VERSION ""

NS_ :

BS_:

BU_: AHL_ELCB LDM_L_ELCB LDM_R_ELCB

BO_ 3221225472 VECTOR__INDEPENDENT_SIG_MSG: 0 Vector__XXX
 SG_ FuncDiagReq : 0|64@0+ (1,0) [0|1.84467440737096E+019] "" Vector__XXX
 SG_ LftPhyDiagReq : 0|64@0+ (1,0) [0|1.84467440737096E+019] "" Vector__XXX
 SG_ RghtPhyDiagReq : 0|64@0+ (1,0) [0|1.84467440737096E+019] "" Vector__XXX
 SG_ LftPhyDiagResp : 0|64@0+ (1,0) [0|1.84467440737096E+019] "" Vector__XXX
 SG_ RghtPhyDiagResp : 0|64@0+ (1,0) [0|1.84467440737096E+019] "" Vector__XXX
 SG_ HdlmpLvlgMtrRtdCurr : 0|11@1+ (1,0) [0|2047] "" Vector__XXX

BO_ 516 StaticBendingCmd: 6 AHL_ELCB
 SG_ RtBndDim : 15|8@0+ (0.5,0) [0|0] "" Vector__XXX
 SG_ LftBndDim : 7|8@0+ (0.5,0) [0|0] "" Vector__XXX

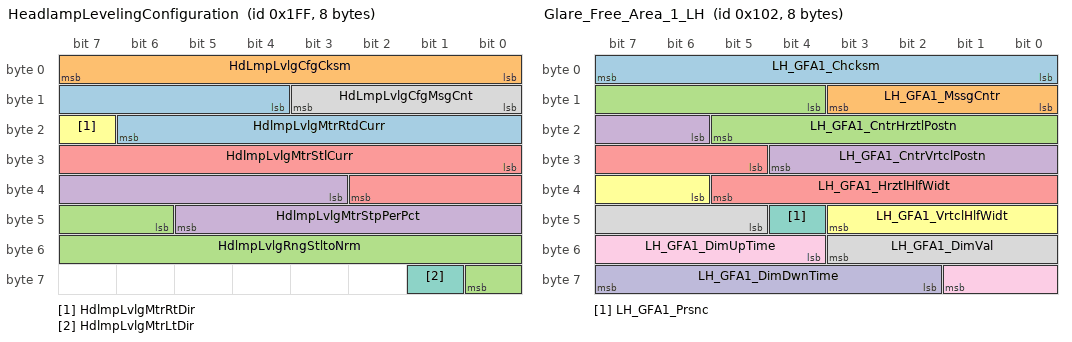
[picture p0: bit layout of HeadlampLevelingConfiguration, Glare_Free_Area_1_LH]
BO_ 511 HeadlampLevelingConfiguration: 8 AHL_ELCB
 SG_ HdlmpLvlgMtrRtdCurr : 12|11@1+ (1,0) [0|0] "" Vector__XXX
 SG_ HdLmpLvlgCfgCksm : 0|8@1+ (1,0) [0|0] "" Vector__XXX
 SG_ HdlmpLvlgRngStltoNrm : 46|11@1+ (0.01,0) [0|0] "" Vector__XXX
 SG_ HdlmpLvlgMtrStpPerPct : 35|11@1+ (1,0) [0|0] "" Vector__XXX
 SG_ HdlmpLvlgMtrStlCurr : 24|11@1- (1,0) [-1024|1023] "" Vector__XXX
 SG_ HdlmpLvlgMtrRtDir : 23|1@1+ (1,0) [0|0] "" Vector__XXX
 SG_ HdlmpLvlgMtrLtDir : 57|1@1+ (1,0) [0|0] "" Vector__XXX
 SG_ HdLmpLvlgCfgMsgCnt : 8|4@1+ (1,0) [0|0] "" Vector__XXX

BO_ 258 Glare_Free_Area_1_LH: 8 AHL_ELCB
 SG_ LH_GFA1_Chcksm : 0|8@1+ (1,0) [0|255] ""  LDM_L_ELCB,LDM_R_ELCB
 SG_ LH_GFA1_MssgCntr : 8|4@1+ (1,0) [0|15] ""  LDM_L_ELCB,LDM_R_ELCB
 SG_ LH_GFA1_CntrHrztlPostn : 12|10@1- (0.1,0) [-51.2|51.1] "deg"  LDM_L_ELCB,LDM_R_ELCB
 SG_ LH_GFA1_CntrVrtclPostn : 22|7@1- (0.1,0) [-6.4|6.3] "deg"  LDM_L_ELCB,LDM_R_ELCB
 SG_ LH_GFA1_HrztlHlfWidt : 29|9@1+ (0.1,0) [0|51.1] "deg"  LDM_L_ELCB,LDM_R_ELCB
 SG_ LH_GFA1_VrtclHlfWidt : 38|6@1+ (0.1,0) [0|6.3] "deg"  LDM_L_ELCB,LDM_R_ELCB
 SG_ LH_GFA1_Prsnc : 44|1@1+ (1,0) [0|1] ""  LDM_L_ELCB,LDM_R_ELCB
 SG_ LH_GFA1_DimVal : 45|7@1+ (1,0) [0|100] "%"  LDM_L_ELCB,LDM_R_ELCB
 SG_ LH_GFA1_DimUpTime : 52|6@1+ (0.05,0) [0|3.15] "s"  LDM_L_ELCB,LDM_R_ELCB
 SG_ LH_GFA1_DimDwnTime : 58|6@1+ (0.05,0) [0|3.15] "s"  LDM_L_ELCB,LDM_R_ELCB

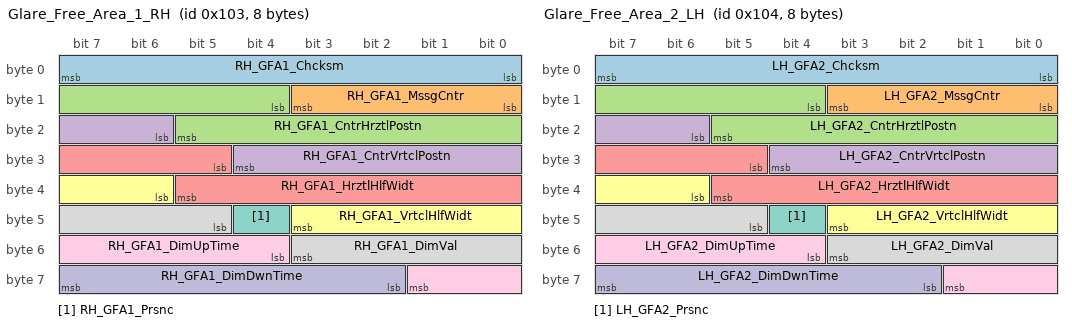
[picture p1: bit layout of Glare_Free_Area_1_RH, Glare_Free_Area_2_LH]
BO_ 259 Glare_Free_Area_1_RH: 8 AHL_ELCB
 SG_ RH_GFA1_Chcksm : 0|8@1+ (1,0) [0|255] ""  LDM_L_ELCB,LDM_R_ELCB
 SG_ RH_GFA1_MssgCntr : 8|4@1+ (1,0) [0|15] ""  LDM_L_ELCB,LDM_R_ELCB
 SG_ RH_GFA1_CntrHrztlPostn : 12|10@1- (0.1,0) [-51.2|51.1] "deg"  LDM_L_ELCB,LDM_R_ELCB
 SG_ RH_GFA1_CntrVrtclPostn : 22|7@1- (0.1,0) [-6.4|6.3] "deg"  LDM_L_ELCB,LDM_R_ELCB
 SG_ RH_GFA1_HrztlHlfWidt : 29|9@1+ (0.1,0) [0|51.1] "deg"  LDM_L_ELCB,LDM_R_ELCB
 SG_ RH_GFA1_VrtclHlfWidt : 38|6@1+ (0.1,0) [0|6.3] "deg"  LDM_L_ELCB,LDM_R_ELCB
 SG_ RH_GFA1_Prsnc : 44|1@1+ (1,0) [0|1] ""  LDM_L_ELCB,LDM_R_ELCB
 SG_ RH_GFA1_DimVal : 45|7@1+ (1,0) [0|100] "%"  LDM_L_ELCB,LDM_R_ELCB
 SG_ RH_GFA1_DimUpTime : 52|6@1+ (0.05,0) [0|3.15] "s"  LDM_L_ELCB,LDM_R_ELCB
 SG_ RH_GFA1_DimDwnTime : 58|6@1+ (0.05,0) [0|3.15] "s"  LDM_L_ELCB,LDM_R_ELCB

BO_ 260 Glare_Free_Area_2_LH: 8 AHL_ELCB
 SG_ LH_GFA2_Chcksm : 0|8@1+ (1,0) [0|255] ""  LDM_L_ELCB,LDM_R_ELCB
 SG_ LH_GFA2_MssgCntr : 8|4@1+ (1,0) [0|15] ""  LDM_L_ELCB,LDM_R_ELCB
 SG_ LH_GFA2_CntrHrztlPostn : 12|10@1- (0.1,0) [-51.2|51.1] "deg"  LDM_L_ELCB,LDM_R_ELCB
 SG_ LH_GFA2_CntrVrtclPostn : 22|7@1- (0.1,0) [-6.4|6.3] "deg"  LDM_L_ELCB,LDM_R_ELCB
 SG_ LH_GFA2_HrztlHlfWidt : 29|9@1+ (0.1,0) [0|51.1] "deg"  LDM_L_ELCB,LDM_R_ELCB
 SG_ LH_GFA2_VrtclHlfWidt : 38|6@1+ (0.1,0) [0|6.3] "deg"  LDM_L_ELCB,LDM_R_ELCB
 SG_ LH_GFA2_Prsnc : 44|1@1+ (1,0) [0|1] ""  LDM_L_ELCB,LDM_R_ELCB
 SG_ LH_GFA2_DimVal : 45|7@1+ (1,0) [0|100] "%"  LDM_L_ELCB,LDM_R_ELCB
 SG_ LH_GFA2_DimUpTime : 52|6@1+ (0.05,0) [0|3.15] "s"  LDM_L_ELCB,LDM_R_ELCB
 SG_ LH_GFA2_DimDwnTime : 58|6@1+ (0.05,0) [0|3.15] "s"  LDM_L_ELCB,LDM_R_ELCB

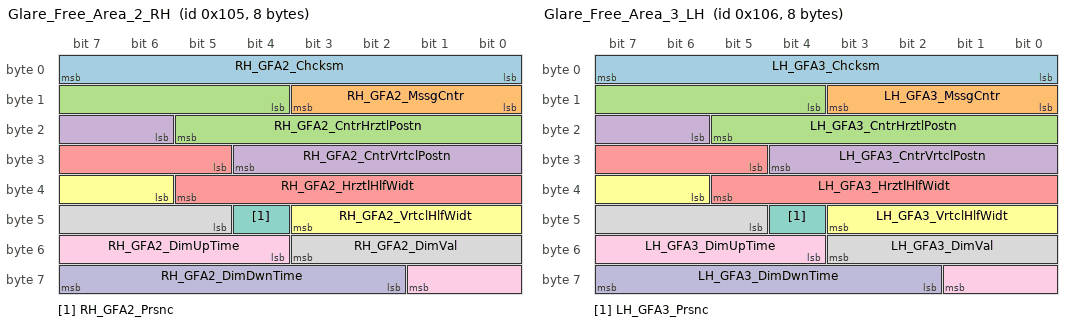
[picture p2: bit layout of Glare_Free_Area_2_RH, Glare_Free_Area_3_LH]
BO_ 261 Glare_Free_Area_2_RH: 8 AHL_ELCB
 SG_ RH_GFA2_Chcksm : 0|8@1+ (1,0) [0|255] ""  LDM_L_ELCB,LDM_R_ELCB
 SG_ RH_GFA2_MssgCntr : 8|4@1+ (1,0) [0|15] ""  LDM_L_ELCB,LDM_R_ELCB
 SG_ RH_GFA2_CntrHrztlPostn : 12|10@1- (0.1,0) [-51.2|51.1] "deg"  LDM_L_ELCB,LDM_R_ELCB
 SG_ RH_GFA2_CntrVrtclPostn : 22|7@1- (0.1,0) [-6.4|6.3] "deg"  LDM_L_ELCB,LDM_R_ELCB
 SG_ RH_GFA2_HrztlHlfWidt : 29|9@1+ (0.1,0) [0|51.1] "deg"  LDM_L_ELCB,LDM_R_ELCB
 SG_ RH_GFA2_VrtclHlfWidt : 38|6@1+ (0.1,0) [0|6.3] "deg"  LDM_L_ELCB,LDM_R_ELCB
 SG_ RH_GFA2_Prsnc : 44|1@1+ (1,0) [0|1] ""  LDM_L_ELCB,LDM_R_ELCB
 SG_ RH_GFA2_DimVal : 45|7@1+ (1,0) [0|100] "%"  LDM_L_ELCB,LDM_R_ELCB
 SG_ RH_GFA2_DimUpTime : 52|6@1+ (0.05,0) [0|3.15] "s"  LDM_L_ELCB,LDM_R_ELCB
 SG_ RH_GFA2_DimDwnTime : 58|6@1+ (0.05,0) [0|3.15] "s"  LDM_L_ELCB,LDM_R_ELCB

BO_ 262 Glare_Free_Area_3_LH: 8 AHL_ELCB
 SG_ LH_GFA3_Chcksm : 0|8@1+ (1,0) [0|255] ""  LDM_L_ELCB,LDM_R_ELCB
 SG_ LH_GFA3_MssgCntr : 8|4@1+ (1,0) [0|15] ""  LDM_L_ELCB,LDM_R_ELCB
 SG_ LH_GFA3_CntrHrztlPostn : 12|10@1- (0.1,0) [-51.2|51.1] "deg"  LDM_L_ELCB,LDM_R_ELCB
 SG_ LH_GFA3_CntrVrtclPostn : 22|7@1- (0.1,0) [-6.4|6.3] "deg"  LDM_L_ELCB,LDM_R_ELCB
 SG_ LH_GFA3_HrztlHlfWidt : 29|9@1+ (0.1,0) [0|51.1] "deg"  LDM_L_ELCB,LDM_R_ELCB
 SG_ LH_GFA3_VrtclHlfWidt : 38|6@1+ (0.1,0) [0|6.3] "deg"  LDM_L_ELCB,LDM_R_ELCB
 SG_ LH_GFA3_Prsnc : 44|1@1+ (1,0) [0|1] ""  LDM_L_ELCB,LDM_R_ELCB
 SG_ LH_GFA3_DimVal : 45|7@1+ (1,0) [0|100] "%"  LDM_L_ELCB,LDM_R_ELCB
 SG_ LH_GFA3_DimUpTime : 52|6@1+ (0.05,0) [0|3.15] "s"  LDM_L_ELCB,LDM_R_ELCB
 SG_ LH_GFA3_DimDwnTime : 58|6@1+ (0.05,0) [0|3.15] "s"  LDM_L_ELCB,LDM_R_ELCB

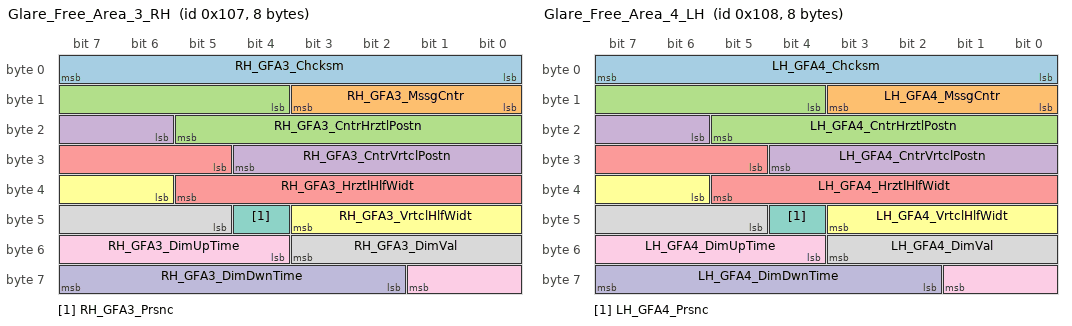
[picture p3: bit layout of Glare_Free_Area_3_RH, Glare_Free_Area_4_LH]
BO_ 263 Glare_Free_Area_3_RH: 8 AHL_ELCB
 SG_ RH_GFA3_Chcksm : 0|8@1+ (1,0) [0|255] ""  LDM_L_ELCB,LDM_R_ELCB
 SG_ RH_GFA3_MssgCntr : 8|4@1+ (1,0) [0|15] ""  LDM_L_ELCB,LDM_R_ELCB
 SG_ RH_GFA3_CntrHrztlPostn : 12|10@1- (0.1,0) [-51.2|51.1] "deg"  LDM_L_ELCB,LDM_R_ELCB
 SG_ RH_GFA3_CntrVrtclPostn : 22|7@1- (0.1,0) [-6.4|6.3] "deg"  LDM_L_ELCB,LDM_R_ELCB
 SG_ RH_GFA3_HrztlHlfWidt : 29|9@1+ (0.1,0) [0|51.1] "deg"  LDM_L_ELCB,LDM_R_ELCB
 SG_ RH_GFA3_VrtclHlfWidt : 38|6@1+ (0.1,0) [0|6.3] "deg"  LDM_L_ELCB,LDM_R_ELCB
 SG_ RH_GFA3_Prsnc : 44|1@1+ (1,0) [0|1] ""  LDM_L_ELCB,LDM_R_ELCB
 SG_ RH_GFA3_DimVal : 45|7@1+ (1,0) [0|100] "%"  LDM_L_ELCB,LDM_R_ELCB
 SG_ RH_GFA3_DimUpTime : 52|6@1+ (0.05,0) [0|3.15] "s"  LDM_L_ELCB,LDM_R_ELCB
 SG_ RH_GFA3_DimDwnTime : 58|6@1+ (0.05,0) [0|3.15] "s"  LDM_L_ELCB,LDM_R_ELCB

BO_ 264 Glare_Free_Area_4_LH: 8 AHL_ELCB
 SG_ LH_GFA4_Chcksm : 0|8@1+ (1,0) [0|255] ""  LDM_L_ELCB,LDM_R_ELCB
 SG_ LH_GFA4_MssgCntr : 8|4@1+ (1,0) [0|15] ""  LDM_L_ELCB,LDM_R_ELCB
 SG_ LH_GFA4_CntrHrztlPostn : 12|10@1- (0.1,0) [-51.2|51.1] "deg"  LDM_L_ELCB,LDM_R_ELCB
 SG_ LH_GFA4_CntrVrtclPostn : 22|7@1- (0.1,0) [-6.4|6.3] "deg"  LDM_L_ELCB,LDM_R_ELCB
 SG_ LH_GFA4_HrztlHlfWidt : 29|9@1+ (0.1,0) [0|51.1] "deg"  LDM_L_ELCB,LDM_R_ELCB
 SG_ LH_GFA4_VrtclHlfWidt : 38|6@1+ (0.1,0) [0|6.3] "deg"  LDM_L_ELCB,LDM_R_ELCB
 SG_ LH_GFA4_Prsnc : 44|1@1+ (1,0) [0|1] ""  LDM_L_ELCB,LDM_R_ELCB
 SG_ LH_GFA4_DimVal : 45|7@1+ (1,0) [0|100] "%"  LDM_L_ELCB,LDM_R_ELCB
 SG_ LH_GFA4_DimUpTime : 52|6@1+ (0.05,0) [0|3.15] "s"  LDM_L_ELCB,LDM_R_ELCB
 SG_ LH_GFA4_DimDwnTime : 58|6@1+ (0.05,0) [0|3.15] "s"  LDM_L_ELCB,LDM_R_ELCB

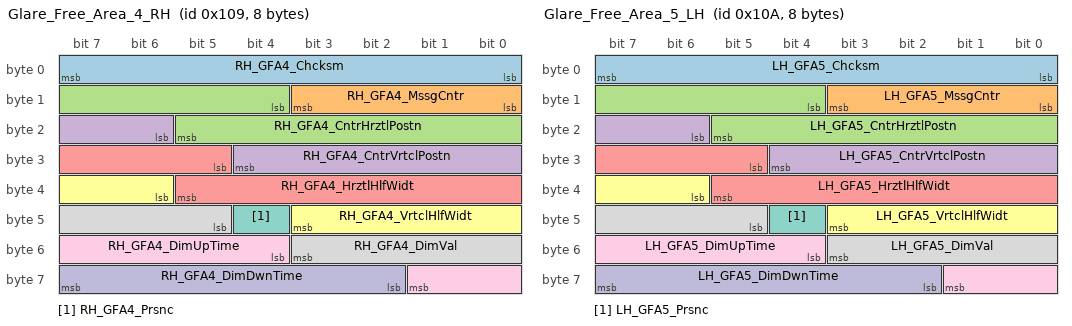
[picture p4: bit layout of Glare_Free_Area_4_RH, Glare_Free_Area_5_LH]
BO_ 265 Glare_Free_Area_4_RH: 8 AHL_ELCB
 SG_ RH_GFA4_Chcksm : 0|8@1+ (1,0) [0|255] ""  LDM_L_ELCB,LDM_R_ELCB
 SG_ RH_GFA4_MssgCntr : 8|4@1+ (1,0) [0|15] ""  LDM_L_ELCB,LDM_R_ELCB
 SG_ RH_GFA4_CntrHrztlPostn : 12|10@1- (0.1,0) [-51.2|51.1] "deg"  LDM_L_ELCB,LDM_R_ELCB
 SG_ RH_GFA4_CntrVrtclPostn : 22|7@1- (0.1,0) [-6.4|6.3] "deg"  LDM_L_ELCB,LDM_R_ELCB
 SG_ RH_GFA4_HrztlHlfWidt : 29|9@1+ (0.1,0) [0|51.1] "deg"  LDM_L_ELCB,LDM_R_ELCB
 SG_ RH_GFA4_VrtclHlfWidt : 38|6@1+ (0.1,0) [0|6.3] "deg"  LDM_L_ELCB,LDM_R_ELCB
 SG_ RH_GFA4_Prsnc : 44|1@1+ (1,0) [0|1] ""  LDM_L_ELCB,LDM_R_ELCB
 SG_ RH_GFA4_DimVal : 45|7@1+ (1,0) [0|100] "%"  LDM_L_ELCB,LDM_R_ELCB
 SG_ RH_GFA4_DimUpTime : 52|6@1+ (0.05,0) [0|3.15] "s"  LDM_L_ELCB,LDM_R_ELCB
 SG_ RH_GFA4_DimDwnTime : 58|6@1+ (0.05,0) [0|3.15] "s"  LDM_L_ELCB,LDM_R_ELCB

BO_ 266 Glare_Free_Area_5_LH: 8 AHL_ELCB
 SG_ LH_GFA5_Chcksm : 0|8@1+ (1,0) [0|255] ""  LDM_L_ELCB,LDM_R_ELCB
 SG_ LH_GFA5_MssgCntr : 8|4@1+ (1,0) [0|15] ""  LDM_L_ELCB,LDM_R_ELCB
 SG_ LH_GFA5_CntrHrztlPostn : 12|10@1- (0.1,0) [-51.2|51.1] "deg"  LDM_L_ELCB,LDM_R_ELCB
 SG_ LH_GFA5_CntrVrtclPostn : 22|7@1- (0.1,0) [-6.4|6.3] "deg"  LDM_L_ELCB,LDM_R_ELCB
 SG_ LH_GFA5_HrztlHlfWidt : 29|9@1+ (0.1,0) [0|51.1] "deg"  LDM_L_ELCB,LDM_R_ELCB
 SG_ LH_GFA5_VrtclHlfWidt : 38|6@1+ (0.1,0) [0|6.3] "deg"  LDM_L_ELCB,LDM_R_ELCB
 SG_ LH_GFA5_Prsnc : 44|1@1+ (1,0) [0|1] ""  LDM_L_ELCB,LDM_R_ELCB
 SG_ LH_GFA5_DimVal : 45|7@1+ (1,0) [0|100] "%"  LDM_L_ELCB,LDM_R_ELCB
 SG_ LH_GFA5_DimUpTime : 52|6@1+ (0.05,0) [0|3.15] "s"  LDM_L_ELCB,LDM_R_ELCB
 SG_ LH_GFA5_DimDwnTime : 58|6@1+ (0.05,0) [0|3.15] "s"  LDM_L_ELCB,LDM_R_ELCB

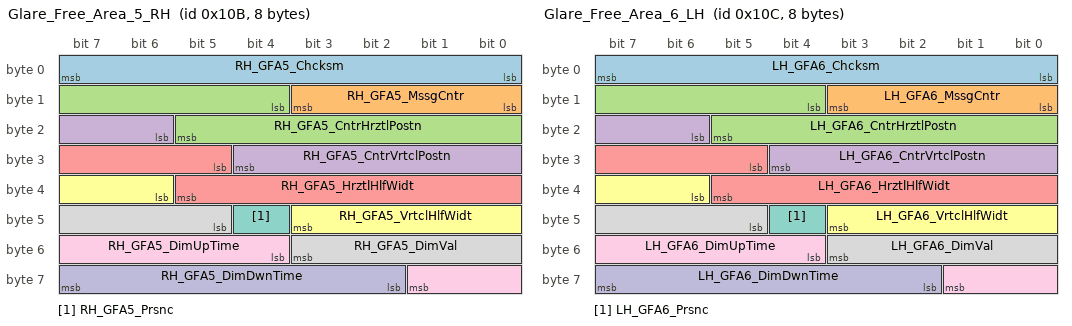
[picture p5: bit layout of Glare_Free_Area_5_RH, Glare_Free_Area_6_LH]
BO_ 267 Glare_Free_Area_5_RH: 8 AHL_ELCB
 SG_ RH_GFA5_Chcksm : 0|8@1+ (1,0) [0|255] ""  LDM_L_ELCB,LDM_R_ELCB
 SG_ RH_GFA5_MssgCntr : 8|4@1+ (1,0) [0|15] ""  LDM_L_ELCB,LDM_R_ELCB
 SG_ RH_GFA5_CntrHrztlPostn : 12|10@1- (0.1,0) [-51.2|51.1] "deg"  LDM_L_ELCB,LDM_R_ELCB
 SG_ RH_GFA5_CntrVrtclPostn : 22|7@1- (0.1,0) [-6.4|6.3] "deg"  LDM_L_ELCB,LDM_R_ELCB
 SG_ RH_GFA5_HrztlHlfWidt : 29|9@1+ (0.1,0) [0|51.1] "deg"  LDM_L_ELCB,LDM_R_ELCB
 SG_ RH_GFA5_VrtclHlfWidt : 38|6@1+ (0.1,0) [0|6.3] "deg"  LDM_L_ELCB,LDM_R_ELCB
 SG_ RH_GFA5_Prsnc : 44|1@1+ (1,0) [0|1] ""  LDM_L_ELCB,LDM_R_ELCB
 SG_ RH_GFA5_DimVal : 45|7@1+ (1,0) [0|100] "%"  LDM_L_ELCB,LDM_R_ELCB
 SG_ RH_GFA5_DimUpTime : 52|6@1+ (0.05,0) [0|3.15] "s"  LDM_L_ELCB,LDM_R_ELCB
 SG_ RH_GFA5_DimDwnTime : 58|6@1+ (0.05,0) [0|3.15] "s"  LDM_L_ELCB,LDM_R_ELCB

BO_ 268 Glare_Free_Area_6_LH: 8 AHL_ELCB
 SG_ LH_GFA6_Chcksm : 0|8@1+ (1,0) [0|255] ""  LDM_L_ELCB,LDM_R_ELCB
 SG_ LH_GFA6_MssgCntr : 8|4@1+ (1,0) [0|15] ""  LDM_L_ELCB,LDM_R_ELCB
 SG_ LH_GFA6_CntrHrztlPostn : 12|10@1- (0.1,0) [-51.2|51.1] "deg"  LDM_L_ELCB,LDM_R_ELCB
 SG_ LH_GFA6_CntrVrtclPostn : 22|7@1- (0.1,0) [-6.4|6.3] "deg"  LDM_L_ELCB,LDM_R_ELCB
 SG_ LH_GFA6_HrztlHlfWidt : 29|9@1+ (0.1,0) [0|51.1] "deg"  LDM_L_ELCB,LDM_R_ELCB
 SG_ LH_GFA6_VrtclHlfWidt : 38|6@1+ (0.1,0) [0|6.3] "deg"  LDM_L_ELCB,LDM_R_ELCB
 SG_ LH_GFA6_Prsnc : 44|1@1+ (1,0) [0|1] ""  LDM_L_ELCB,LDM_R_ELCB
 SG_ LH_GFA6_DimVal : 45|7@1+ (1,0) [0|100] "%"  LDM_L_ELCB,LDM_R_ELCB
 SG_ LH_GFA6_DimUpTime : 52|6@1+ (0.05,0) [0|3.15] "s"  LDM_L_ELCB,LDM_R_ELCB
 SG_ LH_GFA6_DimDwnTime : 58|6@1+ (0.05,0) [0|3.15] "s"  LDM_L_ELCB,LDM_R_ELCB

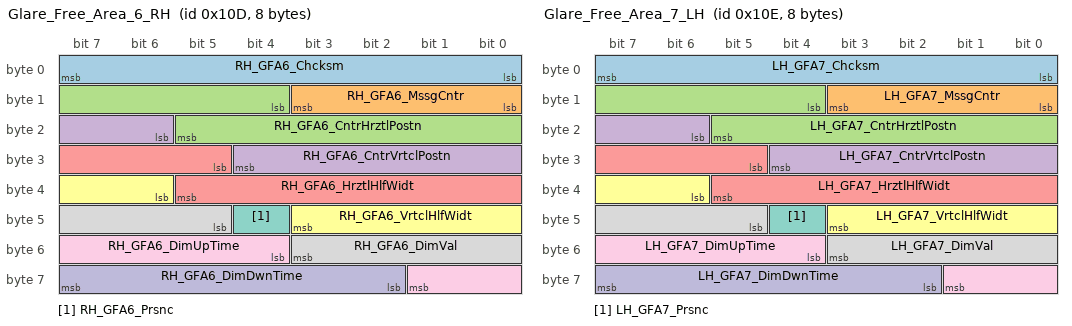
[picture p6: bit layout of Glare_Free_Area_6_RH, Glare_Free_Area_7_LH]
BO_ 269 Glare_Free_Area_6_RH: 8 AHL_ELCB
 SG_ RH_GFA6_Chcksm : 0|8@1+ (1,0) [0|255] ""  LDM_L_ELCB,LDM_R_ELCB
 SG_ RH_GFA6_MssgCntr : 8|4@1+ (1,0) [0|15] ""  LDM_L_ELCB,LDM_R_ELCB
 SG_ RH_GFA6_CntrHrztlPostn : 12|10@1- (0.1,0) [-51.2|51.1] "deg"  LDM_L_ELCB,LDM_R_ELCB
 SG_ RH_GFA6_CntrVrtclPostn : 22|7@1- (0.1,0) [-6.4|6.3] "deg"  LDM_L_ELCB,LDM_R_ELCB
 SG_ RH_GFA6_HrztlHlfWidt : 29|9@1+ (0.1,0) [0|51.1] "deg"  LDM_L_ELCB,LDM_R_ELCB
 SG_ RH_GFA6_VrtclHlfWidt : 38|6@1+ (0.1,0) [0|6.3] "deg"  LDM_L_ELCB,LDM_R_ELCB
 SG_ RH_GFA6_Prsnc : 44|1@1+ (1,0) [0|1] ""  LDM_L_ELCB,LDM_R_ELCB
 SG_ RH_GFA6_DimVal : 45|7@1+ (1,0) [0|100] "%"  LDM_L_ELCB,LDM_R_ELCB
 SG_ RH_GFA6_DimUpTime : 52|6@1+ (0.05,0) [0|3.15] "s"  LDM_L_ELCB,LDM_R_ELCB
 SG_ RH_GFA6_DimDwnTime : 58|6@1+ (0.05,0) [0|3.15] "s"  LDM_L_ELCB,LDM_R_ELCB

BO_ 270 Glare_Free_Area_7_LH: 8 AHL_ELCB
 SG_ LH_GFA7_Chcksm : 0|8@1+ (1,0) [0|255] ""  LDM_L_ELCB,LDM_R_ELCB
 SG_ LH_GFA7_MssgCntr : 8|4@1+ (1,0) [0|15] ""  LDM_L_ELCB,LDM_R_ELCB
 SG_ LH_GFA7_CntrHrztlPostn : 12|10@1- (0.1,0) [-51.2|51.1] "deg"  LDM_L_ELCB,LDM_R_ELCB
 SG_ LH_GFA7_CntrVrtclPostn : 22|7@1- (0.1,0) [-6.4|6.3] "deg"  LDM_L_ELCB,LDM_R_ELCB
 SG_ LH_GFA7_HrztlHlfWidt : 29|9@1+ (0.1,0) [0|51.1] "deg"  LDM_L_ELCB,LDM_R_ELCB
 SG_ LH_GFA7_VrtclHlfWidt : 38|6@1+ (0.1,0) [0|6.3] "deg"  LDM_L_ELCB,LDM_R_ELCB
 SG_ LH_GFA7_Prsnc : 44|1@1+ (1,0) [0|1] ""  LDM_L_ELCB,LDM_R_ELCB
 SG_ LH_GFA7_DimVal : 45|7@1+ (1,0) [0|100] "%"  LDM_L_ELCB,LDM_R_ELCB
 SG_ LH_GFA7_DimUpTime : 52|6@1+ (0.05,0) [0|3.15] "s"  LDM_L_ELCB,LDM_R_ELCB
 SG_ LH_GFA7_DimDwnTime : 58|6@1+ (0.05,0) [0|3.15] "s"  LDM_L_ELCB,LDM_R_ELCB

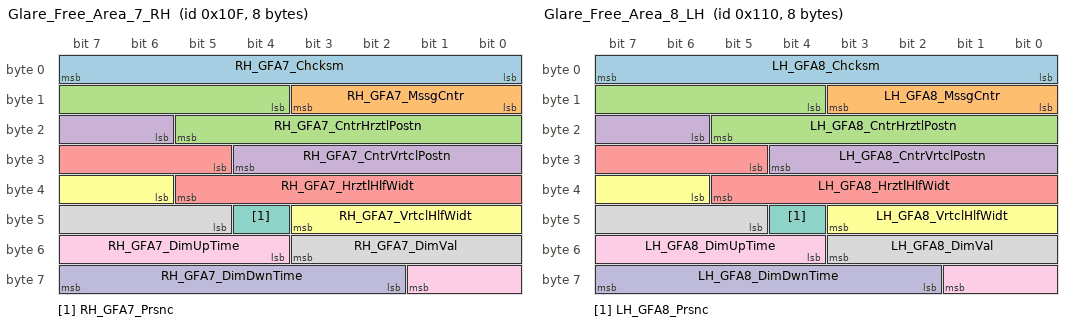
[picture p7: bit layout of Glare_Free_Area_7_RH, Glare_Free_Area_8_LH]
BO_ 271 Glare_Free_Area_7_RH: 8 AHL_ELCB
 SG_ RH_GFA7_Chcksm : 0|8@1+ (1,0) [0|255] ""  LDM_L_ELCB,LDM_R_ELCB
 SG_ RH_GFA7_MssgCntr : 8|4@1+ (1,0) [0|15] ""  LDM_L_ELCB,LDM_R_ELCB
 SG_ RH_GFA7_CntrHrztlPostn : 12|10@1- (0.1,0) [-51.2|51.1] "deg"  LDM_L_ELCB,LDM_R_ELCB
 SG_ RH_GFA7_CntrVrtclPostn : 22|7@1- (0.1,0) [-6.4|6.3] "deg"  LDM_L_ELCB,LDM_R_ELCB
 SG_ RH_GFA7_HrztlHlfWidt : 29|9@1+ (0.1,0) [0|51.1] "deg"  LDM_L_ELCB,LDM_R_ELCB
 SG_ RH_GFA7_VrtclHlfWidt : 38|6@1+ (0.1,0) [0|6.3] "deg"  LDM_L_ELCB,LDM_R_ELCB
 SG_ RH_GFA7_Prsnc : 44|1@1+ (1,0) [0|1] ""  LDM_L_ELCB,LDM_R_ELCB
 SG_ RH_GFA7_DimVal : 45|7@1+ (1,0) [0|100] "%"  LDM_L_ELCB,LDM_R_ELCB
 SG_ RH_GFA7_DimUpTime : 52|6@1+ (0.05,0) [0|3.15] "s"  LDM_L_ELCB,LDM_R_ELCB
 SG_ RH_GFA7_DimDwnTime : 58|6@1+ (0.05,0) [0|3.15] "s"  LDM_L_ELCB,LDM_R_ELCB

BO_ 272 Glare_Free_Area_8_LH: 8 AHL_ELCB
 SG_ LH_GFA8_Chcksm : 0|8@1+ (1,0) [0|255] ""  LDM_L_ELCB,LDM_R_ELCB
 SG_ LH_GFA8_MssgCntr : 8|4@1+ (1,0) [0|15] ""  LDM_L_ELCB,LDM_R_ELCB
 SG_ LH_GFA8_CntrHrztlPostn : 12|10@1- (0.1,0) [-51.2|51.1] "deg"  LDM_L_ELCB,LDM_R_ELCB
 SG_ LH_GFA8_CntrVrtclPostn : 22|7@1- (0.1,0) [-6.4|6.3] "deg"  LDM_L_ELCB,LDM_R_ELCB
 SG_ LH_GFA8_HrztlHlfWidt : 29|9@1+ (0.1,0) [0|51.1] "deg"  LDM_L_ELCB,LDM_R_ELCB
 SG_ LH_GFA8_VrtclHlfWidt : 38|6@1+ (0.1,0) [0|6.3] "deg"  LDM_L_ELCB,LDM_R_ELCB
 SG_ LH_GFA8_Prsnc : 44|1@1+ (1,0) [0|1] ""  LDM_L_ELCB,LDM_R_ELCB
 SG_ LH_GFA8_DimVal : 45|7@1+ (1,0) [0|100] "%"  LDM_L_ELCB,LDM_R_ELCB
 SG_ LH_GFA8_DimUpTime : 52|6@1+ (0.05,0) [0|3.15] "s"  LDM_L_ELCB,LDM_R_ELCB
 SG_ LH_GFA8_DimDwnTime : 58|6@1+ (0.05,0) [0|3.15] "s"  LDM_L_ELCB,LDM_R_ELCB

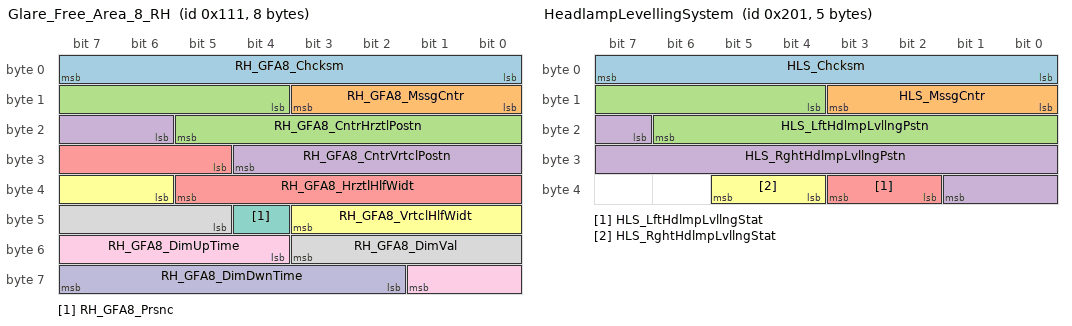
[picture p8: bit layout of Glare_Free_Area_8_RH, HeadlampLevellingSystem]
BO_ 273 Glare_Free_Area_8_RH: 8 AHL_ELCB
 SG_ RH_GFA8_Chcksm : 0|8@1+ (1,0) [0|255] ""  LDM_L_ELCB,LDM_R_ELCB
 SG_ RH_GFA8_MssgCntr : 8|4@1+ (1,0) [0|15] ""  LDM_L_ELCB,LDM_R_ELCB
 SG_ RH_GFA8_CntrHrztlPostn : 12|10@1- (0.1,0) [-51.2|51.1] "deg"  LDM_L_ELCB,LDM_R_ELCB
 SG_ RH_GFA8_CntrVrtclPostn : 22|7@1- (0.1,0) [-6.4|6.3] "deg"  LDM_L_ELCB,LDM_R_ELCB
 SG_ RH_GFA8_HrztlHlfWidt : 29|9@1+ (0.1,0) [0|51.1] "deg"  LDM_L_ELCB,LDM_R_ELCB
 SG_ RH_GFA8_VrtclHlfWidt : 38|6@1+ (0.1,0) [0|6.3] "deg"  LDM_L_ELCB,LDM_R_ELCB
 SG_ RH_GFA8_Prsnc : 44|1@1+ (1,0) [0|1] ""  LDM_L_ELCB,LDM_R_ELCB
 SG_ RH_GFA8_DimVal : 45|7@1+ (1,0) [0|100] "%"  LDM_L_ELCB,LDM_R_ELCB
 SG_ RH_GFA8_DimUpTime : 52|6@1+ (0.05,0) [0|3.15] "s"  LDM_L_ELCB,LDM_R_ELCB
 SG_ RH_GFA8_DimDwnTime : 58|6@1+ (0.05,0) [0|3.15] "s"  LDM_L_ELCB,LDM_R_ELCB

BO_ 513 HeadlampLevellingSystem: 5 AHL_ELCB
 SG_ HLS_Chcksm : 0|8@1+ (1,0) [0|255] ""  LDM_L_ELCB,LDM_R_ELCB
 SG_ HLS_MssgCntr : 8|4@1+ (1,0) [0|15] ""  LDM_L_ELCB,LDM_R_ELCB
 SG_ HLS_LftHdlmpLvllngPstn : 12|11@1- (0.01,0) [-10.24|10.23] "%"  LDM_L_ELCB,LDM_R_ELCB
 SG_ HLS_RghtHdlmpLvllngPstn : 23|11@1- (0.01,0) [-10.24|10.23] "%"  LDM_L_ELCB,LDM_R_ELCB
 SG_ HLS_LftHdlmpLvllngStat : 34|2@1+ (1,0) [0|3] ""  LDM_L_ELCB,LDM_R_ELCB
 SG_ HLS_RghtHdlmpLvllngStat : 36|2@1+ (1,0) [0|3] ""  LDM_L_ELCB,LDM_R_ELCB

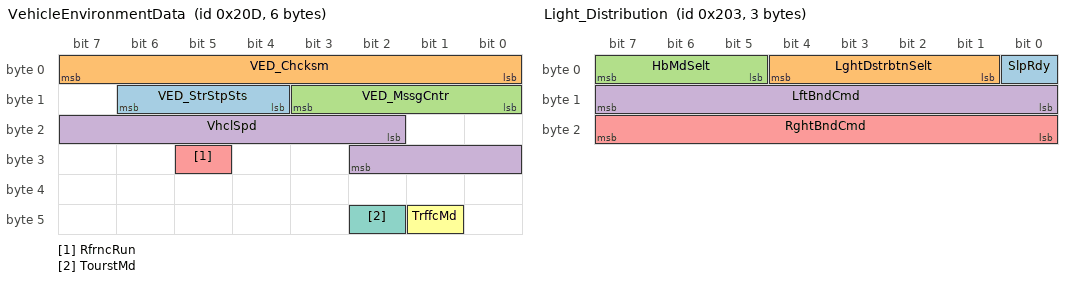
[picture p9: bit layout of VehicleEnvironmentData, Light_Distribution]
BO_ 525 VehicleEnvironmentData: 6 AHL_ELCB
 SG_ VED_StrStpSts : 12|3@1+ (1,0) [0|0] "" Vector__XXX
 SG_ VED_Chcksm : 0|8@1+ (1,0) [0|255] ""  LDM_L_ELCB,LDM_R_ELCB
 SG_ VED_MssgCntr : 8|4@1+ (1,0) [0|15] ""  LDM_L_ELCB,LDM_R_ELCB
 SG_ VhclSpd : 18|9@1+ (1,0) [0|511] "km/h"  LDM_L_ELCB,LDM_R_ELCB
 SG_ RfrncRun : 29|1@1+ (1,0) [0|1] ""  LDM_L_ELCB,LDM_R_ELCB
 SG_ TrffcMd : 41|1@1+ (1,0) [0|1] ""  LDM_L_ELCB,LDM_R_ELCB
 SG_ TourstMd : 42|1@1+ (1,0) [0|1] ""  LDM_L_ELCB,LDM_R_ELCB

BO_ 515 Light_Distribution: 3 AHL_ELCB
 SG_ SlpRdy : 0|1@1+ (1,0) [0|1] ""  LDM_L_ELCB,LDM_R_ELCB
 SG_ LghtDstrbtnSelt : 1|4@1+ (1,0) [0|15] ""  LDM_L_ELCB,LDM_R_ELCB
 SG_ HbMdSelt : 5|3@1+ (1,0) [0|7] ""  LDM_L_ELCB,LDM_R_ELCB
 SG_ LftBndCmd : 8|8@1+ (1,0) [0|100] ""  LDM_L_ELCB,LDM_R_ELCB
 SG_ RghtBndCmd : 16|8@1+ (1,0) [0|100] ""  LDM_L_ELCB,LDM_R_ELCB

BO_ 1026 SysSt_LevellingSystem_LH: 8 LDM_L_ELCB
 SG_ SystmStat_Chcksm_HLS_LH : 0|8@1+ (1,0) [0|255] ""  AHL_ELCB
 SG_ SystmStat_MssgCntr_HLS_LH : 8|4@1+ (1,0) [0|15] ""  AHL_ELCB
 SG_ SystmStat_ShrtCirctFail_HLS_LH : 12|1@1+ (1,0) [0|1] ""  AHL_ELCB
 SG_ SystmStat_OpnLoadFail_HLS_LH : 13|1@1+ (1,0) [0|1] ""  AHL_ELCB
 SG_ SystmStat_IntrnlSysFail_HLS_LH : 14|1@1+ (1,0) [0|1] ""  AHL_ELCB
 SG_ SystmStat_OvrVltgFail_HLS_LH : 15|1@1+ (1,0) [0|1] ""  AHL_ELCB
 SG_ SystmStat_UndVltgFail_HLS_LH : 16|1@1+ (1,0) [0|1] ""  AHL_ELCB
 SG_ SystmStat_ActutorFail_HLS_LH : 17|1@1+ (1,0) [0|1] ""  AHL_ELCB
 SG_ SystmStat_IntnlTempFail_HLS_LH : 18|1@1+ (1,0) [0|1] ""  AHL_ELCB
 SG_ SystmStat_ExtTempFail_HLS_LH : 19|1@1+ (1,0) [0|1] ""  AHL_ELCB
 SG_ SystmStat_CurntCdngFail_HLS_LH : 20|1@1+ (1,0) [0|1] ""  AHL_ELCB
 SG_ SystmStat_FanFail_HLS_LH : 21|1@1+ (1,0) [0|1] ""  AHL_ELCB
 SG_ SystmStat_MstrMsgFail_HLS_LH : 22|1@1+ (1,0) [0|1] ""  AHL_ELCB
 SG_ SystmStat_OverTempFail_HLS_LH : 23|1@1+ (1,0) [0|1] ""  AHL_ELCB
 SG_ SystmStat_IncCompFail_HLS_LH : 24|1@1+ (1,0) [0|1] ""  AHL_ELCB
 SG_ SystmStat_CSorMCFail_HLS_LH : 25|1@1+ (1,0) [0|1] ""  AHL_ELCB
 SG_ SystmStat_R_L_DtctnFail_HLS_LH : 26|1@1+ (1,0) [0|1] ""  AHL_ELCB
 SG_ SystmStat_FnctnStat_HLS_LH : 31|1@1+ (1,0) [0|1] ""  AHL_ELCB
 SG_ SystmStat_SpplyVltgVal_HLS_LH : 32|8@1+ (0.1,0) [0|25.5] "V"  AHL_ELCB
 SG_ SystmStat_ExtTempVal_HLS_LH : 40|8@1+ (1,-50) [-50|205] "degC"  AHL_ELCB
 SG_ SystmStat_IntTempVal_HLS_LH : 48|8@1+ (1,-50) [-50|205] "degC"  AHL_ELCB
 SG_ SystmStat_RefrncRunStat_HLS_LH : 56|2@1+ (1,0) [0|3] ""  AHL_ELCB
 SG_ SystmStat_DertngStat_HLS_LH : 58|2@1+ (1,0) [0|3] ""  AHL_ELCB
 SG_ SystmStat_SysCalibStat_HLS_LH : 60|2@1+ (1,0) [0|3] ""  AHL_ELCB
 SG_ SystmStat_VINStat_HLS_LH : 62|1@1+ (1,0) [0|1] ""  AHL_ELCB

BO_ 1027 SysSt_LevellingSystem_RH: 8 LDM_R_ELCB
 SG_ SystmStat_Chcksm_HLS_RH : 0|8@1+ (1,0) [0|255] ""  AHL_ELCB
 SG_ SystmStat_MssgCntr_HLS_RH : 8|4@1+ (1,0) [0|15] ""  AHL_ELCB
 SG_ SystmStat_ShrtCirctFail_HLS_RH : 12|1@1+ (1,0) [0|1] ""  AHL_ELCB
 SG_ SystmStat_OpnLoadFail_HLS_RH : 13|1@1+ (1,0) [0|1] ""  AHL_ELCB
 SG_ SystmStat_IntrnlSysFail_HLS_RH : 14|1@1+ (1,0) [0|1] ""  AHL_ELCB
 SG_ SystmStat_OvrVltgFail_HLS_RH : 15|1@1+ (1,0) [0|1] ""  AHL_ELCB
 SG_ SystmStat_UndVltgFail_HLS_RH : 16|1@1+ (1,0) [0|1] ""  AHL_ELCB
 SG_ SystmStat_ActutorFail_HLS_RH : 17|1@1+ (1,0) [0|1] ""  AHL_ELCB
 SG_ SystmStat_IntnlTempFail_HLS_RH : 18|1@1+ (1,0) [0|1] ""  AHL_ELCB
 SG_ SystmStat_ExtTempFail_HLS_RH : 19|1@1+ (1,0) [0|1] ""  AHL_ELCB
 SG_ SystmStat_CurntCdngFail_HLS_RH : 20|1@1+ (1,0) [0|1] ""  AHL_ELCB
 SG_ SystmStat_FanFail_HLS_RH : 21|1@1+ (1,0) [0|1] ""  AHL_ELCB
 SG_ SystmStat_MstrMsgFail_HLS_RH : 22|1@1+ (1,0) [0|1] ""  AHL_ELCB
 SG_ SystmStat_OverTempFail_HLS_RH : 23|1@1+ (1,0) [0|1] ""  AHL_ELCB
 SG_ SystmStat_IncCompFail_HLS_RH : 24|1@1+ (1,0) [0|1] ""  AHL_ELCB
 SG_ SystmStat_CSorMCFail_HLS_RH : 25|1@1+ (1,0) [0|1] ""  AHL_ELCB
 SG_ SystmStat_R_L_DtctnFail_HLS_RH : 26|1@1+ (1,0) [0|1] ""  AHL_ELCB
 SG_ SystmStat_FnctnStat_HLS_RH : 31|1@1+ (1,0) [0|1] ""  AHL_ELCB
 SG_ SystmStat_SpplyVltgVal_HLS_RH : 32|8@1+ (0.1,0) [0|25.5] "V"  AHL_ELCB
 SG_ SystmStat_ExtTempVal_HLS_RH : 40|8@1+ (1,-50) [-50|205] "degC"  AHL_ELCB
 SG_ SystmStat_IntTempVal_HLS_RH : 48|8@1+ (1,-50) [-50|205] "degC"  AHL_ELCB
 SG_ SystmStat_RefrncRunStat_HLS_RH : 56|2@1+ (1,0) [0|3] ""  AHL_ELCB
 SG_ SystmStat_DertngStat_HLS_RH : 58|2@1+ (1,0) [0|3] ""  AHL_ELCB
 SG_ SystmStat_SysCalibStat_HLS_RH : 60|2@1+ (1,0) [0|3] ""  AHL_ELCB
 SG_ SystmStat_VINStat_HLS_RH : 62|1@1+ (1,0) [0|1] ""  AHL_ELCB

BO_ 1554 HeadlampLevelSystem_LH_ActualPos: 2 LDM_L_ELCB
 SG_ LftHdlmpLvllngActPstn : 7|11@0- (0.01,0) [-10.24|10.23] "%"  AHL_ELCB

BO_ 1555 HeadlampLevelSystem_RH_ActualPos: 2 LDM_R_ELCB
 SG_ RtHdlmpLvllngActPstn : 7|11@0- (0.01,0) [-10.24|10.23] "%"  AHL_ELCB

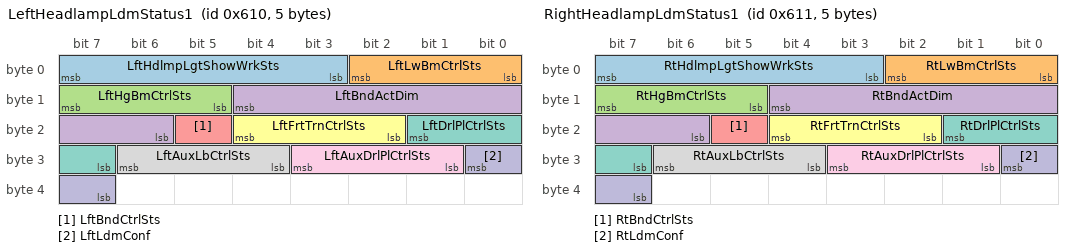
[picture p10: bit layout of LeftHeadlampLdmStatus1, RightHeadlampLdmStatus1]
BO_ 1552 LeftHeadlampLdmStatus1: 5 LDM_L_ELCB
 SG_ LftHdlmpLgtShowWrkSts : 7|5@0+ (1,0) [0|31] ""  AHL_ELCB
 SG_ LftLwBmCtrlSts : 2|3@0+ (1,0) [0|7] ""  AHL_ELCB
 SG_ LftHgBmCtrlSts : 15|3@0+ (1,0) [0|7] ""  AHL_ELCB
 SG_ LftBndActDim : 12|7@0+ (1,0) [0|127] ""  AHL_ELCB
 SG_ LftBndCtrlSts : 21|1@0+ (1,0) [0|1] ""  AHL_ELCB
 SG_ LftFrtTrnCtrlSts : 20|3@0+ (1,0) [0|7] ""  AHL_ELCB
 SG_ LftDrlPlCtrlSts : 17|3@0+ (1,0) [0|7] ""  AHL_ELCB
 SG_ LftAuxLbCtrlSts : 30|3@0+ (1,0) [0|7] ""  AHL_ELCB
 SG_ LftAuxDrlPlCtrlSts : 27|3@0+ (1,0) [0|7] ""  AHL_ELCB
 SG_ LftLdmConf : 24|2@0+ (1,0) [0|3] ""  AHL_ELCB

BO_ 1553 RightHeadlampLdmStatus1: 5 LDM_R_ELCB
 SG_ RtHdlmpLgtShowWrkSts : 7|5@0+ (1,0) [0|31] ""  AHL_ELCB
 SG_ RtLwBmCtrlSts : 2|3@0+ (1,0) [0|7] ""  AHL_ELCB
 SG_ RtHgBmCtrlSts : 15|3@0+ (1,0) [0|7] ""  AHL_ELCB
 SG_ RtBndActDim : 12|7@0+ (1,0) [0|127] ""  AHL_ELCB
 SG_ RtBndCtrlSts : 21|1@0+ (1,0) [0|1] ""  AHL_ELCB
 SG_ RtFrtTrnCtrlSts : 20|3@0+ (1,0) [0|7] ""  AHL_ELCB
 SG_ RtDrlPlCtrlSts : 17|3@0+ (1,0) [0|7] ""  AHL_ELCB
 SG_ RtAuxLbCtrlSts : 30|3@0+ (1,0) [0|7] ""  AHL_ELCB
 SG_ RtAuxDrlPlCtrlSts : 27|3@0+ (1,0) [0|7] ""  AHL_ELCB
 SG_ RtLdmConf : 24|2@0+ (1,0) [0|3] ""  AHL_ELCB

BO_ 1556 LeftHeadlampLdmStatus2: 7 LDM_L_ELCB
 SG_ SysOvErrLH : 7|1@0+ (1,0) [0|1] ""  AHL_ELCB
 SG_ SysUvErrLH : 6|1@0+ (1,0) [0|1] ""  AHL_ELCB
 SG_ BstErrLH : 5|1@0+ (1,0) [0|1] ""  AHL_ELCB
 SG_ UartCan2ErrLH : 4|2@0+ (1,0) [0|3] ""  AHL_ELCB
 SG_ UartCan1ErrLH : 2|2@0+ (1,0) [0|3] ""  AHL_ELCB
 SG_ PwrCh9ErrLH : 0|1@0+ (1,0) [0|1] ""  AHL_ELCB
 SG_ Bin8ErrLH : 15|1@0+ (1,0) [0|1] ""  AHL_ELCB
 SG_ Bin7ErrLH : 14|1@0+ (1,0) [0|1] ""  AHL_ELCB
 SG_ Bin6ErrLH : 13|1@0+ (1,0) [0|1] ""  AHL_ELCB
 SG_ Bin5ErrLH : 12|1@0+ (1,0) [0|1] ""  AHL_ELCB
 SG_ Bin4ErrLH : 11|1@0+ (1,0) [0|1] ""  AHL_ELCB
 SG_ Bin3ErrLH : 10|1@0+ (1,0) [0|1] ""  AHL_ELCB
 SG_ Bin2ErrLH : 9|1@0+ (1,0) [0|1] ""  AHL_ELCB
 SG_ Bin1ErrLH : 8|1@0+ (1,0) [0|1] ""  AHL_ELCB
 SG_ Ntc8ErrLH : 23|1@0+ (1,0) [0|1] ""  AHL_ELCB
 SG_ Ntc7ErrLH : 22|1@0+ (1,0) [0|1] ""  AHL_ELCB
 SG_ Ntc6ErrLH : 21|1@0+ (1,0) [0|1] ""  AHL_ELCB
 SG_ Ntc5ErrLH : 20|1@0+ (1,0) [0|1] ""  AHL_ELCB
 SG_ Ntc4ErrLH : 19|1@0+ (1,0) [0|1] ""  AHL_ELCB
 SG_ Ntc3ErrLH : 18|1@0+ (1,0) [0|1] ""  AHL_ELCB
 SG_ Ntc2ErrLH : 17|1@0+ (1,0) [0|1] ""  AHL_ELCB
 SG_ Ntc1ErrLH : 16|1@0+ (1,0) [0|1] ""  AHL_ELCB
 SG_ PwrCh1ErrLH : 31|1@0+ (1,0) [0|1] ""  AHL_ELCB
 SG_ PwrCh2ErrLH : 30|1@0+ (1,0) [0|1] ""  AHL_ELCB
 SG_ PwrCh3ErrLH : 29|1@0+ (1,0) [0|1] ""  AHL_ELCB
 SG_ PwrCh4ErrLH : 28|1@0+ (1,0) [0|1] ""  AHL_ELCB
 SG_ PwrCh5ErrLH : 27|1@0+ (1,0) [0|1] ""  AHL_ELCB
 SG_ PwrCh6ErrLH : 26|1@0+ (1,0) [0|1] ""  AHL_ELCB
 SG_ PwrCh7ErrLH : 25|1@0+ (1,0) [0|1] ""  AHL_ELCB
 SG_ PwrCh8ErrLH : 24|1@0+ (1,0) [0|1] ""  AHL_ELCB
 SG_ Can1BusOffLH : 39|1@0+ (1,0) [0|1] ""  AHL_ELCB
 SG_ Can1N1LstLH : 38|1@0+ (1,0) [0|1] ""  AHL_ELCB
 SG_ Can1N2LstLH : 37|1@0+ (1,0) [0|1] ""  AHL_ELCB
 SG_ Can1N3LstLH : 36|1@0+ (1,0) [0|1] ""  AHL_ELCB
 SG_ Can1N1SigErrLH : 35|1@0+ (1,0) [0|1] ""  AHL_ELCB
 SG_ Can1N2SigErrLH : 34|1@0+ (1,0) [0|1] ""  AHL_ELCB
 SG_ Can1N3SigErrLH : 33|1@0+ (1,0) [0|1] ""  AHL_ELCB
 SG_ Can2N7LstErrLH : 47|1@0+ (1,0) [0|1] ""  AHL_ELCB
 SG_ Can2N6LstErrLH : 46|1@0+ (1,0) [0|1] ""  AHL_ELCB
 SG_ Can2N5LstErrLH : 45|1@0+ (1,0) [0|1] ""  AHL_ELCB
 SG_ Can2N4LstErrLH : 44|1@0+ (1,0) [0|1] ""  AHL_ELCB
 SG_ Can2N3LstErrLH : 43|1@0+ (1,0) [0|1] ""  AHL_ELCB
 SG_ Can2N2LstErrLH : 42|1@0+ (1,0) [0|1] ""  AHL_ELCB
 SG_ Can2N1LstErrLH : 41|1@0+ (1,0) [0|1] ""  AHL_ELCB
 SG_ Can2N0LstErrLH : 40|1@0+ (1,0) [0|1] ""  AHL_ELCB
 SG_ Can2N7LedErrLH : 55|1@0+ (1,0) [0|1] ""  AHL_ELCB
 SG_ Can2N6LedErrLH : 54|1@0+ (1,0) [0|1] ""  AHL_ELCB
 SG_ Can2N5LedErrLH : 53|1@0+ (1,0) [0|1] ""  AHL_ELCB
 SG_ Can2N4LedErrLH : 52|1@0+ (1,0) [0|1] ""  AHL_ELCB
 SG_ Can2N3LedErrLH : 51|1@0+ (1,0) [0|1] ""  AHL_ELCB
 SG_ Can2N2LedErrLH : 50|1@0+ (1,0) [0|1] ""  AHL_ELCB
 SG_ Can2N1LedErrLH : 49|1@0+ (1,0) [0|1] ""  AHL_ELCB
 SG_ Can2N0LedErrLH : 48|1@0+ (1,0) [0|1] ""  AHL_ELCB

BO_ 1557 RightHeadlampLdmStatus2: 7 LDM_R_ELCB
 SG_ SysOvErrRH : 7|1@0+ (1,0) [0|1] ""  AHL_ELCB
 SG_ SysUvErrRH : 6|1@0+ (1,0) [0|1] ""  AHL_ELCB
 SG_ BstErrRH : 5|1@0+ (1,0) [0|1] ""  AHL_ELCB
 SG_ UartCan2ErrRH : 4|2@0+ (1,0) [0|3] ""  AHL_ELCB
 SG_ UartCan1ErrRH : 2|2@0+ (1,0) [0|3] ""  AHL_ELCB
 SG_ PwrCh9ErrRH : 0|1@0+ (1,0) [0|1] ""  AHL_ELCB
 SG_ Bin8ErrRH : 15|1@0+ (1,0) [0|1] ""  AHL_ELCB
 SG_ Bin7ErrRH : 14|1@0+ (1,0) [0|1] ""  AHL_ELCB
 SG_ Bin6ErrRH : 13|1@0+ (1,0) [0|1] ""  AHL_ELCB
 SG_ Bin5ErrRH : 12|1@0+ (1,0) [0|1] ""  AHL_ELCB
 SG_ Bin4ErrRH : 11|1@0+ (1,0) [0|1] ""  AHL_ELCB
 SG_ Bin3ErrRH : 10|1@0+ (1,0) [0|1] ""  AHL_ELCB
 SG_ Bin2ErrRH : 9|1@0+ (1,0) [0|1] ""  AHL_ELCB
 SG_ Bin1ErrRH : 8|1@0+ (1,0) [0|1] ""  AHL_ELCB
 SG_ Ntc8ErrRH : 23|1@0+ (1,0) [0|1] ""  AHL_ELCB
 SG_ Ntc7ErrRH : 22|1@0+ (1,0) [0|1] ""  AHL_ELCB
 SG_ Ntc6ErrRH : 21|1@0+ (1,0) [0|1] ""  AHL_ELCB
 SG_ Ntc5ErrRH : 20|1@0+ (1,0) [0|1] ""  AHL_ELCB
 SG_ Ntc4ErrRH : 19|1@0+ (1,0) [0|1] ""  AHL_ELCB
 SG_ Ntc3ErrRH : 18|1@0+ (1,0) [0|1] ""  AHL_ELCB
 SG_ Ntc2ErrRH : 17|1@0+ (1,0) [0|1] ""  AHL_ELCB
 SG_ Ntc1ErrRH : 16|1@0+ (1,0) [0|1] ""  AHL_ELCB
 SG_ PwrCh1ErrRH : 31|1@0+ (1,0) [0|1] ""  AHL_ELCB
 SG_ PwrCh2ErrRH : 30|1@0+ (1,0) [0|1] ""  AHL_ELCB
 SG_ PwrCh3ErrRH : 29|1@0+ (1,0) [0|1] ""  AHL_ELCB
 SG_ PwrCh4ErrRH : 28|1@0+ (1,0) [0|1] ""  AHL_ELCB
 SG_ PwrCh5ErrRH : 27|1@0+ (1,0) [0|1] ""  AHL_ELCB
 SG_ PwrCh6ErrRH : 26|1@0+ (1,0) [0|1] ""  AHL_ELCB
 SG_ PwrCh7ErrRH : 25|1@0+ (1,0) [0|1] ""  AHL_ELCB
 SG_ PwrCh8ErrRH : 24|1@0+ (1,0) [0|1] ""  AHL_ELCB
 SG_ Can1BusOffRH : 39|1@0+ (1,0) [0|1] ""  AHL_ELCB
 SG_ Can1N1LstRH : 38|1@0+ (1,0) [0|1] ""  AHL_ELCB
 SG_ Can1N2LstRH : 37|1@0+ (1,0) [0|1] ""  AHL_ELCB
 SG_ Can1N3LstRH : 36|1@0+ (1,0) [0|1] ""  AHL_ELCB
 SG_ Can1N1SigErrRH : 35|1@0+ (1,0) [0|1] ""  AHL_ELCB
 SG_ Can1N2SigErrRH : 34|1@0+ (1,0) [0|1] ""  AHL_ELCB
 SG_ Can1N3SigErrRH : 33|1@0+ (1,0) [0|1] ""  AHL_ELCB
 SG_ Can2N7LstErrRH : 47|1@0+ (1,0) [0|1] ""  AHL_ELCB
 SG_ Can2N6LstErrRH : 46|1@0+ (1,0) [0|1] ""  AHL_ELCB
 SG_ Can2N5LstErrRH : 45|1@0+ (1,0) [0|1] ""  AHL_ELCB
 SG_ Can2N4LstErrRH : 44|1@0+ (1,0) [0|1] ""  AHL_ELCB
 SG_ Can2N3LstErrRH : 43|1@0+ (1,0) [0|1] ""  AHL_ELCB
 SG_ Can2N2LstErrRH : 42|1@0+ (1,0) [0|1] ""  AHL_ELCB
 SG_ Can2N1LstErrRH : 41|1@0+ (1,0) [0|1] ""  AHL_ELCB
 SG_ Can2N0LstErrRH : 40|1@0+ (1,0) [0|1] ""  AHL_ELCB
 SG_ Can2N7LedErrRH : 55|1@0+ (1,0) [0|1] ""  AHL_ELCB
 SG_ Can2N6LedErrRH : 54|1@0+ (1,0) [0|1] ""  AHL_ELCB
 SG_ Can2N5LedErrRH : 53|1@0+ (1,0) [0|1] ""  AHL_ELCB
 SG_ Can2N4LedErrRH : 52|1@0+ (1,0) [0|1] ""  AHL_ELCB
 SG_ Can2N3LedErrRH : 51|1@0+ (1,0) [0|1] ""  AHL_ELCB
 SG_ Can2N2LedErrRH : 50|1@0+ (1,0) [0|1] ""  AHL_ELCB
 SG_ Can2N1LedErrRH : 49|1@0+ (1,0) [0|1] ""  AHL_ELCB
 SG_ Can2N0LedErrRH : 48|1@0+ (1,0) [0|1] ""  AHL_ELCB

BO_ 393 Exterior_FrontLightingShow: 6 AHL_ELCB
 SG_ FrtLtShwMode : 7|5@0+ (1,0) [0|31] ""  LDM_L_ELCB,LDM_R_ELCB
 SG_ FrtLtShwType : 2|3@0+ (1,0) [0|7] ""  LDM_L_ELCB,LDM_R_ELCB

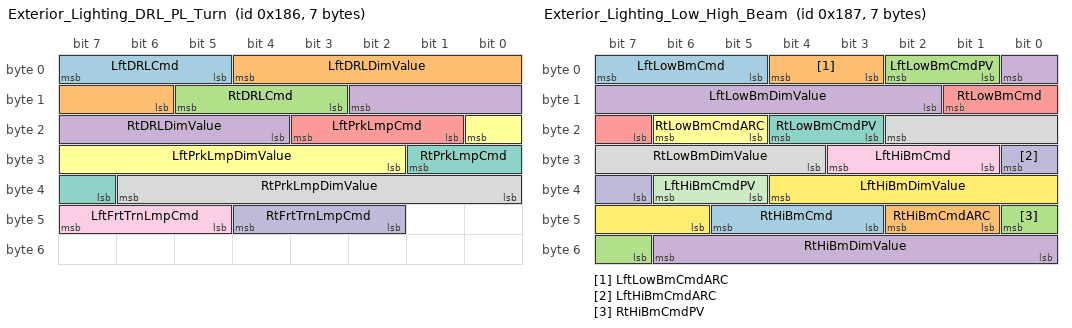
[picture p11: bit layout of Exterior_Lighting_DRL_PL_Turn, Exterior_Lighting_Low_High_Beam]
BO_ 390 Exterior_Lighting_DRL_PL_Turn: 7 AHL_ELCB
 SG_ LftDRLCmd : 7|3@0+ (1,0) [0|7] ""  LDM_L_ELCB,LDM_R_ELCB
 SG_ LftDRLDimValue : 4|7@0+ (1,0) [0|100] ""  LDM_L_ELCB,LDM_R_ELCB
 SG_ RtDRLCmd : 13|3@0+ (1,0) [0|7] ""  LDM_L_ELCB,LDM_R_ELCB
 SG_ RtDRLDimValue : 10|7@0+ (1,0) [0|100] ""  LDM_L_ELCB,LDM_R_ELCB
 SG_ LftPrkLmpCmd : 19|3@0+ (1,0) [0|7] ""  LDM_L_ELCB,LDM_R_ELCB
 SG_ LftPrkLmpDimValue : 16|7@0+ (1,0) [0|100] ""  LDM_L_ELCB,LDM_R_ELCB
 SG_ RtPrkLmpCmd : 25|3@0+ (1,0) [0|7] ""  LDM_L_ELCB,LDM_R_ELCB
 SG_ RtPrkLmpDimValue : 38|7@0+ (1,0) [0|100] ""  LDM_L_ELCB,LDM_R_ELCB
 SG_ LftFrtTrnLmpCmd : 47|3@0+ (1,0) [0|7] ""  LDM_L_ELCB,LDM_R_ELCB
 SG_ RtFrtTrnLmpCmd : 44|3@0+ (1,0) [0|7] ""  LDM_L_ELCB,LDM_R_ELCB

BO_ 391 Exterior_Lighting_Low_High_Beam: 7 AHL_ELCB
 SG_ LftLowBmCmd : 7|3@0+ (1,0) [0|7] ""  LDM_L_ELCB,LDM_R_ELCB
 SG_ LftLowBmCmdARC : 4|2@0+ (1,0) [0|3] ""  LDM_L_ELCB,LDM_R_ELCB
 SG_ LftLowBmCmdPV : 2|2@0+ (1,0) [0|3] ""  LDM_L_ELCB,LDM_R_ELCB
 SG_ LftLowBmDimValue : 0|7@0+ (1,0) [0|100] ""  LDM_L_ELCB,LDM_R_ELCB
 SG_ RtLowBmCmd : 9|3@0+ (1,0) [0|7] ""  LDM_L_ELCB,LDM_R_ELCB
 SG_ RtLowBmCmdARC : 22|2@0+ (1,0) [0|3] ""  LDM_L_ELCB,LDM_R_ELCB
 SG_ RtLowBmCmdPV : 20|2@0+ (1,0) [0|3] ""  LDM_L_ELCB,LDM_R_ELCB
 SG_ RtLowBmDimValue : 18|7@0+ (1,0) [0|100] ""  LDM_L_ELCB,LDM_R_ELCB
 SG_ LftHiBmCmd : 27|3@0+ (1,0) [0|7] ""  LDM_L_ELCB,LDM_R_ELCB
 SG_ LftHiBmCmdARC : 24|2@0+ (1,0) [0|3] ""  LDM_L_ELCB,LDM_R_ELCB
 SG_ LftHiBmCmdPV : 38|2@0+ (1,0) [0|3] ""  LDM_L_ELCB,LDM_R_ELCB
 SG_ LftHiBmDimValue : 36|7@0+ (1,0) [0|100] ""  LDM_L_ELCB,LDM_R_ELCB
 SG_ RtHiBmCmd : 45|3@0+ (1,0) [0|7] ""  LDM_L_ELCB,LDM_R_ELCB
 SG_ RtHiBmCmdARC : 42|2@0+ (1,0) [0|3] ""  LDM_L_ELCB,LDM_R_ELCB
 SG_ RtHiBmCmdPV : 40|2@0+ (1,0) [0|3] ""  LDM_L_ELCB,LDM_R_ELCB
 SG_ RtHiBmDimValue : 54|7@0+ (1,0) [0|100] ""  LDM_L_ELCB,LDM_R_ELCB

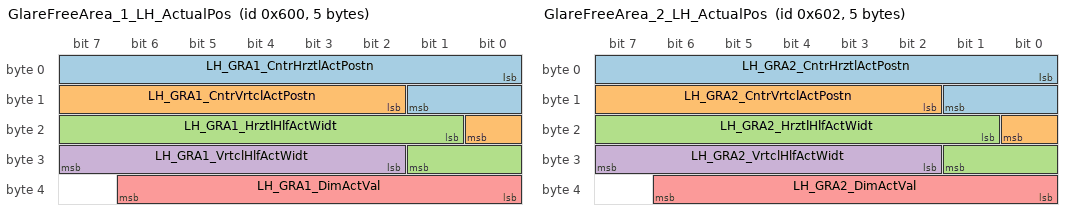
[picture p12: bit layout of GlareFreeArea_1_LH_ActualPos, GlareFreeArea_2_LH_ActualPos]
BO_ 1536 GlareFreeArea_1_LH_ActualPos: 5 LDM_L_ELCB
 SG_ LH_GRA1_CntrHrztlActPostn : 0|10@1- (0.1,0) [-51.2|51.1] "deg"  AHL_ELCB
 SG_ LH_GRA1_CntrVrtclActPostn : 10|7@1- (0.1,0) [-6.4|6.3] "deg"  AHL_ELCB
 SG_ LH_GRA1_HrztlHlfActWidt : 17|9@1+ (0.1,0) [0|51.1] "deg"  AHL_ELCB
 SG_ LH_GRA1_VrtclHlfActWidt : 26|6@1+ (0.1,0) [0|6.3] "deg"  AHL_ELCB
 SG_ LH_GRA1_DimActVal : 32|7@1+ (1,0) [0|100] "%"  AHL_ELCB

BO_ 1538 GlareFreeArea_2_LH_ActualPos: 5 LDM_L_ELCB
 SG_ LH_GRA2_CntrHrztlActPostn : 0|10@1- (0.1,0) [-51.2|51.1] "deg"  AHL_ELCB
 SG_ LH_GRA2_CntrVrtclActPostn : 10|7@1- (0.1,0) [-6.4|6.3] "deg"  AHL_ELCB
 SG_ LH_GRA2_HrztlHlfActWidt : 17|9@1+ (0.1,0) [0|51.1] "deg"  AHL_ELCB
 SG_ LH_GRA2_VrtclHlfActWidt : 26|6@1+ (0.1,0) [0|6.3] "deg"  AHL_ELCB
 SG_ LH_GRA2_DimActVal : 32|7@1+ (1,0) [0|100] "%"  AHL_ELCB

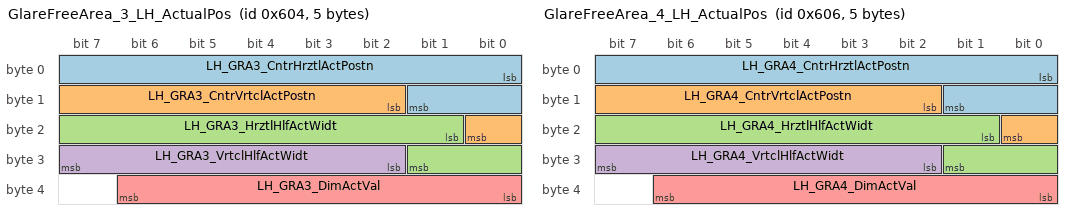
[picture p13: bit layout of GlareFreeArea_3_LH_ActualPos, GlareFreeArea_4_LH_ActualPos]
BO_ 1540 GlareFreeArea_3_LH_ActualPos: 5 LDM_L_ELCB
 SG_ LH_GRA3_CntrHrztlActPostn : 0|10@1- (0.1,0) [-51.2|51.1] "deg"  AHL_ELCB
 SG_ LH_GRA3_CntrVrtclActPostn : 10|7@1- (0.1,0) [-6.4|6.3] "deg"  AHL_ELCB
 SG_ LH_GRA3_HrztlHlfActWidt : 17|9@1+ (0.1,0) [0|51.1] "deg"  AHL_ELCB
 SG_ LH_GRA3_VrtclHlfActWidt : 26|6@1+ (0.1,0) [0|6.3] "deg"  AHL_ELCB
 SG_ LH_GRA3_DimActVal : 32|7@1+ (1,0) [0|100] "%"  AHL_ELCB

BO_ 1542 GlareFreeArea_4_LH_ActualPos: 5 LDM_L_ELCB
 SG_ LH_GRA4_CntrHrztlActPostn : 0|10@1- (0.1,0) [-51.2|51.1] "deg"  AHL_ELCB
 SG_ LH_GRA4_CntrVrtclActPostn : 10|7@1- (0.1,0) [-6.4|6.3] "deg"  AHL_ELCB
 SG_ LH_GRA4_HrztlHlfActWidt : 17|9@1+ (0.1,0) [0|51.1] "deg"  AHL_ELCB
 SG_ LH_GRA4_VrtclHlfActWidt : 26|6@1+ (0.1,0) [0|6.3] "deg"  AHL_ELCB
 SG_ LH_GRA4_DimActVal : 32|7@1+ (1,0) [0|100] "%"  AHL_ELCB

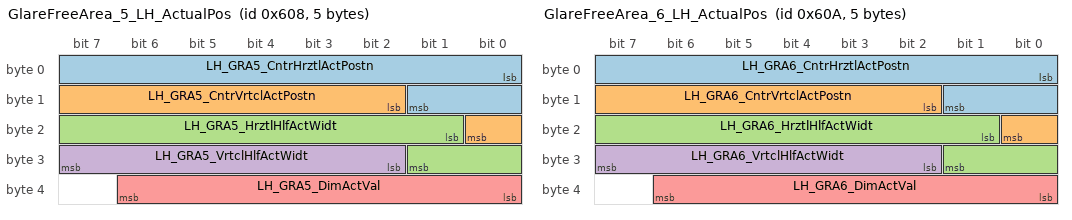
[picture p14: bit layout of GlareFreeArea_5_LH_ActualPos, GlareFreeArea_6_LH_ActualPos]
BO_ 1544 GlareFreeArea_5_LH_ActualPos: 5 LDM_L_ELCB
 SG_ LH_GRA5_CntrHrztlActPostn : 0|10@1- (0.1,0) [-51.2|51.1] "deg"  AHL_ELCB
 SG_ LH_GRA5_CntrVrtclActPostn : 10|7@1- (0.1,0) [-6.4|6.3] "deg"  AHL_ELCB
 SG_ LH_GRA5_HrztlHlfActWidt : 17|9@1+ (0.1,0) [0|51.1] "deg"  AHL_ELCB
 SG_ LH_GRA5_VrtclHlfActWidt : 26|6@1+ (0.1,0) [0|6.3] "deg"  AHL_ELCB
 SG_ LH_GRA5_DimActVal : 32|7@1+ (1,0) [0|100] "%"  AHL_ELCB

BO_ 1546 GlareFreeArea_6_LH_ActualPos: 5 LDM_L_ELCB
 SG_ LH_GRA6_CntrHrztlActPostn : 0|10@1- (0.1,0) [-51.2|51.1] "deg"  AHL_ELCB
 SG_ LH_GRA6_CntrVrtclActPostn : 10|7@1- (0.1,0) [-6.4|6.3] "deg"  AHL_ELCB
 SG_ LH_GRA6_HrztlHlfActWidt : 17|9@1+ (0.1,0) [0|51.1] "deg"  AHL_ELCB
 SG_ LH_GRA6_VrtclHlfActWidt : 26|6@1+ (0.1,0) [0|6.3] "deg"  AHL_ELCB
 SG_ LH_GRA6_DimActVal : 32|7@1+ (1,0) [0|100] "%"  AHL_ELCB

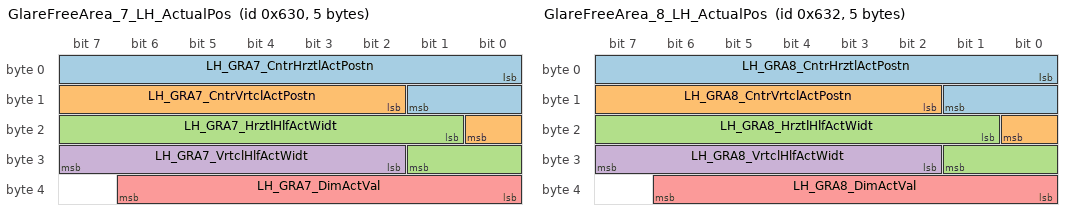
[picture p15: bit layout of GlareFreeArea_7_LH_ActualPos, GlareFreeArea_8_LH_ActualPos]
BO_ 1584 GlareFreeArea_7_LH_ActualPos: 5 LDM_L_ELCB
 SG_ LH_GRA7_CntrHrztlActPostn : 0|10@1- (0.1,0) [-51.2|51.1] "deg"  AHL_ELCB
 SG_ LH_GRA7_CntrVrtclActPostn : 10|7@1- (0.1,0) [-6.4|6.3] "deg"  AHL_ELCB
 SG_ LH_GRA7_HrztlHlfActWidt : 17|9@1+ (0.1,0) [0|51.1] "deg"  AHL_ELCB
 SG_ LH_GRA7_VrtclHlfActWidt : 26|6@1+ (0.1,0) [0|6.3] "deg"  AHL_ELCB
 SG_ LH_GRA7_DimActVal : 32|7@1+ (1,0) [0|100] "%"  AHL_ELCB

BO_ 1586 GlareFreeArea_8_LH_ActualPos: 5 LDM_L_ELCB
 SG_ LH_GRA8_CntrHrztlActPostn : 0|10@1- (0.1,0) [-51.2|51.1] "deg"  AHL_ELCB
 SG_ LH_GRA8_CntrVrtclActPostn : 10|7@1- (0.1,0) [-6.4|6.3] "deg"  AHL_ELCB
 SG_ LH_GRA8_HrztlHlfActWidt : 17|9@1+ (0.1,0) [0|51.1] "deg"  AHL_ELCB
 SG_ LH_GRA8_VrtclHlfActWidt : 26|6@1+ (0.1,0) [0|6.3] "deg"  AHL_ELCB
 SG_ LH_GRA8_DimActVal : 32|7@1+ (1,0) [0|100] "%"  AHL_ELCB

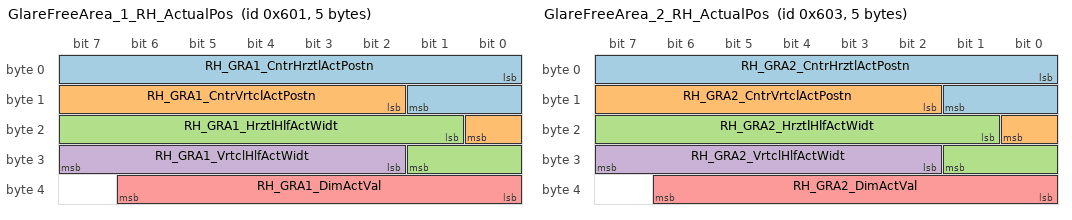
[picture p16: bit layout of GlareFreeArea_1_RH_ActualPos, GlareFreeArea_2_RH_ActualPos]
BO_ 1537 GlareFreeArea_1_RH_ActualPos: 5 LDM_R_ELCB
 SG_ RH_GRA1_CntrHrztlActPostn : 0|10@1- (0.1,0) [-51.2|51.1] "deg"  AHL_ELCB
 SG_ RH_GRA1_CntrVrtclActPostn : 10|7@1- (0.1,0) [-6.4|6.3] "deg"  AHL_ELCB
 SG_ RH_GRA1_HrztlHlfActWidt : 17|9@1+ (0.1,0) [0|51.1] "deg"  AHL_ELCB
 SG_ RH_GRA1_VrtclHlfActWidt : 26|6@1+ (0.1,0) [0|6.3] "deg"  AHL_ELCB
 SG_ RH_GRA1_DimActVal : 32|7@1+ (1,0) [0|100] "%"  AHL_ELCB

BO_ 1539 GlareFreeArea_2_RH_ActualPos: 5 LDM_R_ELCB
 SG_ RH_GRA2_CntrHrztlActPostn : 0|10@1- (0.1,0) [-51.2|51.1] "deg"  AHL_ELCB
 SG_ RH_GRA2_CntrVrtclActPostn : 10|7@1- (0.1,0) [-6.4|6.3] "deg"  AHL_ELCB
 SG_ RH_GRA2_HrztlHlfActWidt : 17|9@1+ (0.1,0) [0|51.1] "deg"  AHL_ELCB
 SG_ RH_GRA2_VrtclHlfActWidt : 26|6@1+ (0.1,0) [0|6.3] "deg"  AHL_ELCB
 SG_ RH_GRA2_DimActVal : 32|7@1+ (1,0) [0|100] "%"  AHL_ELCB

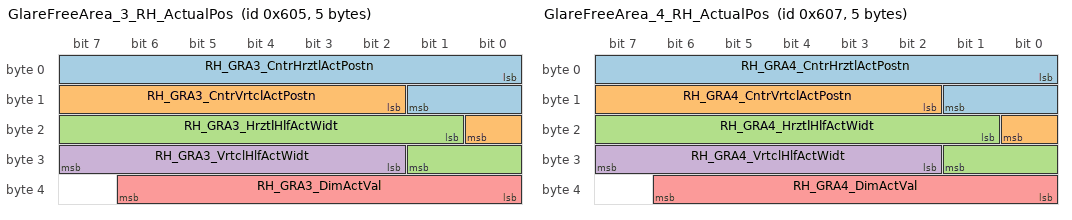
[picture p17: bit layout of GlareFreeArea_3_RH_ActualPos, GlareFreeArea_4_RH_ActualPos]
BO_ 1541 GlareFreeArea_3_RH_ActualPos: 5 LDM_R_ELCB
 SG_ RH_GRA3_CntrHrztlActPostn : 0|10@1- (0.1,0) [-51.2|51.1] "deg"  AHL_ELCB
 SG_ RH_GRA3_CntrVrtclActPostn : 10|7@1- (0.1,0) [-6.4|6.3] "deg"  AHL_ELCB
 SG_ RH_GRA3_HrztlHlfActWidt : 17|9@1+ (0.1,0) [0|51.1] "deg"  AHL_ELCB
 SG_ RH_GRA3_VrtclHlfActWidt : 26|6@1+ (0.1,0) [0|6.3] "deg"  AHL_ELCB
 SG_ RH_GRA3_DimActVal : 32|7@1+ (1,0) [0|100] "%"  AHL_ELCB

BO_ 1543 GlareFreeArea_4_RH_ActualPos: 5 LDM_R_ELCB
 SG_ RH_GRA4_CntrHrztlActPostn : 0|10@1- (0.1,0) [-51.2|51.1] "deg"  AHL_ELCB
 SG_ RH_GRA4_CntrVrtclActPostn : 10|7@1- (0.1,0) [-6.4|6.3] "deg"  AHL_ELCB
 SG_ RH_GRA4_HrztlHlfActWidt : 17|9@1+ (0.1,0) [0|51.1] "deg"  AHL_ELCB
 SG_ RH_GRA4_VrtclHlfActWidt : 26|6@1+ (0.1,0) [0|6.3] "deg"  AHL_ELCB
 SG_ RH_GRA4_DimActVal : 32|7@1+ (1,0) [0|100] "%"  AHL_ELCB

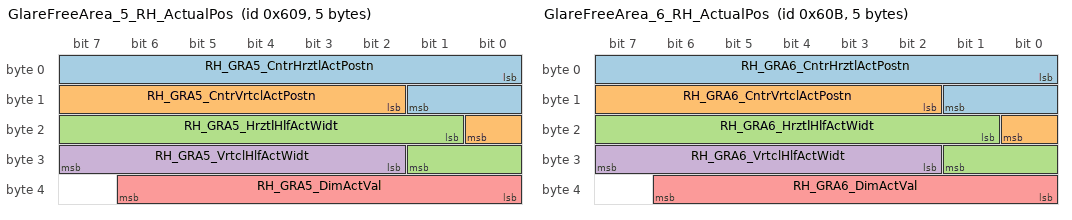
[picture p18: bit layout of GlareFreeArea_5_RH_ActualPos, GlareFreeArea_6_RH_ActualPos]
BO_ 1545 GlareFreeArea_5_RH_ActualPos: 5 LDM_R_ELCB
 SG_ RH_GRA5_CntrHrztlActPostn : 0|10@1- (0.1,0) [-51.2|51.1] "deg"  AHL_ELCB
 SG_ RH_GRA5_CntrVrtclActPostn : 10|7@1- (0.1,0) [-6.4|6.3] "deg"  AHL_ELCB
 SG_ RH_GRA5_HrztlHlfActWidt : 17|9@1+ (0.1,0) [0|51.1] "deg"  AHL_ELCB
 SG_ RH_GRA5_VrtclHlfActWidt : 26|6@1+ (0.1,0) [0|6.3] "deg"  AHL_ELCB
 SG_ RH_GRA5_DimActVal : 32|7@1+ (1,0) [0|100] "%"  AHL_ELCB

BO_ 1547 GlareFreeArea_6_RH_ActualPos: 5 LDM_R_ELCB
 SG_ RH_GRA6_CntrHrztlActPostn : 0|10@1- (0.1,0) [-51.2|51.1] "deg"  AHL_ELCB
 SG_ RH_GRA6_CntrVrtclActPostn : 10|7@1- (0.1,0) [-6.4|6.3] "deg"  AHL_ELCB
 SG_ RH_GRA6_HrztlHlfActWidt : 17|9@1+ (0.1,0) [0|51.1] "deg"  AHL_ELCB
 SG_ RH_GRA6_VrtclHlfActWidt : 26|6@1+ (0.1,0) [0|6.3] "deg"  AHL_ELCB
 SG_ RH_GRA6_DimActVal : 32|7@1+ (1,0) [0|100] "%"  AHL_ELCB

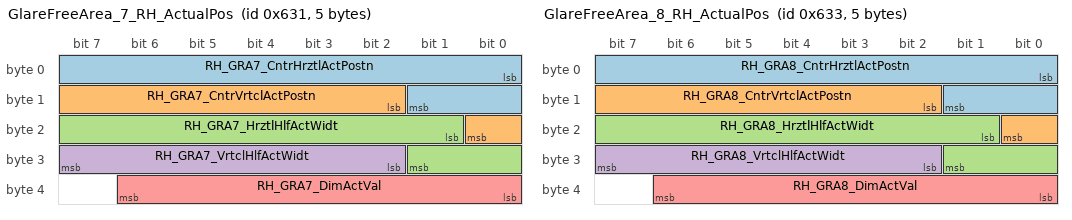
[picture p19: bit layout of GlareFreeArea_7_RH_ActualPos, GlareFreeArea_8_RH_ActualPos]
BO_ 1585 GlareFreeArea_7_RH_ActualPos: 5 LDM_R_ELCB
 SG_ RH_GRA7_CntrHrztlActPostn : 0|10@1- (0.1,0) [-51.2|51.1] "deg"  AHL_ELCB
 SG_ RH_GRA7_CntrVrtclActPostn : 10|7@1- (0.1,0) [-6.4|6.3] "deg"  AHL_ELCB
 SG_ RH_GRA7_HrztlHlfActWidt : 17|9@1+ (0.1,0) [0|51.1] "deg"  AHL_ELCB
 SG_ RH_GRA7_VrtclHlfActWidt : 26|6@1+ (0.1,0) [0|6.3] "deg"  AHL_ELCB
 SG_ RH_GRA7_DimActVal : 32|7@1+ (1,0) [0|100] "%"  AHL_ELCB

BO_ 1587 GlareFreeArea_8_RH_ActualPos: 5 LDM_R_ELCB
 SG_ RH_GRA8_CntrHrztlActPostn : 0|10@1- (0.1,0) [-51.2|51.1] "deg"  AHL_ELCB
 SG_ RH_GRA8_CntrVrtclActPostn : 10|7@1- (0.1,0) [-6.4|6.3] "deg"  AHL_ELCB
 SG_ RH_GRA8_HrztlHlfActWidt : 17|9@1+ (0.1,0) [0|51.1] "deg"  AHL_ELCB
 SG_ RH_GRA8_VrtclHlfActWidt : 26|6@1+ (0.1,0) [0|6.3] "deg"  AHL_ELCB
 SG_ RH_GRA8_DimActVal : 32|7@1+ (1,0) [0|100] "%"  AHL_ELCB

CM_ BO_ 3221225472 "This is a message for not used signals, created by Vector CANdb++ DBC OLE DB Provider.";
CM_ SG_ 525 VED_StrStpSts "0: Inactive
1: Start Stop Active
";
BA_DEF_ BU_  "ECU_Id" HEX 0 255;
BA_DEF_ BU_  "ILUsed" ENUM  "No","Yes";
BA_DEF_ BU_  "SourceId" HEX 0 255;
BA_DEF_  "NmType" STRING ;
BA_DEF_  "DBName" STRING ;
BA_DEF_  "Baudrate" INT 0 1000000;
BA_DEF_  "BusOffRecoveryTime" INT 0 65535;
BA_DEF_  "Manufacturer" STRING ;
BA_DEF_  "VersionNumber" INT 0 65535;
BA_DEF_  "SamplePointMin" FLOAT 0 100;
BA_DEF_  "SamplePointMax" FLOAT 0 100;
BA_DEF_  "SyncJumpWidthMin" INT 0 255;
BA_DEF_  "SyncJumpWidthMax" INT 0 255;
BA_DEF_  "BusType" STRING ;
BA_DEF_ BO_  "GenMsgILSupport" ENUM  "No","Yes";
BA_DEF_ BO_  "GenMsgCycleTime" INT 0 100000;
BA_DEF_ BO_  "GenMsgDelayTime" INT 0 300000;
BA_DEF_ BO_  "DiagRequest" ENUM  "No","Yes";
BA_DEF_ BO_  "DiagResponse" ENUM  "No","Yes";
BA_DEF_ BO_  "DiagState" ENUM  "No","Yes";
BA_DEF_ BO_  "MessageSubnet" ENUM  "BCB","PB","DB","CB","Body","HS","ELCB","Powertrain","Chassis","Spare","PE","CC";
BA_DEF_ BO_  "TpTxIndex" INT 0 99;
BA_DEF_ BO_  "VFrameFormat" ENUM  "StandardCAN","ExtendedCAN","reserved","reserved","reserved","reserved","reserved","reserved","reserved","reserved","reserved","reserved","reserved","reserved","StandardCAN_FD","ExtendedCAN_FD";
BA_DEF_ BO_  "DiagConnection" INT 0 100;
BA_DEF_ BO_  "GenMsgStartDelayTime" INT 0 100000;
BA_DEF_ SG_  "GenSigStartValue" INT 0 65535;
BA_DEF_ SG_  "SignalLongName" STRING ;
BA_DEF_ SG_  "SignalType" STRING ;
BA_DEF_ SG_  "GenSigSendOnInit" ENUM  "Not Initialized","Application","Handler";
BA_DEF_ BU_  "NmAsrNode" ENUM  "No","Yes";
BA_DEF_ BU_  "NmAsrNodeIdentifier" HEX 0 255;
BA_DEF_ BU_  "NmAsrCanMsgCycleOffset" INT 0 65535;
BA_DEF_ BU_  "NmAsrCanMsgReducedTime" INT 0 65535;
BA_DEF_  "NmAsrMessageCount" INT 0 256;
BA_DEF_  "NmAsrBaseAddress" HEX 0 2032;
BA_DEF_  "NmAsrTimeoutTime" INT 0 65535;
BA_DEF_  "NmAsrWaitBusSleepTime" INT 0 65535;
BA_DEF_  "NmAsrRepeatMessageTime" INT 0 65525;
BA_DEF_  "NmAsrCanMsgCycleTime" INT 0 65535;
BA_DEF_ BO_  "GenMsgSendType" ENUM  "Cyclic","NotUsed","NotUsed","NotUsed","NotUsed","NotUsed","NotUsed","NotUsed","NoMsgSendType";
BA_DEF_ BO_  "NmAsrMessage" ENUM  "No","Yes";
BA_DEF_ BO_  "DiagUUDTResponse" ENUM  "No","Yes";
BA_DEF_ SG_  "GenSigSendType" ENUM  "NotUsed","OnWrite","OnWriteWithRepetition","OnChange","OnChangeWithRepetition","IfActive","IfActiveWithRepeition","NoSigSendType";
BA_DEF_REL_ BU_SG_REL_  "GenSigTimeoutMsg" HEX 0 2032;
BA_DEF_REL_ BU_SG_REL_  "GenSigTimeoutTime" INT 0 15000;
BA_DEF_REL_ BU_SG_REL_  "GenSigSuprvResp" ENUM  "None","Notify App","Substitute Default";
BA_DEF_REL_ BU_SG_REL_  "GenSigSuprvRespSubValue" INT 0 65535;
BA_DEF_REL_ BU_SG_REL_  "GenSigVBitResp" ENUM  "No","Yes";
BA_DEF_REL_ BU_SG_REL_  "GenSigVBitRespComment" STRING ;
BA_DEF_REL_ BU_SG_REL_  "GenSigVDAFailResp" ENUM  "No","Yes";
BA_DEF_REL_ BU_SG_REL_  "GenSigRxStartValue" STRING ;
BA_DEF_REL_ BU_SG_REL_  "GenSigVDAFailComment" STRING ;
BA_DEF_DEF_  "ECU_Id" 0;
BA_DEF_DEF_  "ILUsed" "Yes";
BA_DEF_DEF_  "SourceId" 0;
BA_DEF_DEF_  "NmType" "HSCAN";
BA_DEF_DEF_  "DBName" "";
BA_DEF_DEF_  "Baudrate" 500000;
BA_DEF_DEF_  "BusOffRecoveryTime" 160;
BA_DEF_DEF_  "Manufacturer" "GM";
BA_DEF_DEF_  "VersionNumber" 0;
BA_DEF_DEF_  "SamplePointMin" 81.25;
BA_DEF_DEF_  "SamplePointMax" 80;
BA_DEF_DEF_  "SyncJumpWidthMin" 4;
BA_DEF_DEF_  "SyncJumpWidthMax" 3;
BA_DEF_DEF_  "BusType" "CAN";
BA_DEF_DEF_  "GenMsgILSupport" "Yes";
BA_DEF_DEF_  "GenMsgCycleTime" 0;
BA_DEF_DEF_  "GenMsgDelayTime" 0;
BA_DEF_DEF_  "DiagRequest" "No";
BA_DEF_DEF_  "DiagResponse" "No";
BA_DEF_DEF_  "DiagState" "No";
BA_DEF_DEF_  "MessageSubnet" "Body";
BA_DEF_DEF_  "TpTxIndex" 0;
BA_DEF_DEF_  "VFrameFormat" "StandardCAN";
BA_DEF_DEF_  "DiagConnection" 0;
BA_DEF_DEF_  "GenMsgStartDelayTime" 0;
BA_DEF_DEF_  "GenSigStartValue" 0;
BA_DEF_DEF_  "SignalLongName" "";
BA_DEF_DEF_  "SignalType" "";
BA_DEF_DEF_  "GenSigSendOnInit" "Not Initialized";
BA_DEF_DEF_  "NmAsrNode" "Yes";
BA_DEF_DEF_  "NmAsrNodeIdentifier" 0;
BA_DEF_DEF_  "NmAsrCanMsgCycleOffset" 0;
BA_DEF_DEF_  "NmAsrCanMsgReducedTime" 0;
BA_DEF_DEF_  "NmAsrMessageCount" 22;
BA_DEF_DEF_  "NmAsrBaseAddress" 0;
BA_DEF_DEF_  "NmAsrTimeoutTime" 0;
BA_DEF_DEF_  "NmAsrWaitBusSleepTime" 0;
BA_DEF_DEF_  "NmAsrRepeatMessageTime" 0;
BA_DEF_DEF_  "NmAsrCanMsgCycleTime" 0;
BA_DEF_DEF_  "GenMsgSendType" "NoMsgSendType";
BA_DEF_DEF_  "NmAsrMessage" "No";
BA_DEF_DEF_  "DiagUUDTResponse" "No";
BA_DEF_DEF_  "GenSigSendType" "NoSigSendType";
BA_DEF_DEF_REL_ "GenSigTimeoutMsg" 0;
BA_DEF_DEF_REL_ "GenSigTimeoutTime" 0;
BA_DEF_DEF_REL_ "GenSigSuprvResp" "None";
BA_DEF_DEF_REL_ "GenSigSuprvRespSubValue" 0;
BA_DEF_DEF_REL_ "GenSigVBitResp" "No";
BA_DEF_DEF_REL_ "GenSigVBitRespComment" "";
BA_DEF_DEF_REL_ "GenSigVDAFailResp" "No";
BA_DEF_DEF_REL_ "GenSigRxStartValue" "";
BA_DEF_DEF_REL_ "GenSigVDAFailComment" "";
BA_ "NmType" "NmAsr";
BA_ "NmAsrMessageCount" 128;
BA_ "NmAsrBaseAddress" 1536;
BA_ "NmAsrTimeoutTime" 4000;
BA_ "NmAsrWaitBusSleepTime" 4000;
BA_ "NmAsrRepeatMessageTime" 1500;
BA_ "NmAsrCanMsgCycleTime" 640;
BA_ "Manufacturer" "Vector";
BA_ "VersionNumber" 1;
BA_ "SamplePointMin" 78.5;
BA_ "SamplePointMax" 83.4;
BA_ "SyncJumpWidthMin" 3;
BA_ "SyncJumpWidthMax" 4;
BA_ "DBName" "ELCB";
BA_ "ECU_Id" BU_ AHL_ELCB 114;
BA_ "NmAsrNodeIdentifier" BU_ AHL_ELCB 114;
BA_ "NmAsrCanMsgReducedTime" BU_ AHL_ELCB 320;
BA_ "SourceId" BU_ AHL_ELCB 114;
BA_ "ECU_Id" BU_ LDM_L_ELCB 65;
BA_ "NmAsrNodeIdentifier" BU_ LDM_L_ELCB 65;
BA_ "NmAsrCanMsgCycleOffset" BU_ LDM_L_ELCB 10;
BA_ "NmAsrCanMsgReducedTime" BU_ LDM_L_ELCB 330;
BA_ "SourceId" BU_ LDM_L_ELCB 65;
BA_ "ECU_Id" BU_ LDM_R_ELCB 66;
BA_ "NmAsrNodeIdentifier" BU_ LDM_R_ELCB 66;
BA_ "NmAsrCanMsgCycleOffset" BU_ LDM_R_ELCB 20;
BA_ "NmAsrCanMsgReducedTime" BU_ LDM_R_ELCB 340;
BA_ "SourceId" BU_ LDM_R_ELCB 66;
BA_ "GenMsgSendType" BO_ 516 0;
BA_ "GenMsgCycleTime" BO_ 516 20;
BA_ "GenMsgCycleTime" BO_ 511 40;
BA_ "GenMsgSendType" BO_ 511 0;
BA_ "MessageSubnet" BO_ 258 6;
BA_ "GenMsgCycleTime" BO_ 258 40;
BA_ "GenMsgSendType" BO_ 258 0;
BA_ "MessageSubnet" BO_ 259 6;
BA_ "GenMsgCycleTime" BO_ 259 40;
BA_ "GenMsgSendType" BO_ 259 0;
BA_ "MessageSubnet" BO_ 260 6;
BA_ "GenMsgCycleTime" BO_ 260 40;
BA_ "GenMsgSendType" BO_ 260 0;
BA_ "MessageSubnet" BO_ 261 6;
BA_ "GenMsgCycleTime" BO_ 261 40;
BA_ "GenMsgSendType" BO_ 261 0;
BA_ "MessageSubnet" BO_ 262 6;
BA_ "GenMsgCycleTime" BO_ 262 40;
BA_ "GenMsgSendType" BO_ 262 0;
BA_ "MessageSubnet" BO_ 263 6;
BA_ "GenMsgCycleTime" BO_ 263 40;
BA_ "GenMsgSendType" BO_ 263 0;
BA_ "MessageSubnet" BO_ 264 6;
BA_ "GenMsgCycleTime" BO_ 264 40;
BA_ "GenMsgSendType" BO_ 264 0;
BA_ "MessageSubnet" BO_ 265 6;
BA_ "GenMsgCycleTime" BO_ 265 40;
BA_ "GenMsgSendType" BO_ 265 0;
BA_ "MessageSubnet" BO_ 266 6;
BA_ "GenMsgCycleTime" BO_ 266 40;
BA_ "GenMsgSendType" BO_ 266 0;
BA_ "MessageSubnet" BO_ 267 6;
BA_ "GenMsgCycleTime" BO_ 267 40;
BA_ "GenMsgSendType" BO_ 267 0;
BA_ "MessageSubnet" BO_ 268 6;
BA_ "GenMsgCycleTime" BO_ 268 40;
BA_ "GenMsgSendType" BO_ 268 0;
BA_ "MessageSubnet" BO_ 269 6;
BA_ "GenMsgCycleTime" BO_ 269 40;
BA_ "GenMsgSendType" BO_ 269 0;
BA_ "MessageSubnet" BO_ 270 6;
BA_ "GenMsgCycleTime" BO_ 270 40;
BA_ "GenMsgSendType" BO_ 270 0;
BA_ "MessageSubnet" BO_ 271 6;
BA_ "GenMsgCycleTime" BO_ 271 40;
BA_ "GenMsgSendType" BO_ 271 0;
BA_ "MessageSubnet" BO_ 272 6;
BA_ "GenMsgCycleTime" BO_ 272 40;
BA_ "GenMsgSendType" BO_ 272 0;
BA_ "MessageSubnet" BO_ 273 6;
BA_ "GenMsgCycleTime" BO_ 273 40;
BA_ "GenMsgSendType" BO_ 273 0;
BA_ "MessageSubnet" BO_ 513 6;
BA_ "GenMsgCycleTime" BO_ 513 20;
BA_ "GenMsgSendType" BO_ 513 0;
BA_ "MessageSubnet" BO_ 525 6;
BA_ "GenMsgCycleTime" BO_ 525 100;
BA_ "GenMsgSendType" BO_ 525 0;
BA_ "MessageSubnet" BO_ 515 6;
BA_ "GenMsgCycleTime" BO_ 515 20;
BA_ "GenMsgSendType" BO_ 515 0;
BA_ "MessageSubnet" BO_ 1026 6;
BA_ "GenMsgCycleTime" BO_ 1026 100;
BA_ "GenMsgSendType" BO_ 1026 0;
BA_ "MessageSubnet" BO_ 1027 6;
BA_ "GenMsgCycleTime" BO_ 1027 100;
BA_ "GenMsgSendType" BO_ 1027 0;
BA_ "MessageSubnet" BO_ 1554 6;
BA_ "GenMsgCycleTime" BO_ 1554 100;
BA_ "GenMsgSendType" BO_ 1554 0;
BA_ "MessageSubnet" BO_ 1555 6;
BA_ "GenMsgCycleTime" BO_ 1555 100;
BA_ "GenMsgSendType" BO_ 1555 0;
BA_ "MessageSubnet" BO_ 1552 6;
BA_ "GenMsgCycleTime" BO_ 1552 100;
BA_ "GenMsgSendType" BO_ 1552 0;
BA_ "MessageSubnet" BO_ 1553 6;
BA_ "GenMsgCycleTime" BO_ 1553 100;
BA_ "GenMsgSendType" BO_ 1553 0;
BA_ "MessageSubnet" BO_ 1556 6;
BA_ "GenMsgCycleTime" BO_ 1556 100;
BA_ "GenMsgSendType" BO_ 1556 0;
BA_ "MessageSubnet" BO_ 1557 6;
BA_ "GenMsgCycleTime" BO_ 1557 100;
BA_ "GenMsgSendType" BO_ 1557 0;
BA_ "MessageSubnet" BO_ 393 6;
BA_ "GenMsgDelayTime" BO_ 393 10;
BA_ "GenMsgCycleTime" BO_ 393 100;
BA_ "GenMsgSendType" BO_ 393 0;
BA_ "MessageSubnet" BO_ 390 6;
BA_ "GenMsgDelayTime" BO_ 390 10;
BA_ "GenMsgCycleTime" BO_ 390 100;
BA_ "GenMsgSendType" BO_ 390 0;
BA_ "MessageSubnet" BO_ 391 6;
BA_ "GenMsgDelayTime" BO_ 391 10;
BA_ "GenMsgCycleTime" BO_ 391 100;
BA_ "GenMsgSendType" BO_ 391 0;
BA_ "MessageSubnet" BO_ 1536 6;
BA_ "GenMsgCycleTime" BO_ 1536 100;
BA_ "GenMsgSendType" BO_ 1536 0;
BA_ "MessageSubnet" BO_ 1538 6;
BA_ "GenMsgCycleTime" BO_ 1538 100;
BA_ "GenMsgSendType" BO_ 1538 0;
BA_ "MessageSubnet" BO_ 1540 6;
BA_ "GenMsgCycleTime" BO_ 1540 100;
BA_ "GenMsgSendType" BO_ 1540 0;
BA_ "MessageSubnet" BO_ 1542 6;
BA_ "GenMsgCycleTime" BO_ 1542 100;
BA_ "GenMsgSendType" BO_ 1542 0;
BA_ "MessageSubnet" BO_ 1544 6;
BA_ "GenMsgCycleTime" BO_ 1544 100;
BA_ "GenMsgSendType" BO_ 1544 0;
BA_ "MessageSubnet" BO_ 1546 6;
BA_ "GenMsgCycleTime" BO_ 1546 100;
BA_ "GenMsgSendType" BO_ 1546 0;
BA_ "MessageSubnet" BO_ 1584 6;
BA_ "GenMsgCycleTime" BO_ 1584 100;
BA_ "GenMsgSendType" BO_ 1584 0;
BA_ "MessageSubnet" BO_ 1586 6;
BA_ "GenMsgCycleTime" BO_ 1586 100;
BA_ "GenMsgSendType" BO_ 1586 0;
BA_ "MessageSubnet" BO_ 1537 6;
BA_ "GenMsgCycleTime" BO_ 1537 100;
BA_ "GenMsgSendType" BO_ 1537 0;
BA_ "MessageSubnet" BO_ 1539 6;
BA_ "GenMsgCycleTime" BO_ 1539 100;
BA_ "GenMsgSendType" BO_ 1539 0;
BA_ "MessageSubnet" BO_ 1541 6;
BA_ "GenMsgCycleTime" BO_ 1541 100;
BA_ "GenMsgSendType" BO_ 1541 0;
BA_ "MessageSubnet" BO_ 1543 6;
BA_ "GenMsgCycleTime" BO_ 1543 100;
BA_ "GenMsgSendType" BO_ 1543 0;
BA_ "MessageSubnet" BO_ 1545 6;
BA_ "GenMsgCycleTime" BO_ 1545 100;
BA_ "GenMsgSendType" BO_ 1545 0;
BA_ "MessageSubnet" BO_ 1547 6;
BA_ "GenMsgCycleTime" BO_ 1547 100;
BA_ "GenMsgSendType" BO_ 1547 0;
BA_ "MessageSubnet" BO_ 1585 6;
BA_ "GenMsgCycleTime" BO_ 1585 100;
BA_ "GenMsgSendType" BO_ 1585 0;
BA_ "MessageSubnet" BO_ 1587 6;
BA_ "GenMsgCycleTime" BO_ 1587 100;
BA_ "GenMsgSendType" BO_ 1587 0;
BA_ "SignalLongName" SG_ 3221225472 FuncDiagReq "Function diagnostic request";
BA_ "SignalType" SG_ 3221225472 FuncDiagReq "UNM";
BA_ "GenSigSendType" SG_ 3221225472 FuncDiagReq 1;
BA_ "SignalLongName" SG_ 3221225472 LftPhyDiagReq "Left headlamp Physical Diagnostic Request";
BA_ "SignalType" SG_ 3221225472 LftPhyDiagReq "UNM";
BA_ "GenSigSendType" SG_ 3221225472 LftPhyDiagReq 1;
BA_ "SignalLongName" SG_ 3221225472 RghtPhyDiagReq "Right Headlamp  Physical Diagnostic Request";
BA_ "SignalType" SG_ 3221225472 RghtPhyDiagReq "UNM";
BA_ "GenSigSendType" SG_ 3221225472 RghtPhyDiagReq 1;
BA_ "SignalLongName" SG_ 3221225472 LftPhyDiagResp "Left Headlamp Physical Diagnostic response";
BA_ "SignalType" SG_ 3221225472 LftPhyDiagResp "UNM";
BA_ "GenSigSendType" SG_ 3221225472 LftPhyDiagResp 1;
BA_ "SignalLongName" SG_ 3221225472 RghtPhyDiagResp "Right Headlamp Physical Diagnostic response";
BA_ "SignalType" SG_ 3221225472 RghtPhyDiagResp "UNM";
BA_ "GenSigSendType" SG_ 3221225472 RghtPhyDiagResp 1;
BA_ "SignalLongName" SG_ 258 LH_GFA1_Chcksm "Left Headlamp Glare Free Area 1 Checksum";
BA_ "SignalType" SG_ 258 LH_GFA1_Chcksm "UNM";
BA_ "SignalLongName" SG_ 258 LH_GFA1_MssgCntr "Left Headlamp Glare Free Area 1 Message Counter";
BA_ "SignalType" SG_ 258 LH_GFA1_MssgCntr "UNM";
BA_ "SignalLongName" SG_ 258 LH_GFA1_CntrHrztlPostn "Left Headlamp Glare Free Area 1 Center Horizontal Position";
BA_ "SignalType" SG_ 258 LH_GFA1_CntrHrztlPostn "SNM";
BA_ "SignalLongName" SG_ 258 LH_GFA1_CntrVrtclPostn "Left Headlamp Glare Free Area 1 Center Vertical Position";
BA_ "SignalType" SG_ 258 LH_GFA1_CntrVrtclPostn "SNM";
BA_ "SignalLongName" SG_ 258 LH_GFA1_HrztlHlfWidt "Left Headlamp Glare Free Area 1 Horizontal Half Width";
BA_ "SignalType" SG_ 258 LH_GFA1_HrztlHlfWidt "UNM";
BA_ "SignalLongName" SG_ 258 LH_GFA1_VrtclHlfWidt "Left Headlamp Glare Free Area 1 Vertical Half Width";
BA_ "SignalType" SG_ 258 LH_GFA1_VrtclHlfWidt "UNM";
BA_ "SignalLongName" SG_ 258 LH_GFA1_Prsnc "Left Headlamp Glare Free Area 1 Presence";
BA_ "SignalType" SG_ 258 LH_GFA1_Prsnc "ENM";
BA_ "SignalLongName" SG_ 258 LH_GFA1_DimVal "Left Headlamp Glare Free Area 1 Dim Value";
BA_ "SignalType" SG_ 258 LH_GFA1_DimVal "UNM";
BA_ "SignalLongName" SG_ 258 LH_GFA1_DimUpTime "Left Headlamp Glare Free Area 1 Dim Up Time";
BA_ "SignalType" SG_ 258 LH_GFA1_DimUpTime "UNM";
BA_ "SignalLongName" SG_ 258 LH_GFA1_DimDwnTime "Left Headlamp Glare Free Area 1 Dim Down Time";
BA_ "SignalType" SG_ 258 LH_GFA1_DimDwnTime "UNM";
BA_ "SignalLongName" SG_ 259 RH_GFA1_Chcksm "Right Headlamp Glare Free Area 1 Checksum";
BA_ "SignalType" SG_ 259 RH_GFA1_Chcksm "UNM";
BA_ "SignalLongName" SG_ 259 RH_GFA1_MssgCntr "Right Headlamp Glare Free Area 1 Message Counter";
BA_ "SignalType" SG_ 259 RH_GFA1_MssgCntr "UNM";
BA_ "SignalLongName" SG_ 259 RH_GFA1_CntrHrztlPostn "Right Headlamp Glare Free Area 1 Center Horizontal Position";
BA_ "SignalType" SG_ 259 RH_GFA1_CntrHrztlPostn "SNM";
BA_ "SignalLongName" SG_ 259 RH_GFA1_CntrVrtclPostn "Right Headlamp Glare Free Area 1 Center Vertical Position";
BA_ "SignalType" SG_ 259 RH_GFA1_CntrVrtclPostn "SNM";
BA_ "SignalLongName" SG_ 259 RH_GFA1_HrztlHlfWidt "Right Headlamp Glare Free Area 1 Horizontal Half Width";
BA_ "SignalType" SG_ 259 RH_GFA1_HrztlHlfWidt "UNM";
BA_ "SignalLongName" SG_ 259 RH_GFA1_VrtclHlfWidt "Right Headlamp Glare Free Area 1 Vertical Half Width";
BA_ "SignalType" SG_ 259 RH_GFA1_VrtclHlfWidt "UNM";
BA_ "SignalLongName" SG_ 259 RH_GFA1_Prsnc "Right Headlamp Glare Free Area 1 Presence";
BA_ "SignalType" SG_ 259 RH_GFA1_Prsnc "ENM";
BA_ "SignalLongName" SG_ 259 RH_GFA1_DimVal "Right Headlamp Glare Free Area 1 Dim Value";
BA_ "SignalType" SG_ 259 RH_GFA1_DimVal "UNM";
BA_ "SignalLongName" SG_ 259 RH_GFA1_DimUpTime "Right Headlamp Glare Free Area 1 Dim Up Time";
BA_ "SignalType" SG_ 259 RH_GFA1_DimUpTime "UNM";
BA_ "SignalLongName" SG_ 259 RH_GFA1_DimDwnTime "Right Headlamp Glare Free Area 1 Dim Down Time";
BA_ "SignalType" SG_ 259 RH_GFA1_DimDwnTime "UNM";
BA_ "SignalLongName" SG_ 260 LH_GFA2_Chcksm "Left Headlamp Glare Free Area 2 Checksum";
BA_ "SignalType" SG_ 260 LH_GFA2_Chcksm "UNM";
BA_ "SignalLongName" SG_ 260 LH_GFA2_MssgCntr "Left Headlamp Glare Free Area 2 Message Counter";
BA_ "SignalType" SG_ 260 LH_GFA2_MssgCntr "UNM";
BA_ "SignalLongName" SG_ 260 LH_GFA2_CntrHrztlPostn "Left Headlamp Glare Free Area 2 Center Horizontal Position";
BA_ "SignalType" SG_ 260 LH_GFA2_CntrHrztlPostn "SNM";
BA_ "SignalLongName" SG_ 260 LH_GFA2_CntrVrtclPostn "Left Headlamp Glare Free Area 2 Center Vertical Position";
BA_ "SignalType" SG_ 260 LH_GFA2_CntrVrtclPostn "SNM";
BA_ "SignalLongName" SG_ 260 LH_GFA2_HrztlHlfWidt "Left Headlamp Glare Free Area 2 Horizontal Half Width";
BA_ "SignalType" SG_ 260 LH_GFA2_HrztlHlfWidt "UNM";
BA_ "SignalLongName" SG_ 260 LH_GFA2_VrtclHlfWidt "Left Headlamp Glare Free Area 2 Vertical Half Width";
BA_ "SignalType" SG_ 260 LH_GFA2_VrtclHlfWidt "UNM";
BA_ "SignalLongName" SG_ 260 LH_GFA2_Prsnc "Left Headlamp Glare Free Area 2 Presence";
BA_ "SignalType" SG_ 260 LH_GFA2_Prsnc "ENM";
BA_ "SignalLongName" SG_ 260 LH_GFA2_DimVal "Left Headlamp Glare Free Area 2 Dim Value";
BA_ "SignalType" SG_ 260 LH_GFA2_DimVal "UNM";
BA_ "SignalLongName" SG_ 260 LH_GFA2_DimUpTime "Left Headlamp Glare Free Area 2 Dim Up Time";
BA_ "SignalType" SG_ 260 LH_GFA2_DimUpTime "UNM";
BA_ "SignalLongName" SG_ 260 LH_GFA2_DimDwnTime "Left Headlamp Glare Free Area 2 Dim Down Time";
BA_ "SignalType" SG_ 260 LH_GFA2_DimDwnTime "UNM";
BA_ "SignalLongName" SG_ 261 RH_GFA2_Chcksm "Right Headlamp Glare Free Area 2 Checksum";
BA_ "SignalType" SG_ 261 RH_GFA2_Chcksm "UNM";
BA_ "SignalLongName" SG_ 261 RH_GFA2_MssgCntr "Right Headlamp Glare Free Area 2 Message Counter";
BA_ "SignalType" SG_ 261 RH_GFA2_MssgCntr "UNM";
BA_ "SignalLongName" SG_ 261 RH_GFA2_CntrHrztlPostn "Right Headlamp Glare Free Area 2 Center Horizontal Position";
BA_ "SignalType" SG_ 261 RH_GFA2_CntrHrztlPostn "SNM";
BA_ "SignalLongName" SG_ 261 RH_GFA2_CntrVrtclPostn "Right Headlamp Glare Free Area 2 Center Vertical Position";
BA_ "SignalType" SG_ 261 RH_GFA2_CntrVrtclPostn "SNM";
BA_ "SignalLongName" SG_ 261 RH_GFA2_HrztlHlfWidt "Right Headlamp Glare Free Area 2 Horizontal Half Width";
BA_ "SignalType" SG_ 261 RH_GFA2_HrztlHlfWidt "UNM";
BA_ "SignalLongName" SG_ 261 RH_GFA2_VrtclHlfWidt "Right Headlamp Glare Free Area 2 Vertical Half Width";
BA_ "SignalType" SG_ 261 RH_GFA2_VrtclHlfWidt "UNM";
BA_ "SignalLongName" SG_ 261 RH_GFA2_Prsnc "Right Headlamp Glare Free Area 2 Presence";
BA_ "SignalType" SG_ 261 RH_GFA2_Prsnc "ENM";
BA_ "SignalLongName" SG_ 261 RH_GFA2_DimVal "Right Headlamp Glare Free Area 2 Dim Value";
BA_ "SignalType" SG_ 261 RH_GFA2_DimVal "UNM";
BA_ "SignalLongName" SG_ 261 RH_GFA2_DimUpTime "Right Headlamp Glare Free Area 2 Dim Up Time";
BA_ "SignalType" SG_ 261 RH_GFA2_DimUpTime "UNM";
BA_ "SignalLongName" SG_ 261 RH_GFA2_DimDwnTime "Right Headlamp Glare Free Area 2 Dim Down Time";
BA_ "SignalType" SG_ 261 RH_GFA2_DimDwnTime "UNM";
BA_ "SignalLongName" SG_ 262 LH_GFA3_Chcksm "Left Headlamp Glare Free Area 3 Checksum";
BA_ "SignalType" SG_ 262 LH_GFA3_Chcksm "UNM";
BA_ "SignalLongName" SG_ 262 LH_GFA3_MssgCntr "Left Headlamp Glare Free Area 3 Message Counter";
BA_ "SignalType" SG_ 262 LH_GFA3_MssgCntr "UNM";
BA_ "SignalLongName" SG_ 262 LH_GFA3_CntrHrztlPostn "Left Headlamp Glare Free Area 3 Center Horizontal Position";
BA_ "SignalType" SG_ 262 LH_GFA3_CntrHrztlPostn "SNM";
BA_ "SignalLongName" SG_ 262 LH_GFA3_CntrVrtclPostn "Left Headlamp Glare Free Area 3 Center Vertical Position";
BA_ "SignalType" SG_ 262 LH_GFA3_CntrVrtclPostn "SNM";
BA_ "SignalLongName" SG_ 262 LH_GFA3_HrztlHlfWidt "Left Headlamp Glare Free Area 3 Horizontal Half Width";
BA_ "SignalType" SG_ 262 LH_GFA3_HrztlHlfWidt "UNM";
BA_ "SignalLongName" SG_ 262 LH_GFA3_VrtclHlfWidt "Left Headlamp Glare Free Area 3 Vertical Half Width";
BA_ "SignalType" SG_ 262 LH_GFA3_VrtclHlfWidt "UNM";
BA_ "SignalLongName" SG_ 262 LH_GFA3_Prsnc "Left Headlamp Glare Free Area 3 Presence";
BA_ "SignalType" SG_ 262 LH_GFA3_Prsnc "ENM";
BA_ "SignalLongName" SG_ 262 LH_GFA3_DimVal "Left Headlamp Glare Free Area 3 Dim Value";
BA_ "SignalType" SG_ 262 LH_GFA3_DimVal "UNM";
BA_ "SignalLongName" SG_ 262 LH_GFA3_DimUpTime "Left Headlamp Glare Free Area 3 Dim Up Time";
BA_ "SignalType" SG_ 262 LH_GFA3_DimUpTime "UNM";
BA_ "SignalLongName" SG_ 262 LH_GFA3_DimDwnTime "Left Headlamp Glare Free Area 3 Dim Down Time";
BA_ "SignalType" SG_ 262 LH_GFA3_DimDwnTime "UNM";
BA_ "SignalLongName" SG_ 263 RH_GFA3_Chcksm "Right Headlamp Glare Free Area 3 Checksum";
BA_ "SignalType" SG_ 263 RH_GFA3_Chcksm "UNM";
BA_ "SignalLongName" SG_ 263 RH_GFA3_MssgCntr "Right Headlamp Glare Free Area 3 Message Counter";
BA_ "SignalType" SG_ 263 RH_GFA3_MssgCntr "UNM";
BA_ "SignalLongName" SG_ 263 RH_GFA3_CntrHrztlPostn "Right Headlamp Glare Free Area 3 Center Horizontal Position";
BA_ "SignalType" SG_ 263 RH_GFA3_CntrHrztlPostn "SNM";
BA_ "SignalLongName" SG_ 263 RH_GFA3_CntrVrtclPostn "Right Headlamp Glare Free Area 3 Center Vertical Position";
BA_ "SignalType" SG_ 263 RH_GFA3_CntrVrtclPostn "SNM";
BA_ "SignalLongName" SG_ 263 RH_GFA3_HrztlHlfWidt "Right Headlamp Glare Free Area 3 Horizontal Half Width";
BA_ "SignalType" SG_ 263 RH_GFA3_HrztlHlfWidt "UNM";
BA_ "SignalLongName" SG_ 263 RH_GFA3_VrtclHlfWidt "Right Headlamp Glare Free Area 3 Vertical Half Width";
BA_ "SignalType" SG_ 263 RH_GFA3_VrtclHlfWidt "UNM";
BA_ "SignalLongName" SG_ 263 RH_GFA3_Prsnc "Right Headlamp Glare Free Area 3 Presence";
BA_ "SignalType" SG_ 263 RH_GFA3_Prsnc "ENM";
BA_ "SignalLongName" SG_ 263 RH_GFA3_DimVal "Right Headlamp Glare Free Area 3 Dim Value";
BA_ "SignalType" SG_ 263 RH_GFA3_DimVal "UNM";
BA_ "SignalLongName" SG_ 263 RH_GFA3_DimUpTime "Right Headlamp Glare Free Area 3 Dim Up Time";
BA_ "SignalType" SG_ 263 RH_GFA3_DimUpTime "UNM";
BA_ "SignalLongName" SG_ 263 RH_GFA3_DimDwnTime "Right Headlamp Glare Free Area 3 Dim Down Time";
BA_ "SignalType" SG_ 263 RH_GFA3_DimDwnTime "UNM";
BA_ "SignalLongName" SG_ 264 LH_GFA4_Chcksm "Left Headlamp Glare Free Area 4 Checksum";
BA_ "SignalType" SG_ 264 LH_GFA4_Chcksm "UNM";
BA_ "SignalLongName" SG_ 264 LH_GFA4_MssgCntr "Left Headlamp Glare Free Area 4 Message Counter";
BA_ "SignalType" SG_ 264 LH_GFA4_MssgCntr "UNM";
BA_ "SignalLongName" SG_ 264 LH_GFA4_CntrHrztlPostn "Left Headlamp Glare Free Area 4 Center Horizontal Position";
BA_ "SignalType" SG_ 264 LH_GFA4_CntrHrztlPostn "SNM";
BA_ "SignalLongName" SG_ 264 LH_GFA4_CntrVrtclPostn "Left Headlamp Glare Free Area 4 Center Vertical Position";
BA_ "SignalType" SG_ 264 LH_GFA4_CntrVrtclPostn "SNM";
BA_ "SignalLongName" SG_ 264 LH_GFA4_HrztlHlfWidt "Left Headlamp Glare Free Area 4 Horizontal Half Width";
BA_ "SignalType" SG_ 264 LH_GFA4_HrztlHlfWidt "UNM";
BA_ "SignalLongName" SG_ 264 LH_GFA4_VrtclHlfWidt "Left Headlamp Glare Free Area 4 Vertical Half Width";
BA_ "SignalType" SG_ 264 LH_GFA4_VrtclHlfWidt "UNM";
BA_ "SignalLongName" SG_ 264 LH_GFA4_Prsnc "Left Headlamp Glare Free Area 4 Presence";
BA_ "SignalType" SG_ 264 LH_GFA4_Prsnc "ENM";
BA_ "SignalLongName" SG_ 264 LH_GFA4_DimVal "Left Headlamp Glare Free Area 4 Dim Value";
BA_ "SignalType" SG_ 264 LH_GFA4_DimVal "UNM";
BA_ "SignalLongName" SG_ 264 LH_GFA4_DimUpTime "Left Headlamp Glare Free Area 4 Dim Up Time";
BA_ "SignalType" SG_ 264 LH_GFA4_DimUpTime "UNM";
BA_ "SignalLongName" SG_ 264 LH_GFA4_DimDwnTime "Left Headlamp Glare Free Area 4 Dim Down Time";
BA_ "SignalType" SG_ 264 LH_GFA4_DimDwnTime "UNM";
BA_ "SignalLongName" SG_ 265 RH_GFA4_Chcksm "Right Headlamp Glare Free Area 4 Checksum";
BA_ "SignalType" SG_ 265 RH_GFA4_Chcksm "UNM";
BA_ "SignalLongName" SG_ 265 RH_GFA4_MssgCntr "Right Headlamp Glare Free Area 4 Message Counter";
BA_ "SignalType" SG_ 265 RH_GFA4_MssgCntr "UNM";
BA_ "SignalLongName" SG_ 265 RH_GFA4_CntrHrztlPostn "Right Headlamp Glare Free Area 4 Center Horizontal Position";
BA_ "SignalType" SG_ 265 RH_GFA4_CntrHrztlPostn "SNM";
BA_ "SignalLongName" SG_ 265 RH_GFA4_CntrVrtclPostn "Right Headlamp Glare Free Area 4 Center Vertical Position";
BA_ "SignalType" SG_ 265 RH_GFA4_CntrVrtclPostn "SNM";
BA_ "SignalLongName" SG_ 265 RH_GFA4_HrztlHlfWidt "Right Headlamp Glare Free Area 4 Horizontal Half Width";
BA_ "SignalType" SG_ 265 RH_GFA4_HrztlHlfWidt "UNM";
BA_ "SignalLongName" SG_ 265 RH_GFA4_VrtclHlfWidt "Right Headlamp Glare Free Area 4 Vertical Half Width";
BA_ "SignalType" SG_ 265 RH_GFA4_VrtclHlfWidt "UNM";
BA_ "SignalLongName" SG_ 265 RH_GFA4_Prsnc "Right Headlamp Glare Free Area 4 Presence";
BA_ "SignalType" SG_ 265 RH_GFA4_Prsnc "ENM";
BA_ "SignalLongName" SG_ 265 RH_GFA4_DimVal "Right Headlamp Glare Free Area 4 Dim Value";
BA_ "SignalType" SG_ 265 RH_GFA4_DimVal "UNM";
BA_ "SignalLongName" SG_ 265 RH_GFA4_DimUpTime "Right Headlamp Glare Free Area 4 Dim Up Time";
BA_ "SignalType" SG_ 265 RH_GFA4_DimUpTime "UNM";
BA_ "SignalLongName" SG_ 265 RH_GFA4_DimDwnTime "Right Headlamp Glare Free Area 4 Dim Down Time";
BA_ "SignalType" SG_ 265 RH_GFA4_DimDwnTime "UNM";
BA_ "SignalLongName" SG_ 266 LH_GFA5_Chcksm "Left Headlamp Glare Free Area 5 Checksum";
BA_ "SignalType" SG_ 266 LH_GFA5_Chcksm "UNM";
BA_ "SignalLongName" SG_ 266 LH_GFA5_MssgCntr "Left Headlamp Glare Free Area 5 Message Counter";
BA_ "SignalType" SG_ 266 LH_GFA5_MssgCntr "UNM";
BA_ "SignalLongName" SG_ 266 LH_GFA5_CntrHrztlPostn "Left Headlamp Glare Free Area 5 Center Horizontal Position";
BA_ "SignalType" SG_ 266 LH_GFA5_CntrHrztlPostn "SNM";
BA_ "SignalLongName" SG_ 266 LH_GFA5_CntrVrtclPostn "Left Headlamp Glare Free Area 5 Center Vertical Position";
BA_ "SignalType" SG_ 266 LH_GFA5_CntrVrtclPostn "SNM";
BA_ "SignalLongName" SG_ 266 LH_GFA5_HrztlHlfWidt "Left Headlamp Glare Free Area 5 Horizontal Half Width";
BA_ "SignalType" SG_ 266 LH_GFA5_HrztlHlfWidt "UNM";
BA_ "SignalLongName" SG_ 266 LH_GFA5_VrtclHlfWidt "Left Headlamp Glare Free Area 5 Vertical Half Width";
BA_ "SignalType" SG_ 266 LH_GFA5_VrtclHlfWidt "UNM";
BA_ "SignalLongName" SG_ 266 LH_GFA5_Prsnc "Left Headlamp Glare Free Area 5 Presence";
BA_ "SignalType" SG_ 266 LH_GFA5_Prsnc "ENM";
BA_ "SignalLongName" SG_ 266 LH_GFA5_DimVal "Left Headlamp Glare Free Area 5 Dim Value";
BA_ "SignalType" SG_ 266 LH_GFA5_DimVal "UNM";
BA_ "SignalLongName" SG_ 266 LH_GFA5_DimUpTime "Left Headlamp Glare Free Area 5 Dim Up Time";
BA_ "SignalType" SG_ 266 LH_GFA5_DimUpTime "UNM";
BA_ "SignalLongName" SG_ 266 LH_GFA5_DimDwnTime "Left Headlamp Glare Free Area 5 Dim Down Time";
BA_ "SignalType" SG_ 266 LH_GFA5_DimDwnTime "UNM";
BA_ "SignalLongName" SG_ 267 RH_GFA5_Chcksm "Right Headlamp Glare Free Area 5 Checksum";
BA_ "SignalType" SG_ 267 RH_GFA5_Chcksm "UNM";
BA_ "SignalLongName" SG_ 267 RH_GFA5_MssgCntr "Right Headlamp Glare Free Area 5 Message Counter";
BA_ "SignalType" SG_ 267 RH_GFA5_MssgCntr "UNM";
BA_ "SignalLongName" SG_ 267 RH_GFA5_CntrHrztlPostn "Right Headlamp Glare Free Area 5 Center Horizontal Position";
BA_ "SignalType" SG_ 267 RH_GFA5_CntrHrztlPostn "SNM";
BA_ "SignalLongName" SG_ 267 RH_GFA5_CntrVrtclPostn "Right Headlamp Glare Free Area 5 Center Vertical Position";
BA_ "SignalType" SG_ 267 RH_GFA5_CntrVrtclPostn "SNM";
BA_ "SignalLongName" SG_ 267 RH_GFA5_HrztlHlfWidt "Right Headlamp Glare Free Area 5 Horizontal Half Width";
BA_ "SignalType" SG_ 267 RH_GFA5_HrztlHlfWidt "UNM";
BA_ "SignalLongName" SG_ 267 RH_GFA5_VrtclHlfWidt "Right Headlamp Glare Free Area 5 Vertical Half Width";
BA_ "SignalType" SG_ 267 RH_GFA5_VrtclHlfWidt "UNM";
BA_ "SignalLongName" SG_ 267 RH_GFA5_Prsnc "Right Headlamp Glare Free Area 5 Presence";
BA_ "SignalType" SG_ 267 RH_GFA5_Prsnc "ENM";
BA_ "SignalLongName" SG_ 267 RH_GFA5_DimVal "Right Headlamp Glare Free Area 5 Dim Value";
BA_ "SignalType" SG_ 267 RH_GFA5_DimVal "UNM";
BA_ "SignalLongName" SG_ 267 RH_GFA5_DimUpTime "Right Headlamp Glare Free Area 5 Dim Up Time";
BA_ "SignalType" SG_ 267 RH_GFA5_DimUpTime "UNM";
BA_ "SignalLongName" SG_ 267 RH_GFA5_DimDwnTime "Right Headlamp Glare Free Area 5 Dim Down Time";
BA_ "SignalType" SG_ 267 RH_GFA5_DimDwnTime "UNM";
BA_ "SignalLongName" SG_ 268 LH_GFA6_Chcksm "Left Headlamp Glare Free Area 6 Checksum";
BA_ "SignalType" SG_ 268 LH_GFA6_Chcksm "UNM";
BA_ "SignalLongName" SG_ 268 LH_GFA6_MssgCntr "Left Headlamp Glare Free Area 6 Message Counter";
BA_ "SignalType" SG_ 268 LH_GFA6_MssgCntr "UNM";
BA_ "SignalLongName" SG_ 268 LH_GFA6_CntrHrztlPostn "Left Headlamp Glare Free Area 6 Center Horizontal Position";
BA_ "SignalType" SG_ 268 LH_GFA6_CntrHrztlPostn "SNM";
BA_ "SignalLongName" SG_ 268 LH_GFA6_CntrVrtclPostn "Left Headlamp Glare Free Area 6 Center Vertical Position";
BA_ "SignalType" SG_ 268 LH_GFA6_CntrVrtclPostn "SNM";
BA_ "SignalLongName" SG_ 268 LH_GFA6_HrztlHlfWidt "Left Headlamp Glare Free Area 6 Horizontal Half Width";
BA_ "SignalType" SG_ 268 LH_GFA6_HrztlHlfWidt "UNM";
BA_ "SignalLongName" SG_ 268 LH_GFA6_VrtclHlfWidt "Left Headlamp Glare Free Area 6 Vertical Half Width";
BA_ "SignalType" SG_ 268 LH_GFA6_VrtclHlfWidt "UNM";
BA_ "SignalLongName" SG_ 268 LH_GFA6_Prsnc "Left Headlamp Glare Free Area 6 Presence";
BA_ "SignalType" SG_ 268 LH_GFA6_Prsnc "ENM";
BA_ "SignalLongName" SG_ 268 LH_GFA6_DimVal "Left Headlamp Glare Free Area 6 Dim Value";
BA_ "SignalType" SG_ 268 LH_GFA6_DimVal "UNM";
BA_ "SignalLongName" SG_ 268 LH_GFA6_DimUpTime "Left Headlamp Glare Free Area 6 Dim Up Time";
BA_ "SignalType" SG_ 268 LH_GFA6_DimUpTime "UNM";
BA_ "SignalLongName" SG_ 268 LH_GFA6_DimDwnTime "Left Headlamp Glare Free Area 6 Dim Down Time";
BA_ "SignalType" SG_ 268 LH_GFA6_DimDwnTime "UNM";
BA_ "SignalLongName" SG_ 269 RH_GFA6_Chcksm "Right Headlamp Glare Free Area 6 Checksum";
BA_ "SignalType" SG_ 269 RH_GFA6_Chcksm "UNM";
BA_ "SignalLongName" SG_ 269 RH_GFA6_MssgCntr "Right Headlamp Glare Free Area 6 Message Counter";
BA_ "SignalType" SG_ 269 RH_GFA6_MssgCntr "UNM";
BA_ "SignalLongName" SG_ 269 RH_GFA6_CntrHrztlPostn "Right Headlamp Glare Free Area 6 Center Horizontal Position";
BA_ "SignalType" SG_ 269 RH_GFA6_CntrHrztlPostn "SNM";
BA_ "SignalLongName" SG_ 269 RH_GFA6_CntrVrtclPostn "Right Headlamp Glare Free Area 6 Center Vertical Position";
BA_ "SignalType" SG_ 269 RH_GFA6_CntrVrtclPostn "SNM";
BA_ "SignalLongName" SG_ 269 RH_GFA6_HrztlHlfWidt "Right Headlamp Glare Free Area 6 Horizontal Half Width";
BA_ "SignalType" SG_ 269 RH_GFA6_HrztlHlfWidt "UNM";
BA_ "SignalLongName" SG_ 269 RH_GFA6_VrtclHlfWidt "Right Headlamp Glare Free Area 6 Vertical Half Width";
BA_ "SignalType" SG_ 269 RH_GFA6_VrtclHlfWidt "UNM";
BA_ "SignalLongName" SG_ 269 RH_GFA6_Prsnc "Right Headlamp Glare Free Area 6 Presence";
BA_ "SignalType" SG_ 269 RH_GFA6_Prsnc "ENM";
BA_ "SignalLongName" SG_ 269 RH_GFA6_DimVal "Right Headlamp Glare Free Area 6 Dim Value";
BA_ "SignalType" SG_ 269 RH_GFA6_DimVal "UNM";
BA_ "SignalLongName" SG_ 269 RH_GFA6_DimUpTime "Right Headlamp Glare Free Area 6 Dim Up Time";
BA_ "SignalType" SG_ 269 RH_GFA6_DimUpTime "UNM";
BA_ "SignalLongName" SG_ 269 RH_GFA6_DimDwnTime "Right Headlamp Glare Free Area 6 Dim Down Time";
BA_ "SignalType" SG_ 269 RH_GFA6_DimDwnTime "UNM";
BA_ "SignalLongName" SG_ 270 LH_GFA7_Chcksm "Left Headlamp Glare Free Area 7 Checksum";
BA_ "SignalType" SG_ 270 LH_GFA7_Chcksm "UNM";
BA_ "SignalLongName" SG_ 270 LH_GFA7_MssgCntr "Left Headlamp Glare Free Area 7 Message Counter";
BA_ "SignalType" SG_ 270 LH_GFA7_MssgCntr "UNM";
BA_ "SignalLongName" SG_ 270 LH_GFA7_CntrHrztlPostn "Left Headlamp Glare Free Area 7 Center Horizontal Position";
BA_ "SignalType" SG_ 270 LH_GFA7_CntrHrztlPostn "SNM";
BA_ "SignalLongName" SG_ 270 LH_GFA7_CntrVrtclPostn "Left Headlamp Glare Free Area 7 Center Vertical Position";
BA_ "SignalType" SG_ 270 LH_GFA7_CntrVrtclPostn "SNM";
BA_ "SignalLongName" SG_ 270 LH_GFA7_HrztlHlfWidt "Left Headlamp Glare Free Area 7 Horizontal Half Width";
BA_ "SignalType" SG_ 270 LH_GFA7_HrztlHlfWidt "UNM";
BA_ "SignalLongName" SG_ 270 LH_GFA7_VrtclHlfWidt "Left Headlamp Glare Free Area 7 Vertical Half Width";
BA_ "SignalType" SG_ 270 LH_GFA7_VrtclHlfWidt "UNM";
BA_ "SignalLongName" SG_ 270 LH_GFA7_Prsnc "Left Headlamp Glare Free Area 7 Presence";
BA_ "SignalType" SG_ 270 LH_GFA7_Prsnc "ENM";
BA_ "SignalLongName" SG_ 270 LH_GFA7_DimVal "Left Headlamp Glare Free Area 7 Dim Value";
BA_ "SignalType" SG_ 270 LH_GFA7_DimVal "UNM";
BA_ "SignalLongName" SG_ 270 LH_GFA7_DimUpTime "Left Headlamp Glare Free Area 7 Dim Up Time";
BA_ "SignalType" SG_ 270 LH_GFA7_DimUpTime "UNM";
BA_ "SignalLongName" SG_ 270 LH_GFA7_DimDwnTime "Left Headlamp Glare Free Area 7 Dim Down Time";
BA_ "SignalType" SG_ 270 LH_GFA7_DimDwnTime "UNM";
BA_ "SignalLongName" SG_ 271 RH_GFA7_Chcksm "Right Headlamp Glare Free Area 7 Checksum";
BA_ "SignalType" SG_ 271 RH_GFA7_Chcksm "UNM";
BA_ "SignalLongName" SG_ 271 RH_GFA7_MssgCntr "Right Headlamp Glare Free Area 7 Message Counter";
BA_ "SignalType" SG_ 271 RH_GFA7_MssgCntr "UNM";
BA_ "SignalLongName" SG_ 271 RH_GFA7_CntrHrztlPostn "Right Headlamp Glare Free Area 7 Center Horizontal Position";
BA_ "SignalType" SG_ 271 RH_GFA7_CntrHrztlPostn "SNM";
BA_ "SignalLongName" SG_ 271 RH_GFA7_CntrVrtclPostn "Right Headlamp Glare Free Area 7 Center Vertical Position";
BA_ "SignalType" SG_ 271 RH_GFA7_CntrVrtclPostn "SNM";
BA_ "SignalLongName" SG_ 271 RH_GFA7_HrztlHlfWidt "Right Headlamp Glare Free Area 7 Horizontal Half Width";
BA_ "SignalType" SG_ 271 RH_GFA7_HrztlHlfWidt "UNM";
BA_ "SignalLongName" SG_ 271 RH_GFA7_VrtclHlfWidt "Right Headlamp Glare Free Area 7 Vertical Half Width";
BA_ "SignalType" SG_ 271 RH_GFA7_VrtclHlfWidt "UNM";
BA_ "SignalLongName" SG_ 271 RH_GFA7_Prsnc "Right Headlamp Glare Free Area 7 Presence";
BA_ "SignalType" SG_ 271 RH_GFA7_Prsnc "ENM";
BA_ "SignalLongName" SG_ 271 RH_GFA7_DimVal "Right Headlamp Glare Free Area 7 Dim Value";
BA_ "SignalType" SG_ 271 RH_GFA7_DimVal "UNM";
BA_ "SignalLongName" SG_ 271 RH_GFA7_DimUpTime "Right Headlamp Glare Free Area 7 Dim Up Time";
BA_ "SignalType" SG_ 271 RH_GFA7_DimUpTime "UNM";
BA_ "SignalLongName" SG_ 271 RH_GFA7_DimDwnTime "Right Headlamp Glare Free Area 7 Dim Down Time";
BA_ "SignalType" SG_ 271 RH_GFA7_DimDwnTime "UNM";
BA_ "SignalLongName" SG_ 272 LH_GFA8_Chcksm "Left Headlamp Glare Free Area 8 Checksum";
BA_ "SignalType" SG_ 272 LH_GFA8_Chcksm "UNM";
BA_ "SignalLongName" SG_ 272 LH_GFA8_MssgCntr "Left Headlamp Glare Free Area 8 Message Counter";
BA_ "SignalType" SG_ 272 LH_GFA8_MssgCntr "UNM";
BA_ "SignalLongName" SG_ 272 LH_GFA8_CntrHrztlPostn "Left Headlamp Glare Free Area 8 Center Horizontal Position";
BA_ "SignalType" SG_ 272 LH_GFA8_CntrHrztlPostn "SNM";
BA_ "SignalLongName" SG_ 272 LH_GFA8_CntrVrtclPostn "Left Headlamp Glare Free Area 8 Center Vertical Position";
BA_ "SignalType" SG_ 272 LH_GFA8_CntrVrtclPostn "SNM";
BA_ "SignalLongName" SG_ 272 LH_GFA8_HrztlHlfWidt "Left Headlamp Glare Free Area 8 Horizontal Half Width";
BA_ "SignalType" SG_ 272 LH_GFA8_HrztlHlfWidt "UNM";
BA_ "SignalLongName" SG_ 272 LH_GFA8_VrtclHlfWidt "Left Headlamp Glare Free Area 8 Vertical Half Width";
BA_ "SignalType" SG_ 272 LH_GFA8_VrtclHlfWidt "UNM";
BA_ "SignalLongName" SG_ 272 LH_GFA8_Prsnc "Left Headlamp Glare Free Area 8 Presence";
BA_ "SignalType" SG_ 272 LH_GFA8_Prsnc "ENM";
BA_ "SignalLongName" SG_ 272 LH_GFA8_DimVal "Left Headlamp Glare Free Area 8 Dim Value";
BA_ "SignalType" SG_ 272 LH_GFA8_DimVal "UNM";
BA_ "SignalLongName" SG_ 272 LH_GFA8_DimUpTime "Left Headlamp Glare Free Area 8 Dim Up Time";
BA_ "SignalType" SG_ 272 LH_GFA8_DimUpTime "UNM";
BA_ "SignalLongName" SG_ 272 LH_GFA8_DimDwnTime "Left Headlamp Glare Free Area 8 Dim Down Time";
BA_ "SignalType" SG_ 272 LH_GFA8_DimDwnTime "UNM";
BA_ "SignalLongName" SG_ 273 RH_GFA8_Chcksm "Right Headlamp Glare Free Area 8 Checksum";
BA_ "SignalType" SG_ 273 RH_GFA8_Chcksm "UNM";
BA_ "SignalLongName" SG_ 273 RH_GFA8_MssgCntr "Right Headlamp Glare Free Area 8 Message Counter";
BA_ "SignalType" SG_ 273 RH_GFA8_MssgCntr "UNM";
BA_ "SignalLongName" SG_ 273 RH_GFA8_CntrHrztlPostn "Right Headlamp Glare Free Area 8 Center Horizontal Position";
BA_ "SignalType" SG_ 273 RH_GFA8_CntrHrztlPostn "SNM";
BA_ "SignalLongName" SG_ 273 RH_GFA8_CntrVrtclPostn "Right Headlamp Glare Free Area 8 Center Vertical Position";
BA_ "SignalType" SG_ 273 RH_GFA8_CntrVrtclPostn "SNM";
BA_ "SignalLongName" SG_ 273 RH_GFA8_HrztlHlfWidt "Right Headlamp Glare Free Area 8 Horizontal Half Width";
BA_ "SignalType" SG_ 273 RH_GFA8_HrztlHlfWidt "UNM";
BA_ "SignalLongName" SG_ 273 RH_GFA8_VrtclHlfWidt "Right Headlamp Glare Free Area 8 Vertical Half Width";
BA_ "SignalType" SG_ 273 RH_GFA8_VrtclHlfWidt "UNM";
BA_ "SignalLongName" SG_ 273 RH_GFA8_Prsnc "Right Headlamp Glare Free Area 8 Presence";
BA_ "SignalType" SG_ 273 RH_GFA8_Prsnc "ENM";
BA_ "SignalLongName" SG_ 273 RH_GFA8_DimVal "Right Headlamp Glare Free Area 8 Dim Value";
BA_ "SignalType" SG_ 273 RH_GFA8_DimVal "UNM";
BA_ "SignalLongName" SG_ 273 RH_GFA8_DimUpTime "Right Headlamp Glare Free Area 8 Dim Up Time";
BA_ "SignalType" SG_ 273 RH_GFA8_DimUpTime "UNM";
BA_ "SignalLongName" SG_ 273 RH_GFA8_DimDwnTime "Right Headlamp Glare Free Area 8 Dim Down Time";
BA_ "SignalType" SG_ 273 RH_GFA8_DimDwnTime "UNM";
BA_ "SignalLongName" SG_ 513 HLS_Chcksm "Headlamp Levelling Checksum";
BA_ "SignalType" SG_ 513 HLS_Chcksm "UNM";
BA_ "SignalLongName" SG_ 513 HLS_MssgCntr "Headlamp Levelling Message Counter";
BA_ "SignalType" SG_ 513 HLS_MssgCntr "UNM";
BA_ "SignalLongName" SG_ 513 HLS_LftHdlmpLvllngPstn "Left Headlamp Levelling Position";
BA_ "SignalType" SG_ 513 HLS_LftHdlmpLvllngPstn "SNM";
BA_ "SignalLongName" SG_ 513 HLS_RghtHdlmpLvllngPstn "Right Headlamp Levelling Position";
BA_ "SignalType" SG_ 513 HLS_RghtHdlmpLvllngPstn "SNM";
BA_ "SignalLongName" SG_ 513 HLS_LftHdlmpLvllngStat "Left Headlamp Levelling Status";
BA_ "SignalType" SG_ 513 HLS_LftHdlmpLvllngStat "ENM";
BA_ "SignalLongName" SG_ 513 HLS_RghtHdlmpLvllngStat "Right Headlamp Levelling Status";
BA_ "SignalType" SG_ 513 HLS_RghtHdlmpLvllngStat "ENM";
BA_ "SignalLongName" SG_ 525 VED_Chcksm "Vehicle Environment Data Information Checksum";
BA_ "SignalType" SG_ 525 VED_Chcksm "UNM";
BA_ "SignalLongName" SG_ 525 VED_MssgCntr "Vehicle Environment Data Information Message Counter";
BA_ "SignalType" SG_ 525 VED_MssgCntr "UNM";
BA_ "SignalLongName" SG_ 525 VhclSpd "Vehicle Speed";
BA_ "SignalType" SG_ 525 VhclSpd "UNM";
BA_ "SignalLongName" SG_ 525 RfrncRun "Reference Run";
BA_ "SignalType" SG_ 525 RfrncRun "ENM";
BA_ "SignalLongName" SG_ 525 TrffcMd "Traffic Mode";
BA_ "SignalType" SG_ 525 TrffcMd "ENM";
BA_ "SignalLongName" SG_ 525 TourstMd "Tourist Mode";
BA_ "SignalType" SG_ 525 TourstMd "ENM";
BA_ "SignalLongName" SG_ 515 SlpRdy "AFL node sleep ready broadcast";
BA_ "SignalType" SG_ 515 SlpRdy "ENM";
BA_ "SignalLongName" SG_ 515 LghtDstrbtnSelt "Headlamp light distrubtion selt";
BA_ "SignalType" SG_ 515 LghtDstrbtnSelt "ENM";
BA_ "SignalLongName" SG_ 515 HbMdSelt "HighBeam mode selt";
BA_ "SignalType" SG_ 515 HbMdSelt "ENM";
BA_ "SignalLongName" SG_ 515 LftBndCmd "Left Bending Dim Value Command";
BA_ "SignalType" SG_ 515 LftBndCmd "UNM";
BA_ "SignalLongName" SG_ 515 RghtBndCmd "Right Bending Dim Value Command";
BA_ "SignalType" SG_ 515 RghtBndCmd "UNM";
BA_ "SignalLongName" SG_ 1026 SystmStat_Chcksm_HLS_LH "Left Headlamp Levelling Checksum";
BA_ "SignalType" SG_ 1026 SystmStat_Chcksm_HLS_LH "UNM";
BA_ "SignalLongName" SG_ 1026 SystmStat_MssgCntr_HLS_LH "Left Headlamp Levelling Message Counter";
BA_ "SignalType" SG_ 1026 SystmStat_MssgCntr_HLS_LH "UNM";
BA_ "SignalLongName" SG_ 1026 SystmStat_ShrtCirctFail_HLS_LH "Left Headlamp Levelling Short Circuit Failed";
BA_ "SignalType" SG_ 1026 SystmStat_ShrtCirctFail_HLS_LH "BLN";
BA_ "SignalLongName" SG_ 1026 SystmStat_OpnLoadFail_HLS_LH "Left Headlamp Levelling Open Load Failed";
BA_ "SignalType" SG_ 1026 SystmStat_OpnLoadFail_HLS_LH "BLN";
BA_ "SignalLongName" SG_ 1026 SystmStat_IntrnlSysFail_HLS_LH "Left Headlamp Levelling Internal System Failed";
BA_ "SignalType" SG_ 1026 SystmStat_IntrnlSysFail_HLS_LH "BLN";
BA_ "SignalLongName" SG_ 1026 SystmStat_OvrVltgFail_HLS_LH "Left Headlamp Levelling Over Voltage Failed";
BA_ "SignalType" SG_ 1026 SystmStat_OvrVltgFail_HLS_LH "BLN";
BA_ "SignalLongName" SG_ 1026 SystmStat_UndVltgFail_HLS_LH "Left Headlamp Levelling Under Voltage Failed";
BA_ "SignalType" SG_ 1026 SystmStat_UndVltgFail_HLS_LH "BLN";
BA_ "SignalLongName" SG_ 1026 SystmStat_ActutorFail_HLS_LH "Left Headlamp Levelling Actuator Failed";
BA_ "SignalType" SG_ 1026 SystmStat_ActutorFail_HLS_LH "BLN";
BA_ "SignalLongName" SG_ 1026 SystmStat_IntnlTempFail_HLS_LH "Left Headlamp Levelling Internal Temperature Failed";
BA_ "SignalType" SG_ 1026 SystmStat_IntnlTempFail_HLS_LH "BLN";
BA_ "SignalLongName" SG_ 1026 SystmStat_ExtTempFail_HLS_LH "Left Headlamp Levelling External Temperature Failed";
BA_ "SignalType" SG_ 1026 SystmStat_ExtTempFail_HLS_LH "BLN";
BA_ "SignalLongName" SG_ 1026 SystmStat_CurntCdngFail_HLS_LH "Left Headlamp Levelling Current Coding Failed";
BA_ "SignalType" SG_ 1026 SystmStat_CurntCdngFail_HLS_LH "BLN";
BA_ "SignalLongName" SG_ 1026 SystmStat_FanFail_HLS_LH "Left Headlamp Levelling FAN Failed";
BA_ "SignalType" SG_ 1026 SystmStat_FanFail_HLS_LH "BLN";
BA_ "SignalLongName" SG_ 1026 SystmStat_MstrMsgFail_HLS_LH "Left Headlamp Levelling Master ECU Message Failed";
BA_ "SignalType" SG_ 1026 SystmStat_MstrMsgFail_HLS_LH "BLN";
BA_ "SignalLongName" SG_ 1026 SystmStat_OverTempFail_HLS_LH "Left Headlamp Levelling Over Temperature Failed";
BA_ "SignalType" SG_ 1026 SystmStat_OverTempFail_HLS_LH "BLN";
BA_ "SignalLongName" SG_ 1026 SystmStat_IncCompFail_HLS_LH "Left Headlamp Levelling Incorrect Component Failed";
BA_ "SignalType" SG_ 1026 SystmStat_IncCompFail_HLS_LH "BLN";
BA_ "SignalLongName" SG_ 1026 SystmStat_CSorMCFail_HLS_LH "Left Headlamp Levelling Checksum or Message Counter Failed";
BA_ "SignalType" SG_ 1026 SystmStat_CSorMCFail_HLS_LH "BLN";
BA_ "SignalLongName" SG_ 1026 SystmStat_R_L_DtctnFail_HLS_LH "Left Headlamp Levelling Right/Left Side Detection Failed";
BA_ "SignalType" SG_ 1026 SystmStat_R_L_DtctnFail_HLS_LH "BLN";
BA_ "SignalLongName" SG_ 1026 SystmStat_FnctnStat_HLS_LH "Left Headlamp Levelling Function Status";
BA_ "SignalType" SG_ 1026 SystmStat_FnctnStat_HLS_LH "BLN";
BA_ "SignalLongName" SG_ 1026 SystmStat_SpplyVltgVal_HLS_LH "Left Headlamp Levelling Supply Voltage Value";
BA_ "SignalType" SG_ 1026 SystmStat_SpplyVltgVal_HLS_LH "UNM";
BA_ "SignalLongName" SG_ 1026 SystmStat_ExtTempVal_HLS_LH "Left Headlamp Levelling External Temperature Value";
BA_ "SignalType" SG_ 1026 SystmStat_ExtTempVal_HLS_LH "UNM";
BA_ "GenSigStartValue" SG_ 1026 SystmStat_ExtTempVal_HLS_LH 50;
BA_ "SignalLongName" SG_ 1026 SystmStat_IntTempVal_HLS_LH "Left Headlamp Levelling Internal Temperature Value";
BA_ "SignalType" SG_ 1026 SystmStat_IntTempVal_HLS_LH "UNM";
BA_ "GenSigStartValue" SG_ 1026 SystmStat_IntTempVal_HLS_LH 50;
BA_ "SignalLongName" SG_ 1026 SystmStat_RefrncRunStat_HLS_LH "Left Headlamp Levelling Reference Run Status";
BA_ "SignalType" SG_ 1026 SystmStat_RefrncRunStat_HLS_LH "ENM";
BA_ "SignalLongName" SG_ 1026 SystmStat_DertngStat_HLS_LH "Left Headlamp Levelling Derating Status";
BA_ "SignalType" SG_ 1026 SystmStat_DertngStat_HLS_LH "ENM";
BA_ "SignalLongName" SG_ 1026 SystmStat_SysCalibStat_HLS_LH "Left Headlamp Levelling System Information Calibration Status";
BA_ "SignalType" SG_ 1026 SystmStat_SysCalibStat_HLS_LH "ENM";
BA_ "SignalLongName" SG_ 1026 SystmStat_VINStat_HLS_LH "Left Headlamp Levelling VIN Status";
BA_ "SignalType" SG_ 1026 SystmStat_VINStat_HLS_LH "ENM";
BA_ "SignalLongName" SG_ 1027 SystmStat_Chcksm_HLS_RH "Right Headlamp Levelling Checksum";
BA_ "SignalType" SG_ 1027 SystmStat_Chcksm_HLS_RH "UNM";
BA_ "SignalLongName" SG_ 1027 SystmStat_MssgCntr_HLS_RH "Right Headlamp Levelling Message Counter";
BA_ "SignalType" SG_ 1027 SystmStat_MssgCntr_HLS_RH "UNM";
BA_ "SignalLongName" SG_ 1027 SystmStat_ShrtCirctFail_HLS_RH "Right Headlamp Levelling Short Circuit Failed";
BA_ "SignalType" SG_ 1027 SystmStat_ShrtCirctFail_HLS_RH "BLN";
BA_ "SignalLongName" SG_ 1027 SystmStat_OpnLoadFail_HLS_RH "Right Headlamp Levelling Open Load Failed";
BA_ "SignalType" SG_ 1027 SystmStat_OpnLoadFail_HLS_RH "BLN";
BA_ "SignalLongName" SG_ 1027 SystmStat_IntrnlSysFail_HLS_RH "Right Headlamp Levelling Internal System Failed";
BA_ "SignalType" SG_ 1027 SystmStat_IntrnlSysFail_HLS_RH "BLN";
BA_ "SignalLongName" SG_ 1027 SystmStat_OvrVltgFail_HLS_RH "Right Headlamp Levelling Over Voltage Failed";
BA_ "SignalType" SG_ 1027 SystmStat_OvrVltgFail_HLS_RH "BLN";
BA_ "SignalLongName" SG_ 1027 SystmStat_UndVltgFail_HLS_RH "Right Headlamp Levelling Under Voltage Failed";
BA_ "SignalType" SG_ 1027 SystmStat_UndVltgFail_HLS_RH "BLN";
BA_ "SignalLongName" SG_ 1027 SystmStat_ActutorFail_HLS_RH "Right Headlamp Levelling Actuator Failed";
BA_ "SignalType" SG_ 1027 SystmStat_ActutorFail_HLS_RH "BLN";
BA_ "SignalLongName" SG_ 1027 SystmStat_IntnlTempFail_HLS_RH "Right Headlamp Levelling Internal Temperature Failed";
BA_ "SignalType" SG_ 1027 SystmStat_IntnlTempFail_HLS_RH "BLN";
BA_ "SignalLongName" SG_ 1027 SystmStat_ExtTempFail_HLS_RH "Right Headlamp Levelling External Temperature Failed";
BA_ "SignalType" SG_ 1027 SystmStat_ExtTempFail_HLS_RH "BLN";
BA_ "SignalLongName" SG_ 1027 SystmStat_CurntCdngFail_HLS_RH "Right Headlamp Levelling Current Coding Failed";
BA_ "SignalType" SG_ 1027 SystmStat_CurntCdngFail_HLS_RH "BLN";
BA_ "SignalLongName" SG_ 1027 SystmStat_FanFail_HLS_RH "Right Headlamp Levelling FAN Failed";
BA_ "SignalType" SG_ 1027 SystmStat_FanFail_HLS_RH "BLN";
BA_ "SignalLongName" SG_ 1027 SystmStat_MstrMsgFail_HLS_RH "Right Headlamp Levelling Master ECU Message Failed";
BA_ "SignalType" SG_ 1027 SystmStat_MstrMsgFail_HLS_RH "BLN";
BA_ "SignalLongName" SG_ 1027 SystmStat_OverTempFail_HLS_RH "Right Headlamp Levelling Over Temperature Failed";
BA_ "SignalType" SG_ 1027 SystmStat_OverTempFail_HLS_RH "BLN";
BA_ "SignalLongName" SG_ 1027 SystmStat_IncCompFail_HLS_RH "Right Headlamp Levelling Incorrect Component Failed";
BA_ "SignalType" SG_ 1027 SystmStat_IncCompFail_HLS_RH "BLN";
BA_ "SignalLongName" SG_ 1027 SystmStat_CSorMCFail_HLS_RH "Right Headlamp Levelling Checksum or Message Counter Failed";
BA_ "SignalType" SG_ 1027 SystmStat_CSorMCFail_HLS_RH "BLN";
BA_ "SignalLongName" SG_ 1027 SystmStat_R_L_DtctnFail_HLS_RH "Right Headlamp Levelling Right/Left Side Detection Failed";
BA_ "SignalType" SG_ 1027 SystmStat_R_L_DtctnFail_HLS_RH "BLN";
BA_ "SignalLongName" SG_ 1027 SystmStat_FnctnStat_HLS_RH "Right Headlamp Levelling Function Status";
BA_ "SignalType" SG_ 1027 SystmStat_FnctnStat_HLS_RH "BLN";
BA_ "SignalLongName" SG_ 1027 SystmStat_SpplyVltgVal_HLS_RH "Right Headlamp Levelling Supply Voltage Value";
BA_ "SignalType" SG_ 1027 SystmStat_SpplyVltgVal_HLS_RH "UNM";
BA_ "SignalLongName" SG_ 1027 SystmStat_ExtTempVal_HLS_RH "Right Headlamp Levelling External Temperature Value";
BA_ "SignalType" SG_ 1027 SystmStat_ExtTempVal_HLS_RH "UNM";
BA_ "GenSigStartValue" SG_ 1027 SystmStat_ExtTempVal_HLS_RH 50;
BA_ "SignalLongName" SG_ 1027 SystmStat_IntTempVal_HLS_RH "Right Headlamp Levelling Internal Temperature Value";
BA_ "SignalType" SG_ 1027 SystmStat_IntTempVal_HLS_RH "UNM";
BA_ "GenSigStartValue" SG_ 1027 SystmStat_IntTempVal_HLS_RH 50;
BA_ "SignalLongName" SG_ 1027 SystmStat_RefrncRunStat_HLS_RH "Right Headlamp Levelling Reference Run Status";
BA_ "SignalType" SG_ 1027 SystmStat_RefrncRunStat_HLS_RH "ENM";
BA_ "SignalLongName" SG_ 1027 SystmStat_DertngStat_HLS_RH "Right Headlamp Levelling Derating Status";
BA_ "SignalType" SG_ 1027 SystmStat_DertngStat_HLS_RH "ENM";
BA_ "SignalLongName" SG_ 1027 SystmStat_SysCalibStat_HLS_RH "Right Headlamp Levelling System Information Calibration Status";
BA_ "SignalType" SG_ 1027 SystmStat_SysCalibStat_HLS_RH "ENM";
BA_ "SignalLongName" SG_ 1027 SystmStat_VINStat_HLS_RH "Right Headlamp Levelling VIN Status";
BA_ "SignalType" SG_ 1027 SystmStat_VINStat_HLS_RH "ENM";
BA_ "SignalLongName" SG_ 1554 LftHdlmpLvllngActPstn "Left Headlamp Levelling Actual Position";
BA_ "SignalType" SG_ 1554 LftHdlmpLvllngActPstn "SNM";
BA_ "SignalLongName" SG_ 1555 RtHdlmpLvllngActPstn "Right Headlamp Levelling Actual Position";
BA_ "SignalType" SG_ 1555 RtHdlmpLvllngActPstn "SNM";
BA_ "SignalLongName" SG_ 1552 LftHdlmpLgtShowWrkSts "Left Headlamp light show work status";
BA_ "SignalType" SG_ 1552 LftHdlmpLgtShowWrkSts "ENM";
BA_ "SignalLongName" SG_ 1552 LftLwBmCtrlSts "Left LowBeam control status";
BA_ "SignalType" SG_ 1552 LftLwBmCtrlSts "ENM";
BA_ "SignalLongName" SG_ 1552 LftHgBmCtrlSts "Left HighBeam control status";
BA_ "SignalType" SG_ 1552 LftHgBmCtrlSts "ENM";
BA_ "SignalLongName" SG_ 1552 LftBndActDim "Left Bending light actual dim value";
BA_ "SignalType" SG_ 1552 LftBndActDim "UNM";
BA_ "SignalLongName" SG_ 1552 LftBndCtrlSts "Left Bending light control status";
BA_ "SignalType" SG_ 1552 LftBndCtrlSts "ENM";
BA_ "SignalLongName" SG_ 1552 LftFrtTrnCtrlSts "Left Front turnning lamp control status";
BA_ "SignalType" SG_ 1552 LftFrtTrnCtrlSts "ENM";
BA_ "SignalLongName" SG_ 1552 LftDrlPlCtrlSts "Left Daytime running lamp/position control status";
BA_ "SignalType" SG_ 1552 LftDrlPlCtrlSts "ENM";
BA_ "SignalLongName" SG_ 1552 LftAuxLbCtrlSts "Left Aux lowbeam control status";
BA_ "SignalType" SG_ 1552 LftAuxLbCtrlSts "ENM";
BA_ "SignalLongName" SG_ 1552 LftAuxDrlPlCtrlSts "Left Aux Daytime running lamp/position lamp control status";
BA_ "SignalType" SG_ 1552 LftAuxDrlPlCtrlSts "ENM";
BA_ "SignalLongName" SG_ 1552 LftLdmConf "Left Ldm configuration";
BA_ "SignalType" SG_ 1552 LftLdmConf "ENM";
BA_ "SignalLongName" SG_ 1553 RtHdlmpLgtShowWrkSts "Right Headlamp light show work status";
BA_ "SignalType" SG_ 1553 RtHdlmpLgtShowWrkSts "ENM";
BA_ "SignalLongName" SG_ 1553 RtLwBmCtrlSts "Right LowBeam control status";
BA_ "SignalType" SG_ 1553 RtLwBmCtrlSts "ENM";
BA_ "SignalLongName" SG_ 1553 RtHgBmCtrlSts "Right HighBeam control status";
BA_ "SignalType" SG_ 1553 RtHgBmCtrlSts "ENM";
BA_ "SignalLongName" SG_ 1553 RtBndActDim "Right Bending light actual dim value";
BA_ "SignalType" SG_ 1553 RtBndActDim "UNM";
BA_ "SignalLongName" SG_ 1553 RtBndCtrlSts "Right Bending light control status";
BA_ "SignalType" SG_ 1553 RtBndCtrlSts "ENM";
BA_ "SignalLongName" SG_ 1553 RtFrtTrnCtrlSts "Right Front turnning lamp control status";
BA_ "SignalType" SG_ 1553 RtFrtTrnCtrlSts "ENM";
BA_ "SignalLongName" SG_ 1553 RtDrlPlCtrlSts "Right Daytime running lamp/position control status";
BA_ "SignalType" SG_ 1553 RtDrlPlCtrlSts "ENM";
BA_ "SignalLongName" SG_ 1553 RtAuxLbCtrlSts "Right Aux lowbeam control status";
BA_ "SignalType" SG_ 1553 RtAuxLbCtrlSts "ENM";
BA_ "SignalLongName" SG_ 1553 RtAuxDrlPlCtrlSts "Right Aux Daytime running lamp/position lamp control status";
BA_ "SignalType" SG_ 1553 RtAuxDrlPlCtrlSts "ENM";
BA_ "SignalLongName" SG_ 1553 RtLdmConf "Right Ldm configuration";
BA_ "SignalType" SG_ 1553 RtLdmConf "ENM";
BA_ "SignalLongName" SG_ 1556 SysOvErrLH "power supply above lamp work range LH";
BA_ "SignalType" SG_ 1556 SysOvErrLH "ENM";
BA_ "SignalLongName" SG_ 1556 SysUvErrLH "power supply under lamp work range LH";
BA_ "SignalType" SG_ 1556 SysUvErrLH "ENM";
BA_ "SignalLongName" SG_ 1556 BstErrLH "boost chip output out of range LH";
BA_ "SignalType" SG_ 1556 BstErrLH "ENM";
BA_ "SignalLongName" SG_ 1556 UartCan2ErrLH "uartcan2 transmit error LH";
BA_ "SignalType" SG_ 1556 UartCan2ErrLH "ENM";
BA_ "SignalLongName" SG_ 1556 UartCan1ErrLH "uartcan1 transmit error LH";
BA_ "SignalType" SG_ 1556 UartCan1ErrLH "ENM";
BA_ "SignalLongName" SG_ 1556 PwrCh9ErrLH "power channel9 open/short circuit LH";
BA_ "SignalType" SG_ 1556 PwrCh9ErrLH "ENM";
BA_ "SignalLongName" SG_ 1556 Bin8ErrLH "Vbin8 out of range LH";
BA_ "SignalType" SG_ 1556 Bin8ErrLH "ENM";
BA_ "SignalLongName" SG_ 1556 Bin7ErrLH "Vbin7 out of range LH";
BA_ "SignalType" SG_ 1556 Bin7ErrLH "ENM";
BA_ "SignalLongName" SG_ 1556 Bin6ErrLH "Vbin6 out of range LH";
BA_ "SignalType" SG_ 1556 Bin6ErrLH "ENM";
BA_ "SignalLongName" SG_ 1556 Bin5ErrLH "Vbin5 out of range LH";
BA_ "SignalType" SG_ 1556 Bin5ErrLH "ENM";
BA_ "SignalLongName" SG_ 1556 Bin4ErrLH "Vbin4 out of range LH";
BA_ "SignalType" SG_ 1556 Bin4ErrLH "ENM";
BA_ "SignalLongName" SG_ 1556 Bin3ErrLH "Vbin3 out of range LH";
BA_ "SignalType" SG_ 1556 Bin3ErrLH "ENM";
BA_ "SignalLongName" SG_ 1556 Bin2ErrLH "Vbin2 out of range LH";
BA_ "SignalType" SG_ 1556 Bin2ErrLH "ENM";
BA_ "SignalLongName" SG_ 1556 Bin1ErrLH "Vbin1 out of range LH";
BA_ "SignalType" SG_ 1556 Bin1ErrLH "ENM";
BA_ "SignalLongName" SG_ 1556 Ntc8ErrLH "Ntc8 open/short circuit LH";
BA_ "SignalType" SG_ 1556 Ntc8ErrLH "ENM";
BA_ "SignalLongName" SG_ 1556 Ntc7ErrLH "Ntc7 open/short circuit LH";
BA_ "SignalType" SG_ 1556 Ntc7ErrLH "ENM";
BA_ "SignalLongName" SG_ 1556 Ntc6ErrLH "Ntc6 open/short circuit LH";
BA_ "SignalType" SG_ 1556 Ntc6ErrLH "ENM";
BA_ "SignalLongName" SG_ 1556 Ntc5ErrLH "Ntc5 open/short circuit LH";
BA_ "SignalType" SG_ 1556 Ntc5ErrLH "ENM";
BA_ "SignalLongName" SG_ 1556 Ntc4ErrLH "Ntc4 open/short circuit LH";
BA_ "SignalType" SG_ 1556 Ntc4ErrLH "ENM";
BA_ "SignalLongName" SG_ 1556 Ntc3ErrLH "Ntc3 open/short circuit LH";
BA_ "SignalType" SG_ 1556 Ntc3ErrLH "ENM";
BA_ "SignalLongName" SG_ 1556 Ntc2ErrLH "Ntc2 open/short circuit LH";
BA_ "SignalType" SG_ 1556 Ntc2ErrLH "ENM";
BA_ "SignalLongName" SG_ 1556 Ntc1ErrLH "Ntc1 open/short circuit LH";
BA_ "SignalType" SG_ 1556 Ntc1ErrLH "ENM";
BA_ "SignalLongName" SG_ 1556 PwrCh1ErrLH "power channel8 open/short circuit LH";
BA_ "SignalType" SG_ 1556 PwrCh1ErrLH "ENM";
BA_ "SignalLongName" SG_ 1556 PwrCh2ErrLH "power channel7 open/short circuit LH";
BA_ "SignalType" SG_ 1556 PwrCh2ErrLH "ENM";
BA_ "SignalLongName" SG_ 1556 PwrCh3ErrLH "power channel6 open/short circuit LH";
BA_ "SignalType" SG_ 1556 PwrCh3ErrLH "ENM";
BA_ "SignalLongName" SG_ 1556 PwrCh4ErrLH "power channel5 open/short circuit LH";
BA_ "SignalType" SG_ 1556 PwrCh4ErrLH "ENM";
BA_ "SignalLongName" SG_ 1556 PwrCh5ErrLH "power channel4 open/short circuit LH";
BA_ "SignalType" SG_ 1556 PwrCh5ErrLH "ENM";
BA_ "SignalLongName" SG_ 1556 PwrCh6ErrLH "power channel3 open/short circuit LH";
BA_ "SignalType" SG_ 1556 PwrCh6ErrLH "ENM";
BA_ "SignalLongName" SG_ 1556 PwrCh7ErrLH "power channel2 open/short circuit LH";
BA_ "SignalType" SG_ 1556 PwrCh7ErrLH "ENM";
BA_ "SignalLongName" SG_ 1556 PwrCh8ErrLH "power channel1 open/short circuit LH";
BA_ "SignalType" SG_ 1556 PwrCh8ErrLH "ENM";
BA_ "SignalLongName" SG_ 1556 Can1BusOffLH "private can busoff LH";
BA_ "SignalType" SG_ 1556 Can1BusOffLH "ENM";
BA_ "SignalLongName" SG_ 1556 Can1N1LstLH "lost communciation with BCM LH";
BA_ "SignalType" SG_ 1556 Can1N1LstLH "ENM";
BA_ "SignalLongName" SG_ 1556 Can1N2LstLH "lost communication with ADB function node LH";
BA_ "SignalType" SG_ 1556 Can1N2LstLH "ENM";
BA_ "SignalLongName" SG_ 1556 Can1N3LstLH "lost communciation with leveling motor function node LH";
BA_ "SignalType" SG_ 1556 Can1N3LstLH "ENM";
BA_ "SignalLongName" SG_ 1556 Can1N1SigErrLH "bcm signal out of range or checksum error LH";
BA_ "SignalType" SG_ 1556 Can1N1SigErrLH "ENM";
BA_ "SignalLongName" SG_ 1556 Can1N2SigErrLH "adb signal out of range or checksum error LH";
BA_ "SignalType" SG_ 1556 Can1N2SigErrLH "ENM";
BA_ "SignalLongName" SG_ 1556 Can1N3SigErrLH "leveling motor signal out of range or checksum error LH";
BA_ "SignalType" SG_ 1556 Can1N3SigErrLH "ENM";
BA_ "SignalLongName" SG_ 1556 Can2N7LstErrLH "lost communication with matrix chip7 LH";
BA_ "SignalType" SG_ 1556 Can2N7LstErrLH "ENM";
BA_ "SignalLongName" SG_ 1556 Can2N6LstErrLH "lost communication with matrix chip6 LH";
BA_ "SignalType" SG_ 1556 Can2N6LstErrLH "ENM";
BA_ "SignalLongName" SG_ 1556 Can2N5LstErrLH "lost communication with matrix chip5 LH";
BA_ "SignalType" SG_ 1556 Can2N5LstErrLH "ENM";
BA_ "SignalLongName" SG_ 1556 Can2N4LstErrLH "lost communication with matrix chip4 LH";
BA_ "SignalType" SG_ 1556 Can2N4LstErrLH "ENM";
BA_ "SignalLongName" SG_ 1556 Can2N3LstErrLH "lost communication with matrix chip3 LH";
BA_ "SignalType" SG_ 1556 Can2N3LstErrLH "ENM";
BA_ "SignalLongName" SG_ 1556 Can2N2LstErrLH "lost communication with matrix chip2 LH";
BA_ "SignalType" SG_ 1556 Can2N2LstErrLH "ENM";
BA_ "SignalLongName" SG_ 1556 Can2N1LstErrLH "lost communication with matrix chip1 LH";
BA_ "SignalType" SG_ 1556 Can2N1LstErrLH "ENM";
BA_ "SignalLongName" SG_ 1556 Can2N0LstErrLH "lost communication with matrix chip0 LH";
BA_ "SignalType" SG_ 1556 Can2N0LstErrLH "ENM";
BA_ "SignalLongName" SG_ 1556 Can2N7LedErrLH "matrix chip7 led fault LH";
BA_ "SignalType" SG_ 1556 Can2N7LedErrLH "ENM";
BA_ "SignalLongName" SG_ 1556 Can2N6LedErrLH "matrix chip6 led fault LH";
BA_ "SignalType" SG_ 1556 Can2N6LedErrLH "ENM";
BA_ "SignalLongName" SG_ 1556 Can2N5LedErrLH "matrix chip5 led fault LH";
BA_ "SignalType" SG_ 1556 Can2N5LedErrLH "ENM";
BA_ "SignalLongName" SG_ 1556 Can2N4LedErrLH "matrix chip4 led fault LH";
BA_ "SignalType" SG_ 1556 Can2N4LedErrLH "ENM";
BA_ "SignalLongName" SG_ 1556 Can2N3LedErrLH "matrix chip3 led fault LH";
BA_ "SignalType" SG_ 1556 Can2N3LedErrLH "ENM";
BA_ "SignalLongName" SG_ 1556 Can2N2LedErrLH "matrix chip2 led fault LH";
BA_ "SignalType" SG_ 1556 Can2N2LedErrLH "ENM";
BA_ "SignalLongName" SG_ 1556 Can2N1LedErrLH "matrix chip1 led fault LH";
BA_ "SignalType" SG_ 1556 Can2N1LedErrLH "ENM";
BA_ "SignalLongName" SG_ 1556 Can2N0LedErrLH "matrix chip0 led fault LH";
BA_ "SignalType" SG_ 1556 Can2N0LedErrLH "ENM";
BA_ "SignalLongName" SG_ 1557 SysOvErrRH "power supply above lamp work range RH";
BA_ "SignalType" SG_ 1557 SysOvErrRH "ENM";
BA_ "SignalLongName" SG_ 1557 SysUvErrRH "power supply under lamp work range RH";
BA_ "SignalType" SG_ 1557 SysUvErrRH "ENM";
BA_ "SignalLongName" SG_ 1557 BstErrRH "boost chip output out of range RH";
BA_ "SignalType" SG_ 1557 BstErrRH "ENM";
BA_ "SignalLongName" SG_ 1557 UartCan2ErrRH "uartcan2 transmit error RH";
BA_ "SignalType" SG_ 1557 UartCan2ErrRH "ENM";
BA_ "SignalLongName" SG_ 1557 UartCan1ErrRH "uartcan1 transmit error RH";
BA_ "SignalType" SG_ 1557 UartCan1ErrRH "ENM";
BA_ "SignalLongName" SG_ 1557 PwrCh9ErrRH "power channel9 open/short circuit RH";
BA_ "SignalType" SG_ 1557 PwrCh9ErrRH "ENM";
BA_ "SignalLongName" SG_ 1557 Bin8ErrRH "Vbin8 out of range RH";
BA_ "SignalType" SG_ 1557 Bin8ErrRH "ENM";
BA_ "SignalLongName" SG_ 1557 Bin7ErrRH "Vbin7 out of range RH";
BA_ "SignalType" SG_ 1557 Bin7ErrRH "ENM";
BA_ "SignalLongName" SG_ 1557 Bin6ErrRH "Vbin6 out of range RH";
BA_ "SignalType" SG_ 1557 Bin6ErrRH "ENM";
BA_ "SignalLongName" SG_ 1557 Bin5ErrRH "Vbin5 out of range RH";
BA_ "SignalType" SG_ 1557 Bin5ErrRH "ENM";
BA_ "SignalLongName" SG_ 1557 Bin4ErrRH "Vbin4 out of range RH";
BA_ "SignalType" SG_ 1557 Bin4ErrRH "ENM";
BA_ "SignalLongName" SG_ 1557 Bin3ErrRH "Vbin3 out of range RH";
BA_ "SignalType" SG_ 1557 Bin3ErrRH "ENM";
BA_ "SignalLongName" SG_ 1557 Bin2ErrRH "Vbin2 out of range RH";
BA_ "SignalType" SG_ 1557 Bin2ErrRH "ENM";
BA_ "SignalLongName" SG_ 1557 Bin1ErrRH "Vbin1 out of range RH";
BA_ "SignalType" SG_ 1557 Bin1ErrRH "ENM";
BA_ "SignalLongName" SG_ 1557 Ntc8ErrRH "Ntc8 open/short circuit RH";
BA_ "SignalType" SG_ 1557 Ntc8ErrRH "ENM";
BA_ "SignalLongName" SG_ 1557 Ntc7ErrRH "Ntc7 open/short circuit RH";
BA_ "SignalType" SG_ 1557 Ntc7ErrRH "ENM";
BA_ "SignalLongName" SG_ 1557 Ntc6ErrRH "Ntc6 open/short circuit RH";
BA_ "SignalType" SG_ 1557 Ntc6ErrRH "ENM";
BA_ "SignalLongName" SG_ 1557 Ntc5ErrRH "Ntc5 open/short circuit RH";
BA_ "SignalType" SG_ 1557 Ntc5ErrRH "ENM";
BA_ "SignalLongName" SG_ 1557 Ntc4ErrRH "Ntc4 open/short circuit RH";
BA_ "SignalType" SG_ 1557 Ntc4ErrRH "ENM";
BA_ "SignalLongName" SG_ 1557 Ntc3ErrRH "Ntc3 open/short circuit RH";
BA_ "SignalType" SG_ 1557 Ntc3ErrRH "ENM";
BA_ "SignalLongName" SG_ 1557 Ntc2ErrRH "Ntc2 open/short circuit RH";
BA_ "SignalType" SG_ 1557 Ntc2ErrRH "ENM";
BA_ "SignalLongName" SG_ 1557 Ntc1ErrRH "Ntc1 open/short circuit RH";
BA_ "SignalType" SG_ 1557 Ntc1ErrRH "ENM";
BA_ "SignalLongName" SG_ 1557 PwrCh1ErrRH "power channel8 open/short circuit RH";
BA_ "SignalType" SG_ 1557 PwrCh1ErrRH "ENM";
BA_ "SignalLongName" SG_ 1557 PwrCh2ErrRH "power channel7 open/short circuit RH";
BA_ "SignalType" SG_ 1557 PwrCh2ErrRH "ENM";
BA_ "SignalLongName" SG_ 1557 PwrCh3ErrRH "power channel6 open/short circuit RH";
BA_ "SignalType" SG_ 1557 PwrCh3ErrRH "ENM";
BA_ "SignalLongName" SG_ 1557 PwrCh4ErrRH "power channel5 open/short circuit RH";
BA_ "SignalType" SG_ 1557 PwrCh4ErrRH "ENM";
BA_ "SignalLongName" SG_ 1557 PwrCh5ErrRH "power channel4 open/short circuit RH";
BA_ "SignalType" SG_ 1557 PwrCh5ErrRH "ENM";
BA_ "SignalLongName" SG_ 1557 PwrCh6ErrRH "power channel3 open/short circuit RH";
BA_ "SignalType" SG_ 1557 PwrCh6ErrRH "ENM";
BA_ "SignalLongName" SG_ 1557 PwrCh7ErrRH "power channel2 open/short circuit RH";
BA_ "SignalType" SG_ 1557 PwrCh7ErrRH "ENM";
BA_ "SignalLongName" SG_ 1557 PwrCh8ErrRH "power channel1 open/short circuit RH";
BA_ "SignalType" SG_ 1557 PwrCh8ErrRH "ENM";
BA_ "SignalLongName" SG_ 1557 Can1BusOffRH "private can busoff RH";
BA_ "SignalType" SG_ 1557 Can1BusOffRH "ENM";
BA_ "SignalLongName" SG_ 1557 Can1N1LstRH "lost communciation with BCM RH";
BA_ "SignalType" SG_ 1557 Can1N1LstRH "ENM";
BA_ "SignalLongName" SG_ 1557 Can1N2LstRH "lost communication with ADB function node RH";
BA_ "SignalType" SG_ 1557 Can1N2LstRH "ENM";
BA_ "SignalLongName" SG_ 1557 Can1N3LstRH "lost communciation with leveling motor function node RH";
BA_ "SignalType" SG_ 1557 Can1N3LstRH "ENM";
BA_ "SignalLongName" SG_ 1557 Can1N1SigErrRH "bcm signal out of range or checksum error RH";
BA_ "SignalType" SG_ 1557 Can1N1SigErrRH "ENM";
BA_ "SignalLongName" SG_ 1557 Can1N2SigErrRH "adb signal out of range or checksum error RH";
BA_ "SignalType" SG_ 1557 Can1N2SigErrRH "ENM";
BA_ "SignalLongName" SG_ 1557 Can1N3SigErrRH "leveling motor signal out of range or checksum error RH";
BA_ "SignalType" SG_ 1557 Can1N3SigErrRH "ENM";
BA_ "SignalLongName" SG_ 1557 Can2N7LstErrRH "lost communication with matrix chip7 RH";
BA_ "SignalType" SG_ 1557 Can2N7LstErrRH "ENM";
BA_ "SignalLongName" SG_ 1557 Can2N6LstErrRH "lost communication with matrix chip6 RH";
BA_ "SignalType" SG_ 1557 Can2N6LstErrRH "ENM";
BA_ "SignalLongName" SG_ 1557 Can2N5LstErrRH "lost communication with matrix chip5 RH";
BA_ "SignalType" SG_ 1557 Can2N5LstErrRH "ENM";
BA_ "SignalLongName" SG_ 1557 Can2N4LstErrRH "lost communication with matrix chip4 RH";
BA_ "SignalType" SG_ 1557 Can2N4LstErrRH "ENM";
BA_ "SignalLongName" SG_ 1557 Can2N3LstErrRH "lost communication with matrix chip3 RH";
BA_ "SignalType" SG_ 1557 Can2N3LstErrRH "ENM";
BA_ "SignalLongName" SG_ 1557 Can2N2LstErrRH "lost communication with matrix chip2 RH";
BA_ "SignalType" SG_ 1557 Can2N2LstErrRH "ENM";
BA_ "SignalLongName" SG_ 1557 Can2N1LstErrRH "lost communication with matrix chip1 RH";
BA_ "SignalType" SG_ 1557 Can2N1LstErrRH "ENM";
BA_ "SignalLongName" SG_ 1557 Can2N0LstErrRH "lost communication with matrix chip0 RH";
BA_ "SignalType" SG_ 1557 Can2N0LstErrRH "ENM";
BA_ "SignalLongName" SG_ 1557 Can2N7LedErrRH "matrix chip7 led fault RH";
BA_ "SignalType" SG_ 1557 Can2N7LedErrRH "ENM";
BA_ "SignalLongName" SG_ 1557 Can2N6LedErrRH "matrix chip6 led fault RH";
BA_ "SignalType" SG_ 1557 Can2N6LedErrRH "ENM";
BA_ "SignalLongName" SG_ 1557 Can2N5LedErrRH "matrix chip5 led fault RH";
BA_ "SignalType" SG_ 1557 Can2N5LedErrRH "ENM";
BA_ "SignalLongName" SG_ 1557 Can2N4LedErrRH "matrix chip4 led fault RH";
BA_ "SignalType" SG_ 1557 Can2N4LedErrRH "ENM";
BA_ "SignalLongName" SG_ 1557 Can2N3LedErrRH "matrix chip3 led fault RH";
BA_ "SignalType" SG_ 1557 Can2N3LedErrRH "ENM";
BA_ "SignalLongName" SG_ 1557 Can2N2LedErrRH "matrix chip2 led fault RH";
BA_ "SignalType" SG_ 1557 Can2N2LedErrRH "ENM";
BA_ "SignalLongName" SG_ 1557 Can2N1LedErrRH "matrix chip1 led fault RH";
BA_ "SignalType" SG_ 1557 Can2N1LedErrRH "ENM";
BA_ "SignalLongName" SG_ 1557 Can2N0LedErrRH "matrix chip0 led fault RH";
BA_ "SignalType" SG_ 1557 Can2N0LedErrRH "ENM";
BA_ "SignalLongName" SG_ 393 FrtLtShwMode "Front Light Show Mode";
BA_ "SignalType" SG_ 393 FrtLtShwMode "ENM";
BA_ "GenSigSendType" SG_ 393 FrtLtShwMode 3;
BA_ "SignalLongName" SG_ 393 FrtLtShwType "Front Light Show Type";
BA_ "SignalType" SG_ 393 FrtLtShwType "ENM";
BA_ "GenSigSendType" SG_ 393 FrtLtShwType 3;
BA_ "SignalLongName" SG_ 390 LftDRLCmd "Left Daytime Running Lamp command";
BA_ "SignalType" SG_ 390 LftDRLCmd "ENM";
BA_ "GenSigSendType" SG_ 390 LftDRLCmd 3;
BA_ "SignalLongName" SG_ 390 LftDRLDimValue "Left Daytime Running Lamp dim value";
BA_ "SignalType" SG_ 390 LftDRLDimValue "UNM";
BA_ "GenSigSendType" SG_ 390 LftDRLDimValue 3;
BA_ "SignalLongName" SG_ 390 RtDRLCmd "Right Daytime Running Lamp command";
BA_ "SignalType" SG_ 390 RtDRLCmd "ENM";
BA_ "GenSigSendType" SG_ 390 RtDRLCmd 3;
BA_ "SignalLongName" SG_ 390 RtDRLDimValue "Right Daytime Running Lamp dim value";
BA_ "SignalType" SG_ 390 RtDRLDimValue "UNM";
BA_ "GenSigSendType" SG_ 390 RtDRLDimValue 3;
BA_ "SignalLongName" SG_ 390 LftPrkLmpCmd "Left Park Lamp command";
BA_ "SignalType" SG_ 390 LftPrkLmpCmd "ENM";
BA_ "GenSigSendType" SG_ 390 LftPrkLmpCmd 3;
BA_ "SignalLongName" SG_ 390 LftPrkLmpDimValue "Left Park Lamp dim value";
BA_ "SignalType" SG_ 390 LftPrkLmpDimValue "UNM";
BA_ "GenSigSendType" SG_ 390 LftPrkLmpDimValue 3;
BA_ "SignalLongName" SG_ 390 RtPrkLmpCmd "Right Park Lamp command";
BA_ "SignalType" SG_ 390 RtPrkLmpCmd "ENM";
BA_ "GenSigSendType" SG_ 390 RtPrkLmpCmd 3;
BA_ "SignalLongName" SG_ 390 RtPrkLmpDimValue "Right Park Lamp dim value";
BA_ "SignalType" SG_ 390 RtPrkLmpDimValue "UNM";
BA_ "GenSigSendType" SG_ 390 RtPrkLmpDimValue 3;
BA_ "SignalLongName" SG_ 390 LftFrtTrnLmpCmd "Left Front Turn Lamp command";
BA_ "SignalType" SG_ 390 LftFrtTrnLmpCmd "ENM";
BA_ "GenSigSendType" SG_ 390 LftFrtTrnLmpCmd 3;
BA_ "SignalLongName" SG_ 390 RtFrtTrnLmpCmd "Right Front Turn Lamp command";
BA_ "SignalType" SG_ 390 RtFrtTrnLmpCmd "ENM";
BA_ "GenSigSendType" SG_ 390 RtFrtTrnLmpCmd 3;
BA_ "SignalLongName" SG_ 391 LftLowBmCmd "Left Low Beam command";
BA_ "SignalType" SG_ 391 LftLowBmCmd "ENM";
BA_ "GenSigSendType" SG_ 391 LftLowBmCmd 3;
BA_ "SignalLongName" SG_ 391 LftLowBmCmdARC "Left Low Beam command Alive Rolling Count";
BA_ "SignalType" SG_ 391 LftLowBmCmdARC "UNM";
BA_ "GenSigSendType" SG_ 391 LftLowBmCmdARC 3;
BA_ "SignalLongName" SG_ 391 LftLowBmCmdPV "Left Low Beam command Protection Value";
BA_ "SignalType" SG_ 391 LftLowBmCmdPV "UNM";
BA_ "GenSigSendType" SG_ 391 LftLowBmCmdPV 3;
BA_ "SignalLongName" SG_ 391 LftLowBmDimValue "Left Low Beam dim value";
BA_ "SignalType" SG_ 391 LftLowBmDimValue "UNM";
BA_ "GenSigSendType" SG_ 391 LftLowBmDimValue 3;
BA_ "SignalLongName" SG_ 391 RtLowBmCmd "Right Low Beam command";
BA_ "SignalType" SG_ 391 RtLowBmCmd "ENM";
BA_ "GenSigSendType" SG_ 391 RtLowBmCmd 3;
BA_ "SignalLongName" SG_ 391 RtLowBmCmdARC "Right Low Beam command Alive Rolling Count";
BA_ "SignalType" SG_ 391 RtLowBmCmdARC "UNM";
BA_ "GenSigSendType" SG_ 391 RtLowBmCmdARC 3;
BA_ "SignalLongName" SG_ 391 RtLowBmCmdPV "Right Low Beam command Protection Value";
BA_ "SignalType" SG_ 391 RtLowBmCmdPV "UNM";
BA_ "GenSigSendType" SG_ 391 RtLowBmCmdPV 3;
BA_ "SignalLongName" SG_ 391 RtLowBmDimValue "Right Low Beam dim value";
BA_ "SignalType" SG_ 391 RtLowBmDimValue "UNM";
BA_ "GenSigSendType" SG_ 391 RtLowBmDimValue 3;
BA_ "SignalLongName" SG_ 391 LftHiBmCmd "Left High Beam command";
BA_ "SignalType" SG_ 391 LftHiBmCmd "ENM";
BA_ "GenSigSendType" SG_ 391 LftHiBmCmd 3;
BA_ "SignalLongName" SG_ 391 LftHiBmCmdARC "Left High Beam command Alive Rolling Count";
BA_ "SignalType" SG_ 391 LftHiBmCmdARC "UNM";
BA_ "GenSigSendType" SG_ 391 LftHiBmCmdARC 3;
BA_ "SignalLongName" SG_ 391 LftHiBmCmdPV "Left High Beam command Protection Value";
BA_ "SignalType" SG_ 391 LftHiBmCmdPV "UNM";
BA_ "GenSigSendType" SG_ 391 LftHiBmCmdPV 3;
BA_ "SignalLongName" SG_ 391 LftHiBmDimValue "Left High Beam dim value";
BA_ "SignalType" SG_ 391 LftHiBmDimValue "UNM";
BA_ "GenSigSendType" SG_ 391 LftHiBmDimValue 3;
BA_ "SignalLongName" SG_ 391 RtHiBmCmd "Right High Beam command";
BA_ "SignalType" SG_ 391 RtHiBmCmd "ENM";
BA_ "GenSigSendType" SG_ 391 RtHiBmCmd 3;
BA_ "SignalLongName" SG_ 391 RtHiBmCmdARC "Right High Beam command Alive Rolling Count";
BA_ "SignalType" SG_ 391 RtHiBmCmdARC "UNM";
BA_ "GenSigSendType" SG_ 391 RtHiBmCmdARC 3;
BA_ "SignalLongName" SG_ 391 RtHiBmCmdPV "Right High Beam command Protection Value";
BA_ "SignalType" SG_ 391 RtHiBmCmdPV "UNM";
BA_ "GenSigSendType" SG_ 391 RtHiBmCmdPV 3;
BA_ "SignalLongName" SG_ 391 RtHiBmDimValue "Right High Beam dim value";
BA_ "SignalType" SG_ 391 RtHiBmDimValue "UNM";
BA_ "GenSigSendType" SG_ 391 RtHiBmDimValue 3;
BA_ "SignalLongName" SG_ 1536 LH_GRA1_CntrHrztlActPostn "Left Headlamp Glare Free Area 1 Actual Center Horizontal Position";
BA_ "SignalType" SG_ 1536 LH_GRA1_CntrHrztlActPostn "SNM";
BA_ "SignalLongName" SG_ 1536 LH_GRA1_CntrVrtclActPostn "Left Headlamp Glare Free Area 1 Actual Center Vertical Actual Position";
BA_ "SignalType" SG_ 1536 LH_GRA1_CntrVrtclActPostn "SNM";
BA_ "SignalLongName" SG_ 1536 LH_GRA1_HrztlHlfActWidt "Left Headlamp Glare Free Area 1 Actual Horizontal Half Width";
BA_ "SignalType" SG_ 1536 LH_GRA1_HrztlHlfActWidt "UNM";
BA_ "SignalLongName" SG_ 1536 LH_GRA1_VrtclHlfActWidt "Left Headlamp Glare Free Area 1 Actual Vertical Half Width";
BA_ "SignalType" SG_ 1536 LH_GRA1_VrtclHlfActWidt "UNM";
BA_ "SignalLongName" SG_ 1536 LH_GRA1_DimActVal "Left Headlamp Glare Free Actual Area 1 Dim Value";
BA_ "SignalType" SG_ 1536 LH_GRA1_DimActVal "UNM";
BA_ "SignalLongName" SG_ 1538 LH_GRA2_CntrHrztlActPostn "Left Headlamp Glare Free Area 2 Actual Center Horizontal Position";
BA_ "SignalType" SG_ 1538 LH_GRA2_CntrHrztlActPostn "SNM";
BA_ "SignalLongName" SG_ 1538 LH_GRA2_CntrVrtclActPostn "Left Headlamp Glare Free Area 2 Actual Center Vertical Actual Position";
BA_ "SignalType" SG_ 1538 LH_GRA2_CntrVrtclActPostn "SNM";
BA_ "SignalLongName" SG_ 1538 LH_GRA2_HrztlHlfActWidt "Left Headlamp Glare Free Area 2 Actual Horizontal Half Width";
BA_ "SignalType" SG_ 1538 LH_GRA2_HrztlHlfActWidt "UNM";
BA_ "SignalLongName" SG_ 1538 LH_GRA2_VrtclHlfActWidt "Left Headlamp Glare Free Area 2 Actual Vertical Half Width";
BA_ "SignalType" SG_ 1538 LH_GRA2_VrtclHlfActWidt "UNM";
BA_ "SignalLongName" SG_ 1538 LH_GRA2_DimActVal "Left Headlamp Glare Free Actual Area 2 Dim Value";
BA_ "SignalType" SG_ 1538 LH_GRA2_DimActVal "UNM";
BA_ "SignalLongName" SG_ 1540 LH_GRA3_CntrHrztlActPostn "Left Headlamp Glare Free Area 3 Actual Center Horizontal Position";
BA_ "SignalType" SG_ 1540 LH_GRA3_CntrHrztlActPostn "SNM";
BA_ "SignalLongName" SG_ 1540 LH_GRA3_CntrVrtclActPostn "Left Headlamp Glare Free Area 3 Actual Center Vertical Actual Position";
BA_ "SignalType" SG_ 1540 LH_GRA3_CntrVrtclActPostn "SNM";
BA_ "SignalLongName" SG_ 1540 LH_GRA3_HrztlHlfActWidt "Left Headlamp Glare Free Area 3 Actual Horizontal Half Width";
BA_ "SignalType" SG_ 1540 LH_GRA3_HrztlHlfActWidt "UNM";
BA_ "SignalLongName" SG_ 1540 LH_GRA3_VrtclHlfActWidt "Left Headlamp Glare Free Area 3 Actual Vertical Half Width";
BA_ "SignalType" SG_ 1540 LH_GRA3_VrtclHlfActWidt "UNM";
BA_ "SignalLongName" SG_ 1540 LH_GRA3_DimActVal "Left Headlamp Glare Free Actual Area 3 Dim Value";
BA_ "SignalType" SG_ 1540 LH_GRA3_DimActVal "UNM";
BA_ "SignalLongName" SG_ 1542 LH_GRA4_CntrHrztlActPostn "Left Headlamp Glare Free Area 4 Actual Center Horizontal Position";
BA_ "SignalType" SG_ 1542 LH_GRA4_CntrHrztlActPostn "SNM";
BA_ "SignalLongName" SG_ 1542 LH_GRA4_CntrVrtclActPostn "Left Headlamp Glare Free Area 4 Actual Center Vertical Actual Position";
BA_ "SignalType" SG_ 1542 LH_GRA4_CntrVrtclActPostn "SNM";
BA_ "SignalLongName" SG_ 1542 LH_GRA4_HrztlHlfActWidt "Left Headlamp Glare Free Area 4 Actual Horizontal Half Width";
BA_ "SignalType" SG_ 1542 LH_GRA4_HrztlHlfActWidt "UNM";
BA_ "SignalLongName" SG_ 1542 LH_GRA4_VrtclHlfActWidt "Left Headlamp Glare Free Area 4 Actual Vertical Half Width";
BA_ "SignalType" SG_ 1542 LH_GRA4_VrtclHlfActWidt "UNM";
BA_ "SignalLongName" SG_ 1542 LH_GRA4_DimActVal "Left Headlamp Glare Free Actual Area 4 Dim Value";
BA_ "SignalType" SG_ 1542 LH_GRA4_DimActVal "UNM";
BA_ "SignalLongName" SG_ 1544 LH_GRA5_CntrHrztlActPostn "Left Headlamp Glare Free Area 5 Actual Center Horizontal Position";
BA_ "SignalType" SG_ 1544 LH_GRA5_CntrHrztlActPostn "SNM";
BA_ "SignalLongName" SG_ 1544 LH_GRA5_CntrVrtclActPostn "Left Headlamp Glare Free Area 5 Actual Center Vertical Actual Position";
BA_ "SignalType" SG_ 1544 LH_GRA5_CntrVrtclActPostn "SNM";
BA_ "SignalLongName" SG_ 1544 LH_GRA5_HrztlHlfActWidt "Left Headlamp Glare Free Area 5 Actual Horizontal Half Width";
BA_ "SignalType" SG_ 1544 LH_GRA5_HrztlHlfActWidt "UNM";
BA_ "SignalLongName" SG_ 1544 LH_GRA5_VrtclHlfActWidt "Left Headlamp Glare Free Area 5 Actual Vertical Half Width";
BA_ "SignalType" SG_ 1544 LH_GRA5_VrtclHlfActWidt "UNM";
BA_ "SignalLongName" SG_ 1544 LH_GRA5_DimActVal "Left Headlamp Glare Free Actual Area 5 Dim Value";
BA_ "SignalType" SG_ 1544 LH_GRA5_DimActVal "UNM";
BA_ "SignalLongName" SG_ 1546 LH_GRA6_CntrHrztlActPostn "Left Headlamp Glare Free Area 6 Actual Center Horizontal Position";
BA_ "SignalType" SG_ 1546 LH_GRA6_CntrHrztlActPostn "SNM";
BA_ "SignalLongName" SG_ 1546 LH_GRA6_CntrVrtclActPostn "Left Headlamp Glare Free Area 6 Actual Center Vertical Actual Position";
BA_ "SignalType" SG_ 1546 LH_GRA6_CntrVrtclActPostn "SNM";
BA_ "SignalLongName" SG_ 1546 LH_GRA6_HrztlHlfActWidt "Left Headlamp Glare Free Area 6 Actual Horizontal Half Width";
BA_ "SignalType" SG_ 1546 LH_GRA6_HrztlHlfActWidt "UNM";
BA_ "SignalLongName" SG_ 1546 LH_GRA6_VrtclHlfActWidt "Left Headlamp Glare Free Area 6 Actual Vertical Half Width";
BA_ "SignalType" SG_ 1546 LH_GRA6_VrtclHlfActWidt "UNM";
BA_ "SignalLongName" SG_ 1546 LH_GRA6_DimActVal "Left Headlamp Glare Free Actual Area 6 Dim Value";
BA_ "SignalType" SG_ 1546 LH_GRA6_DimActVal "UNM";
BA_ "SignalLongName" SG_ 1584 LH_GRA7_CntrHrztlActPostn "Left Headlamp Glare Free Area 7 Actual Center Horizontal Position";
BA_ "SignalType" SG_ 1584 LH_GRA7_CntrHrztlActPostn "SNM";
BA_ "SignalLongName" SG_ 1584 LH_GRA7_CntrVrtclActPostn "Left Headlamp Glare Free Area 7 Actual Center Vertical Actual Position";
BA_ "SignalType" SG_ 1584 LH_GRA7_CntrVrtclActPostn "SNM";
BA_ "SignalLongName" SG_ 1584 LH_GRA7_HrztlHlfActWidt "Left Headlamp Glare Free Area 7 Actual Horizontal Half Width";
BA_ "SignalType" SG_ 1584 LH_GRA7_HrztlHlfActWidt "UNM";
BA_ "SignalLongName" SG_ 1584 LH_GRA7_VrtclHlfActWidt "Left Headlamp Glare Free Area 7 Actual Vertical Half Width";
BA_ "SignalType" SG_ 1584 LH_GRA7_VrtclHlfActWidt "UNM";
BA_ "SignalLongName" SG_ 1584 LH_GRA7_DimActVal "Left Headlamp Glare Free Actual Area 7 Dim Value";
BA_ "SignalType" SG_ 1584 LH_GRA7_DimActVal "UNM";
BA_ "SignalLongName" SG_ 1586 LH_GRA8_CntrHrztlActPostn "Left Headlamp Glare Free Area 8 Actual Center Horizontal Position";
BA_ "SignalType" SG_ 1586 LH_GRA8_CntrHrztlActPostn "SNM";
BA_ "SignalLongName" SG_ 1586 LH_GRA8_CntrVrtclActPostn "Left Headlamp Glare Free Area 8 Actual Center Vertical Actual Position";
BA_ "SignalType" SG_ 1586 LH_GRA8_CntrVrtclActPostn "SNM";
BA_ "SignalLongName" SG_ 1586 LH_GRA8_HrztlHlfActWidt "Left Headlamp Glare Free Area 8 Actual Horizontal Half Width";
BA_ "SignalType" SG_ 1586 LH_GRA8_HrztlHlfActWidt "UNM";
BA_ "SignalLongName" SG_ 1586 LH_GRA8_VrtclHlfActWidt "Left Headlamp Glare Free Area 8 Actual Vertical Half Width";
BA_ "SignalType" SG_ 1586 LH_GRA8_VrtclHlfActWidt "UNM";
BA_ "SignalLongName" SG_ 1586 LH_GRA8_DimActVal "Left Headlamp Glare Free Actual Area 8 Dim Value";
BA_ "SignalType" SG_ 1586 LH_GRA8_DimActVal "UNM";
BA_ "SignalLongName" SG_ 1537 RH_GRA1_CntrHrztlActPostn "Right Headlamp Glare Free Area 1 Actual Center Horizontal Position";
BA_ "SignalType" SG_ 1537 RH_GRA1_CntrHrztlActPostn "SNM";
BA_ "SignalLongName" SG_ 1537 RH_GRA1_CntrVrtclActPostn "Right Headlamp Glare Free Area 1 Actual Center Vertical Actual Position";
BA_ "SignalType" SG_ 1537 RH_GRA1_CntrVrtclActPostn "SNM";
BA_ "SignalLongName" SG_ 1537 RH_GRA1_HrztlHlfActWidt "Right Headlamp Glare Free Area 1 Actual Horizontal Half Width";
BA_ "SignalType" SG_ 1537 RH_GRA1_HrztlHlfActWidt "UNM";
BA_ "SignalLongName" SG_ 1537 RH_GRA1_VrtclHlfActWidt "Right Headlamp Glare Free Area 1 Actual Vertical Half Width";
BA_ "SignalType" SG_ 1537 RH_GRA1_VrtclHlfActWidt "UNM";
BA_ "SignalLongName" SG_ 1537 RH_GRA1_DimActVal "Right Headlamp Glare Free Actual Area 1 Dim Value";
BA_ "SignalType" SG_ 1537 RH_GRA1_DimActVal "UNM";
BA_ "SignalLongName" SG_ 1539 RH_GRA2_CntrHrztlActPostn "Right Headlamp Glare Free Area 2 Actual Center Horizontal Position";
BA_ "SignalType" SG_ 1539 RH_GRA2_CntrHrztlActPostn "SNM";
BA_ "SignalLongName" SG_ 1539 RH_GRA2_CntrVrtclActPostn "Right Headlamp Glare Free Area 2 Actual Center Vertical Actual Position";
BA_ "SignalType" SG_ 1539 RH_GRA2_CntrVrtclActPostn "SNM";
BA_ "SignalLongName" SG_ 1539 RH_GRA2_HrztlHlfActWidt "Right Headlamp Glare Free Area 2 Actual Horizontal Half Width";
BA_ "SignalType" SG_ 1539 RH_GRA2_HrztlHlfActWidt "UNM";
BA_ "SignalLongName" SG_ 1539 RH_GRA2_VrtclHlfActWidt "Right Headlamp Glare Free Area 2 Actual Vertical Half Width";
BA_ "SignalType" SG_ 1539 RH_GRA2_VrtclHlfActWidt "UNM";
BA_ "SignalLongName" SG_ 1539 RH_GRA2_DimActVal "Right Headlamp Glare Free Actual Area 2 Dim Value";
BA_ "SignalType" SG_ 1539 RH_GRA2_DimActVal "UNM";
BA_ "SignalLongName" SG_ 1541 RH_GRA3_CntrHrztlActPostn "Right Headlamp Glare Free Area 3 Actual Center Horizontal Position";
BA_ "SignalType" SG_ 1541 RH_GRA3_CntrHrztlActPostn "SNM";
BA_ "SignalLongName" SG_ 1541 RH_GRA3_CntrVrtclActPostn "Right Headlamp Glare Free Area 3 Actual Center Vertical Actual Position";
BA_ "SignalType" SG_ 1541 RH_GRA3_CntrVrtclActPostn "SNM";
BA_ "SignalLongName" SG_ 1541 RH_GRA3_HrztlHlfActWidt "Right Headlamp Glare Free Area 3 Actual Horizontal Half Width";
BA_ "SignalType" SG_ 1541 RH_GRA3_HrztlHlfActWidt "UNM";
BA_ "SignalLongName" SG_ 1541 RH_GRA3_VrtclHlfActWidt "Right Headlamp Glare Free Area 3 Actual Vertical Half Width";
BA_ "SignalType" SG_ 1541 RH_GRA3_VrtclHlfActWidt "UNM";
BA_ "SignalLongName" SG_ 1541 RH_GRA3_DimActVal "Right Headlamp Glare Free Actual Area 3 Dim Value";
BA_ "SignalType" SG_ 1541 RH_GRA3_DimActVal "UNM";
BA_ "SignalLongName" SG_ 1543 RH_GRA4_CntrHrztlActPostn "Right Headlamp Glare Free Area 4 Actual Center Horizontal Position";
BA_ "SignalType" SG_ 1543 RH_GRA4_CntrHrztlActPostn "SNM";
BA_ "SignalLongName" SG_ 1543 RH_GRA4_CntrVrtclActPostn "Right Headlamp Glare Free Area 4 Actual Center Vertical Actual Position";
BA_ "SignalType" SG_ 1543 RH_GRA4_CntrVrtclActPostn "SNM";
BA_ "SignalLongName" SG_ 1543 RH_GRA4_HrztlHlfActWidt "Right Headlamp Glare Free Area 4 Actual Horizontal Half Width";
BA_ "SignalType" SG_ 1543 RH_GRA4_HrztlHlfActWidt "UNM";
BA_ "SignalLongName" SG_ 1543 RH_GRA4_VrtclHlfActWidt "Right Headlamp Glare Free Area 4 Actual Vertical Half Width";
BA_ "SignalType" SG_ 1543 RH_GRA4_VrtclHlfActWidt "UNM";
BA_ "SignalLongName" SG_ 1543 RH_GRA4_DimActVal "Right Headlamp Glare Free Actual Area 4 Dim Value";
BA_ "SignalType" SG_ 1543 RH_GRA4_DimActVal "UNM";
BA_ "SignalLongName" SG_ 1545 RH_GRA5_CntrHrztlActPostn "Right Headlamp Glare Free Area 5 Actual Center Horizontal Position";
BA_ "SignalType" SG_ 1545 RH_GRA5_CntrHrztlActPostn "SNM";
BA_ "SignalLongName" SG_ 1545 RH_GRA5_CntrVrtclActPostn "Right Headlamp Glare Free Area 5 Actual Center Vertical Actual Position";
BA_ "SignalType" SG_ 1545 RH_GRA5_CntrVrtclActPostn "SNM";
BA_ "SignalLongName" SG_ 1545 RH_GRA5_HrztlHlfActWidt "Right Headlamp Glare Free Area 5 Actual Horizontal Half Width";
BA_ "SignalType" SG_ 1545 RH_GRA5_HrztlHlfActWidt "UNM";
BA_ "SignalLongName" SG_ 1545 RH_GRA5_VrtclHlfActWidt "Right Headlamp Glare Free Area 5 Actual Vertical Half Width";
BA_ "SignalType" SG_ 1545 RH_GRA5_VrtclHlfActWidt "UNM";
BA_ "SignalLongName" SG_ 1545 RH_GRA5_DimActVal "Right Headlamp Glare Free Actual Area 5 Dim Value";
BA_ "SignalType" SG_ 1545 RH_GRA5_DimActVal "UNM";
BA_ "SignalLongName" SG_ 1547 RH_GRA6_CntrHrztlActPostn "Right Headlamp Glare Free Area 6 Actual Center Horizontal Position";
BA_ "SignalType" SG_ 1547 RH_GRA6_CntrHrztlActPostn "SNM";
BA_ "SignalLongName" SG_ 1547 RH_GRA6_CntrVrtclActPostn "Right Headlamp Glare Free Area 6 Actual Center Vertical Actual Position";
BA_ "SignalType" SG_ 1547 RH_GRA6_CntrVrtclActPostn "SNM";
BA_ "SignalLongName" SG_ 1547 RH_GRA6_HrztlHlfActWidt "Right Headlamp Glare Free Area 6 Actual Horizontal Half Width";
BA_ "SignalType" SG_ 1547 RH_GRA6_HrztlHlfActWidt "UNM";
BA_ "SignalLongName" SG_ 1547 RH_GRA6_VrtclHlfActWidt "Right Headlamp Glare Free Area 6 Actual Vertical Half Width";
BA_ "SignalType" SG_ 1547 RH_GRA6_VrtclHlfActWidt "UNM";
BA_ "SignalLongName" SG_ 1547 RH_GRA6_DimActVal "Right Headlamp Glare Free Actual Area 6 Dim Value";
BA_ "SignalType" SG_ 1547 RH_GRA6_DimActVal "UNM";
BA_ "SignalLongName" SG_ 1585 RH_GRA7_CntrHrztlActPostn "Right Headlamp Glare Free Area 7 Actual Center Horizontal Position";
BA_ "SignalType" SG_ 1585 RH_GRA7_CntrHrztlActPostn "SNM";
BA_ "SignalLongName" SG_ 1585 RH_GRA7_CntrVrtclActPostn "Right Headlamp Glare Free Area 7 Actual Center Vertical Actual Position";
BA_ "SignalType" SG_ 1585 RH_GRA7_CntrVrtclActPostn "SNM";
BA_ "SignalLongName" SG_ 1585 RH_GRA7_HrztlHlfActWidt "Right Headlamp Glare Free Area 7 Actual Horizontal Half Width";
BA_ "SignalType" SG_ 1585 RH_GRA7_HrztlHlfActWidt "UNM";
BA_ "SignalLongName" SG_ 1585 RH_GRA7_VrtclHlfActWidt "Right Headlamp Glare Free Area 7 Actual Vertical Half Width";
BA_ "SignalType" SG_ 1585 RH_GRA7_VrtclHlfActWidt "UNM";
BA_ "SignalLongName" SG_ 1585 RH_GRA7_DimActVal "Right Headlamp Glare Free Actual Area 7 Dim Value";
BA_ "SignalType" SG_ 1585 RH_GRA7_DimActVal "UNM";
BA_ "SignalLongName" SG_ 1587 RH_GRA8_CntrHrztlActPostn "Right Headlamp Glare Free Area 8 Actual Center Horizontal Position";
BA_ "SignalType" SG_ 1587 RH_GRA8_CntrHrztlActPostn "SNM";
BA_ "SignalLongName" SG_ 1587 RH_GRA8_CntrVrtclActPostn "Right Headlamp Glare Free Area 8 Actual Center Vertical Actual Position";
BA_ "SignalType" SG_ 1587 RH_GRA8_CntrVrtclActPostn "SNM";
BA_ "SignalLongName" SG_ 1587 RH_GRA8_HrztlHlfActWidt "Right Headlamp Glare Free Area 8 Actual Horizontal Half Width";
BA_ "SignalType" SG_ 1587 RH_GRA8_HrztlHlfActWidt "UNM";
BA_ "SignalLongName" SG_ 1587 RH_GRA8_VrtclHlfActWidt "Right Headlamp Glare Free Area 8 Actual Vertical Half Width";
BA_ "SignalType" SG_ 1587 RH_GRA8_VrtclHlfActWidt "UNM";
BA_ "SignalLongName" SG_ 1587 RH_GRA8_DimActVal "Right Headlamp Glare Free Actual Area 8 Dim Value";
BA_ "SignalType" SG_ 1587 RH_GRA8_DimActVal "UNM";
BA_REL_ "GenSigTimeoutMsg" BU_SG_REL_ AHL_ELCB SG_ 1026 SystmStat_Chcksm_HLS_LH 1026;
BA_REL_ "GenSigSuprvResp" BU_SG_REL_ AHL_ELCB SG_ 1026 SystmStat_Chcksm_HLS_LH 1;
BA_REL_ "GenSigTimeoutTime" BU_SG_REL_ AHL_ELCB SG_ 1026 SystmStat_Chcksm_HLS_LH 250;
BA_REL_ "GenSigTimeoutMsg" BU_SG_REL_ AHL_ELCB SG_ 1026 SystmStat_MssgCntr_HLS_LH 1026;
BA_REL_ "GenSigSuprvResp" BU_SG_REL_ AHL_ELCB SG_ 1026 SystmStat_MssgCntr_HLS_LH 1;
BA_REL_ "GenSigTimeoutTime" BU_SG_REL_ AHL_ELCB SG_ 1026 SystmStat_MssgCntr_HLS_LH 250;
BA_REL_ "GenSigTimeoutMsg" BU_SG_REL_ AHL_ELCB SG_ 1026 SystmStat_ShrtCirctFail_HLS_LH 1026;
BA_REL_ "GenSigSuprvResp" BU_SG_REL_ AHL_ELCB SG_ 1026 SystmStat_ShrtCirctFail_HLS_LH 1;
BA_REL_ "GenSigTimeoutTime" BU_SG_REL_ AHL_ELCB SG_ 1026 SystmStat_ShrtCirctFail_HLS_LH 250;
BA_REL_ "GenSigTimeoutMsg" BU_SG_REL_ AHL_ELCB SG_ 1026 SystmStat_OpnLoadFail_HLS_LH 1026;
BA_REL_ "GenSigSuprvResp" BU_SG_REL_ AHL_ELCB SG_ 1026 SystmStat_OpnLoadFail_HLS_LH 1;
BA_REL_ "GenSigTimeoutTime" BU_SG_REL_ AHL_ELCB SG_ 1026 SystmStat_OpnLoadFail_HLS_LH 250;
BA_REL_ "GenSigTimeoutMsg" BU_SG_REL_ AHL_ELCB SG_ 1026 SystmStat_IntrnlSysFail_HLS_LH 1026;
BA_REL_ "GenSigSuprvResp" BU_SG_REL_ AHL_ELCB SG_ 1026 SystmStat_IntrnlSysFail_HLS_LH 1;
BA_REL_ "GenSigTimeoutTime" BU_SG_REL_ AHL_ELCB SG_ 1026 SystmStat_IntrnlSysFail_HLS_LH 250;
BA_REL_ "GenSigTimeoutMsg" BU_SG_REL_ AHL_ELCB SG_ 1026 SystmStat_OvrVltgFail_HLS_LH 1026;
BA_REL_ "GenSigSuprvResp" BU_SG_REL_ AHL_ELCB SG_ 1026 SystmStat_OvrVltgFail_HLS_LH 1;
BA_REL_ "GenSigTimeoutTime" BU_SG_REL_ AHL_ELCB SG_ 1026 SystmStat_OvrVltgFail_HLS_LH 250;
BA_REL_ "GenSigTimeoutMsg" BU_SG_REL_ AHL_ELCB SG_ 1026 SystmStat_UndVltgFail_HLS_LH 1026;
BA_REL_ "GenSigSuprvResp" BU_SG_REL_ AHL_ELCB SG_ 1026 SystmStat_UndVltgFail_HLS_LH 1;
BA_REL_ "GenSigTimeoutTime" BU_SG_REL_ AHL_ELCB SG_ 1026 SystmStat_UndVltgFail_HLS_LH 250;
BA_REL_ "GenSigTimeoutMsg" BU_SG_REL_ AHL_ELCB SG_ 1026 SystmStat_ActutorFail_HLS_LH 1026;
BA_REL_ "GenSigSuprvResp" BU_SG_REL_ AHL_ELCB SG_ 1026 SystmStat_ActutorFail_HLS_LH 1;
BA_REL_ "GenSigTimeoutTime" BU_SG_REL_ AHL_ELCB SG_ 1026 SystmStat_ActutorFail_HLS_LH 250;
BA_REL_ "GenSigTimeoutMsg" BU_SG_REL_ AHL_ELCB SG_ 1026 SystmStat_IntnlTempFail_HLS_LH 1026;
BA_REL_ "GenSigSuprvResp" BU_SG_REL_ AHL_ELCB SG_ 1026 SystmStat_IntnlTempFail_HLS_LH 1;
BA_REL_ "GenSigTimeoutTime" BU_SG_REL_ AHL_ELCB SG_ 1026 SystmStat_IntnlTempFail_HLS_LH 250;
BA_REL_ "GenSigTimeoutMsg" BU_SG_REL_ AHL_ELCB SG_ 1026 SystmStat_ExtTempFail_HLS_LH 1026;
BA_REL_ "GenSigSuprvResp" BU_SG_REL_ AHL_ELCB SG_ 1026 SystmStat_ExtTempFail_HLS_LH 1;
BA_REL_ "GenSigTimeoutTime" BU_SG_REL_ AHL_ELCB SG_ 1026 SystmStat_ExtTempFail_HLS_LH 250;
BA_REL_ "GenSigTimeoutMsg" BU_SG_REL_ AHL_ELCB SG_ 1026 SystmStat_CurntCdngFail_HLS_LH 1026;
BA_REL_ "GenSigSuprvResp" BU_SG_REL_ AHL_ELCB SG_ 1026 SystmStat_CurntCdngFail_HLS_LH 1;
BA_REL_ "GenSigTimeoutTime" BU_SG_REL_ AHL_ELCB SG_ 1026 SystmStat_CurntCdngFail_HLS_LH 250;
BA_REL_ "GenSigTimeoutMsg" BU_SG_REL_ AHL_ELCB SG_ 1026 SystmStat_FanFail_HLS_LH 1026;
BA_REL_ "GenSigSuprvResp" BU_SG_REL_ AHL_ELCB SG_ 1026 SystmStat_FanFail_HLS_LH 1;
BA_REL_ "GenSigTimeoutTime" BU_SG_REL_ AHL_ELCB SG_ 1026 SystmStat_FanFail_HLS_LH 250;
BA_REL_ "GenSigTimeoutMsg" BU_SG_REL_ AHL_ELCB SG_ 1026 SystmStat_MstrMsgFail_HLS_LH 1026;
BA_REL_ "GenSigSuprvResp" BU_SG_REL_ AHL_ELCB SG_ 1026 SystmStat_MstrMsgFail_HLS_LH 1;
BA_REL_ "GenSigTimeoutTime" BU_SG_REL_ AHL_ELCB SG_ 1026 SystmStat_MstrMsgFail_HLS_LH 250;
BA_REL_ "GenSigTimeoutMsg" BU_SG_REL_ AHL_ELCB SG_ 1026 SystmStat_OverTempFail_HLS_LH 1026;
BA_REL_ "GenSigSuprvResp" BU_SG_REL_ AHL_ELCB SG_ 1026 SystmStat_OverTempFail_HLS_LH 1;
BA_REL_ "GenSigTimeoutTime" BU_SG_REL_ AHL_ELCB SG_ 1026 SystmStat_OverTempFail_HLS_LH 250;
BA_REL_ "GenSigTimeoutMsg" BU_SG_REL_ AHL_ELCB SG_ 1026 SystmStat_IncCompFail_HLS_LH 1026;
BA_REL_ "GenSigSuprvResp" BU_SG_REL_ AHL_ELCB SG_ 1026 SystmStat_IncCompFail_HLS_LH 1;
BA_REL_ "GenSigTimeoutTime" BU_SG_REL_ AHL_ELCB SG_ 1026 SystmStat_IncCompFail_HLS_LH 250;
BA_REL_ "GenSigTimeoutMsg" BU_SG_REL_ AHL_ELCB SG_ 1026 SystmStat_CSorMCFail_HLS_LH 1026;
BA_REL_ "GenSigSuprvResp" BU_SG_REL_ AHL_ELCB SG_ 1026 SystmStat_CSorMCFail_HLS_LH 1;
BA_REL_ "GenSigTimeoutTime" BU_SG_REL_ AHL_ELCB SG_ 1026 SystmStat_CSorMCFail_HLS_LH 250;
BA_REL_ "GenSigTimeoutMsg" BU_SG_REL_ AHL_ELCB SG_ 1026 SystmStat_R_L_DtctnFail_HLS_LH 1026;
BA_REL_ "GenSigSuprvResp" BU_SG_REL_ AHL_ELCB SG_ 1026 SystmStat_R_L_DtctnFail_HLS_LH 1;
BA_REL_ "GenSigTimeoutTime" BU_SG_REL_ AHL_ELCB SG_ 1026 SystmStat_R_L_DtctnFail_HLS_LH 250;
BA_REL_ "GenSigTimeoutMsg" BU_SG_REL_ AHL_ELCB SG_ 1026 SystmStat_FnctnStat_HLS_LH 1026;
BA_REL_ "GenSigSuprvResp" BU_SG_REL_ AHL_ELCB SG_ 1026 SystmStat_FnctnStat_HLS_LH 1;
BA_REL_ "GenSigTimeoutTime" BU_SG_REL_ AHL_ELCB SG_ 1026 SystmStat_FnctnStat_HLS_LH 250;
BA_REL_ "GenSigTimeoutMsg" BU_SG_REL_ AHL_ELCB SG_ 1026 SystmStat_SpplyVltgVal_HLS_LH 1026;
BA_REL_ "GenSigSuprvResp" BU_SG_REL_ AHL_ELCB SG_ 1026 SystmStat_SpplyVltgVal_HLS_LH 1;
BA_REL_ "GenSigTimeoutTime" BU_SG_REL_ AHL_ELCB SG_ 1026 SystmStat_SpplyVltgVal_HLS_LH 250;
BA_REL_ "GenSigTimeoutMsg" BU_SG_REL_ AHL_ELCB SG_ 1026 SystmStat_ExtTempVal_HLS_LH 1026;
BA_REL_ "GenSigSuprvResp" BU_SG_REL_ AHL_ELCB SG_ 1026 SystmStat_ExtTempVal_HLS_LH 1;
BA_REL_ "GenSigTimeoutTime" BU_SG_REL_ AHL_ELCB SG_ 1026 SystmStat_ExtTempVal_HLS_LH 250;
BA_REL_ "GenSigTimeoutMsg" BU_SG_REL_ AHL_ELCB SG_ 1026 SystmStat_IntTempVal_HLS_LH 1026;
BA_REL_ "GenSigSuprvResp" BU_SG_REL_ AHL_ELCB SG_ 1026 SystmStat_IntTempVal_HLS_LH 1;
BA_REL_ "GenSigTimeoutTime" BU_SG_REL_ AHL_ELCB SG_ 1026 SystmStat_IntTempVal_HLS_LH 250;
BA_REL_ "GenSigTimeoutMsg" BU_SG_REL_ AHL_ELCB SG_ 1026 SystmStat_RefrncRunStat_HLS_LH 1026;
BA_REL_ "GenSigSuprvResp" BU_SG_REL_ AHL_ELCB SG_ 1026 SystmStat_RefrncRunStat_HLS_LH 1;
BA_REL_ "GenSigTimeoutTime" BU_SG_REL_ AHL_ELCB SG_ 1026 SystmStat_RefrncRunStat_HLS_LH 250;
BA_REL_ "GenSigTimeoutMsg" BU_SG_REL_ AHL_ELCB SG_ 1026 SystmStat_DertngStat_HLS_LH 1026;
BA_REL_ "GenSigSuprvResp" BU_SG_REL_ AHL_ELCB SG_ 1026 SystmStat_DertngStat_HLS_LH 1;
BA_REL_ "GenSigTimeoutTime" BU_SG_REL_ AHL_ELCB SG_ 1026 SystmStat_DertngStat_HLS_LH 250;
BA_REL_ "GenSigTimeoutMsg" BU_SG_REL_ AHL_ELCB SG_ 1026 SystmStat_SysCalibStat_HLS_LH 1026;
BA_REL_ "GenSigSuprvResp" BU_SG_REL_ AHL_ELCB SG_ 1026 SystmStat_SysCalibStat_HLS_LH 1;
BA_REL_ "GenSigTimeoutTime" BU_SG_REL_ AHL_ELCB SG_ 1026 SystmStat_SysCalibStat_HLS_LH 250;
BA_REL_ "GenSigTimeoutMsg" BU_SG_REL_ AHL_ELCB SG_ 1026 SystmStat_VINStat_HLS_LH 1026;
BA_REL_ "GenSigSuprvResp" BU_SG_REL_ AHL_ELCB SG_ 1026 SystmStat_VINStat_HLS_LH 1;
BA_REL_ "GenSigTimeoutTime" BU_SG_REL_ AHL_ELCB SG_ 1026 SystmStat_VINStat_HLS_LH 250;
BA_REL_ "GenSigTimeoutMsg" BU_SG_REL_ AHL_ELCB SG_ 1027 SystmStat_Chcksm_HLS_RH 1027;
BA_REL_ "GenSigSuprvResp" BU_SG_REL_ AHL_ELCB SG_ 1027 SystmStat_Chcksm_HLS_RH 1;
BA_REL_ "GenSigTimeoutTime" BU_SG_REL_ AHL_ELCB SG_ 1027 SystmStat_Chcksm_HLS_RH 250;
BA_REL_ "GenSigTimeoutMsg" BU_SG_REL_ AHL_ELCB SG_ 1027 SystmStat_MssgCntr_HLS_RH 1027;
BA_REL_ "GenSigSuprvResp" BU_SG_REL_ AHL_ELCB SG_ 1027 SystmStat_MssgCntr_HLS_RH 1;
BA_REL_ "GenSigTimeoutTime" BU_SG_REL_ AHL_ELCB SG_ 1027 SystmStat_MssgCntr_HLS_RH 250;
BA_REL_ "GenSigTimeoutMsg" BU_SG_REL_ AHL_ELCB SG_ 1027 SystmStat_ShrtCirctFail_HLS_RH 1027;
BA_REL_ "GenSigSuprvResp" BU_SG_REL_ AHL_ELCB SG_ 1027 SystmStat_ShrtCirctFail_HLS_RH 1;
BA_REL_ "GenSigTimeoutTime" BU_SG_REL_ AHL_ELCB SG_ 1027 SystmStat_ShrtCirctFail_HLS_RH 250;
BA_REL_ "GenSigTimeoutMsg" BU_SG_REL_ AHL_ELCB SG_ 1027 SystmStat_OpnLoadFail_HLS_RH 1027;
BA_REL_ "GenSigSuprvResp" BU_SG_REL_ AHL_ELCB SG_ 1027 SystmStat_OpnLoadFail_HLS_RH 1;
BA_REL_ "GenSigTimeoutTime" BU_SG_REL_ AHL_ELCB SG_ 1027 SystmStat_OpnLoadFail_HLS_RH 250;
BA_REL_ "GenSigTimeoutMsg" BU_SG_REL_ AHL_ELCB SG_ 1027 SystmStat_IntrnlSysFail_HLS_RH 1027;
BA_REL_ "GenSigSuprvResp" BU_SG_REL_ AHL_ELCB SG_ 1027 SystmStat_IntrnlSysFail_HLS_RH 1;
BA_REL_ "GenSigTimeoutTime" BU_SG_REL_ AHL_ELCB SG_ 1027 SystmStat_IntrnlSysFail_HLS_RH 250;
BA_REL_ "GenSigTimeoutMsg" BU_SG_REL_ AHL_ELCB SG_ 1027 SystmStat_OvrVltgFail_HLS_RH 1027;
BA_REL_ "GenSigSuprvResp" BU_SG_REL_ AHL_ELCB SG_ 1027 SystmStat_OvrVltgFail_HLS_RH 1;
BA_REL_ "GenSigTimeoutTime" BU_SG_REL_ AHL_ELCB SG_ 1027 SystmStat_OvrVltgFail_HLS_RH 250;
BA_REL_ "GenSigTimeoutMsg" BU_SG_REL_ AHL_ELCB SG_ 1027 SystmStat_UndVltgFail_HLS_RH 1027;
BA_REL_ "GenSigSuprvResp" BU_SG_REL_ AHL_ELCB SG_ 1027 SystmStat_UndVltgFail_HLS_RH 1;
BA_REL_ "GenSigTimeoutTime" BU_SG_REL_ AHL_ELCB SG_ 1027 SystmStat_UndVltgFail_HLS_RH 250;
BA_REL_ "GenSigTimeoutMsg" BU_SG_REL_ AHL_ELCB SG_ 1027 SystmStat_ActutorFail_HLS_RH 1027;
BA_REL_ "GenSigSuprvResp" BU_SG_REL_ AHL_ELCB SG_ 1027 SystmStat_ActutorFail_HLS_RH 1;
BA_REL_ "GenSigTimeoutTime" BU_SG_REL_ AHL_ELCB SG_ 1027 SystmStat_ActutorFail_HLS_RH 250;
BA_REL_ "GenSigTimeoutMsg" BU_SG_REL_ AHL_ELCB SG_ 1027 SystmStat_IntnlTempFail_HLS_RH 1027;
BA_REL_ "GenSigSuprvResp" BU_SG_REL_ AHL_ELCB SG_ 1027 SystmStat_IntnlTempFail_HLS_RH 1;
BA_REL_ "GenSigTimeoutTime" BU_SG_REL_ AHL_ELCB SG_ 1027 SystmStat_IntnlTempFail_HLS_RH 250;
BA_REL_ "GenSigTimeoutMsg" BU_SG_REL_ AHL_ELCB SG_ 1027 SystmStat_ExtTempFail_HLS_RH 1027;
BA_REL_ "GenSigSuprvResp" BU_SG_REL_ AHL_ELCB SG_ 1027 SystmStat_ExtTempFail_HLS_RH 1;
BA_REL_ "GenSigTimeoutTime" BU_SG_REL_ AHL_ELCB SG_ 1027 SystmStat_ExtTempFail_HLS_RH 250;
BA_REL_ "GenSigTimeoutMsg" BU_SG_REL_ AHL_ELCB SG_ 1027 SystmStat_CurntCdngFail_HLS_RH 1027;
BA_REL_ "GenSigSuprvResp" BU_SG_REL_ AHL_ELCB SG_ 1027 SystmStat_CurntCdngFail_HLS_RH 1;
BA_REL_ "GenSigTimeoutTime" BU_SG_REL_ AHL_ELCB SG_ 1027 SystmStat_CurntCdngFail_HLS_RH 250;
BA_REL_ "GenSigTimeoutMsg" BU_SG_REL_ AHL_ELCB SG_ 1027 SystmStat_FanFail_HLS_RH 1027;
BA_REL_ "GenSigSuprvResp" BU_SG_REL_ AHL_ELCB SG_ 1027 SystmStat_FanFail_HLS_RH 1;
BA_REL_ "GenSigTimeoutTime" BU_SG_REL_ AHL_ELCB SG_ 1027 SystmStat_FanFail_HLS_RH 250;
BA_REL_ "GenSigTimeoutMsg" BU_SG_REL_ AHL_ELCB SG_ 1027 SystmStat_MstrMsgFail_HLS_RH 1027;
BA_REL_ "GenSigSuprvResp" BU_SG_REL_ AHL_ELCB SG_ 1027 SystmStat_MstrMsgFail_HLS_RH 1;
BA_REL_ "GenSigTimeoutTime" BU_SG_REL_ AHL_ELCB SG_ 1027 SystmStat_MstrMsgFail_HLS_RH 250;
BA_REL_ "GenSigTimeoutMsg" BU_SG_REL_ AHL_ELCB SG_ 1027 SystmStat_OverTempFail_HLS_RH 1027;
BA_REL_ "GenSigSuprvResp" BU_SG_REL_ AHL_ELCB SG_ 1027 SystmStat_OverTempFail_HLS_RH 1;
BA_REL_ "GenSigTimeoutTime" BU_SG_REL_ AHL_ELCB SG_ 1027 SystmStat_OverTempFail_HLS_RH 250;
BA_REL_ "GenSigTimeoutMsg" BU_SG_REL_ AHL_ELCB SG_ 1027 SystmStat_IncCompFail_HLS_RH 1027;
BA_REL_ "GenSigSuprvResp" BU_SG_REL_ AHL_ELCB SG_ 1027 SystmStat_IncCompFail_HLS_RH 1;
BA_REL_ "GenSigTimeoutTime" BU_SG_REL_ AHL_ELCB SG_ 1027 SystmStat_IncCompFail_HLS_RH 250;
BA_REL_ "GenSigTimeoutMsg" BU_SG_REL_ AHL_ELCB SG_ 1027 SystmStat_CSorMCFail_HLS_RH 1027;
BA_REL_ "GenSigSuprvResp" BU_SG_REL_ AHL_ELCB SG_ 1027 SystmStat_CSorMCFail_HLS_RH 1;
BA_REL_ "GenSigTimeoutTime" BU_SG_REL_ AHL_ELCB SG_ 1027 SystmStat_CSorMCFail_HLS_RH 250;
BA_REL_ "GenSigTimeoutMsg" BU_SG_REL_ AHL_ELCB SG_ 1027 SystmStat_R_L_DtctnFail_HLS_RH 1027;
BA_REL_ "GenSigSuprvResp" BU_SG_REL_ AHL_ELCB SG_ 1027 SystmStat_R_L_DtctnFail_HLS_RH 1;
BA_REL_ "GenSigTimeoutTime" BU_SG_REL_ AHL_ELCB SG_ 1027 SystmStat_R_L_DtctnFail_HLS_RH 250;
BA_REL_ "GenSigTimeoutMsg" BU_SG_REL_ AHL_ELCB SG_ 1027 SystmStat_FnctnStat_HLS_RH 1027;
BA_REL_ "GenSigSuprvResp" BU_SG_REL_ AHL_ELCB SG_ 1027 SystmStat_FnctnStat_HLS_RH 1;
BA_REL_ "GenSigTimeoutTime" BU_SG_REL_ AHL_ELCB SG_ 1027 SystmStat_FnctnStat_HLS_RH 250;
BA_REL_ "GenSigTimeoutMsg" BU_SG_REL_ AHL_ELCB SG_ 1027 SystmStat_SpplyVltgVal_HLS_RH 1027;
BA_REL_ "GenSigSuprvResp" BU_SG_REL_ AHL_ELCB SG_ 1027 SystmStat_SpplyVltgVal_HLS_RH 1;
BA_REL_ "GenSigTimeoutTime" BU_SG_REL_ AHL_ELCB SG_ 1027 SystmStat_SpplyVltgVal_HLS_RH 250;
BA_REL_ "GenSigTimeoutMsg" BU_SG_REL_ AHL_ELCB SG_ 1027 SystmStat_ExtTempVal_HLS_RH 1027;
BA_REL_ "GenSigSuprvResp" BU_SG_REL_ AHL_ELCB SG_ 1027 SystmStat_ExtTempVal_HLS_RH 1;
BA_REL_ "GenSigTimeoutTime" BU_SG_REL_ AHL_ELCB SG_ 1027 SystmStat_ExtTempVal_HLS_RH 250;
BA_REL_ "GenSigTimeoutMsg" BU_SG_REL_ AHL_ELCB SG_ 1027 SystmStat_IntTempVal_HLS_RH 1027;
BA_REL_ "GenSigSuprvResp" BU_SG_REL_ AHL_ELCB SG_ 1027 SystmStat_IntTempVal_HLS_RH 1;
BA_REL_ "GenSigTimeoutTime" BU_SG_REL_ AHL_ELCB SG_ 1027 SystmStat_IntTempVal_HLS_RH 250;
BA_REL_ "GenSigTimeoutMsg" BU_SG_REL_ AHL_ELCB SG_ 1027 SystmStat_RefrncRunStat_HLS_RH 1027;
BA_REL_ "GenSigSuprvResp" BU_SG_REL_ AHL_ELCB SG_ 1027 SystmStat_RefrncRunStat_HLS_RH 1;
BA_REL_ "GenSigTimeoutTime" BU_SG_REL_ AHL_ELCB SG_ 1027 SystmStat_RefrncRunStat_HLS_RH 250;
BA_REL_ "GenSigTimeoutMsg" BU_SG_REL_ AHL_ELCB SG_ 1027 SystmStat_DertngStat_HLS_RH 1027;
BA_REL_ "GenSigSuprvResp" BU_SG_REL_ AHL_ELCB SG_ 1027 SystmStat_DertngStat_HLS_RH 1;
BA_REL_ "GenSigTimeoutTime" BU_SG_REL_ AHL_ELCB SG_ 1027 SystmStat_DertngStat_HLS_RH 250;
BA_REL_ "GenSigTimeoutMsg" BU_SG_REL_ AHL_ELCB SG_ 1027 SystmStat_SysCalibStat_HLS_RH 1027;
BA_REL_ "GenSigSuprvResp" BU_SG_REL_ AHL_ELCB SG_ 1027 SystmStat_SysCalibStat_HLS_RH 1;
BA_REL_ "GenSigTimeoutTime" BU_SG_REL_ AHL_ELCB SG_ 1027 SystmStat_SysCalibStat_HLS_RH 250;
BA_REL_ "GenSigTimeoutMsg" BU_SG_REL_ AHL_ELCB SG_ 1027 SystmStat_VINStat_HLS_RH 1027;
BA_REL_ "GenSigSuprvResp" BU_SG_REL_ AHL_ELCB SG_ 1027 SystmStat_VINStat_HLS_RH 1;
BA_REL_ "GenSigTimeoutTime" BU_SG_REL_ AHL_ELCB SG_ 1027 SystmStat_VINStat_HLS_RH 250;
BA_REL_ "GenSigTimeoutMsg" BU_SG_REL_ AHL_ELCB SG_ 1554 LftHdlmpLvllngActPstn 1554;
BA_REL_ "GenSigSuprvResp" BU_SG_REL_ AHL_ELCB SG_ 1554 LftHdlmpLvllngActPstn 1;
BA_REL_ "GenSigTimeoutTime" BU_SG_REL_ AHL_ELCB SG_ 1554 LftHdlmpLvllngActPstn 250;
BA_REL_ "GenSigTimeoutMsg" BU_SG_REL_ AHL_ELCB SG_ 1555 RtHdlmpLvllngActPstn 1555;
BA_REL_ "GenSigSuprvResp" BU_SG_REL_ AHL_ELCB SG_ 1555 RtHdlmpLvllngActPstn 1;
BA_REL_ "GenSigTimeoutTime" BU_SG_REL_ AHL_ELCB SG_ 1555 RtHdlmpLvllngActPstn 250;
VAL_ 511 HdlmpLvlgMtrRtDir 1 "Count Clockwise" 0 "Clockwise" ;
VAL_ 511 HdlmpLvlgMtrLtDir 1 "Count Clockwise" 0 "Clockwise" ;
VAL_ 258 LH_GFA1_Prsnc 0 "no object" 1 "object present" ;
VAL_ 259 RH_GFA1_Prsnc 0 "no object" 1 "object present" ;
VAL_ 260 LH_GFA2_Prsnc 0 "no object" 1 "object present" ;
VAL_ 261 RH_GFA2_Prsnc 0 "no object" 1 "object present" ;
VAL_ 262 LH_GFA3_Prsnc 0 "no object" 1 "object present" ;
VAL_ 263 RH_GFA3_Prsnc 0 "no object" 1 "object present" ;
VAL_ 264 LH_GFA4_Prsnc 0 "no object" 1 "object present" ;
VAL_ 265 RH_GFA4_Prsnc 0 "no object" 1 "object present" ;
VAL_ 266 LH_GFA5_Prsnc 0 "no object" 1 "object present" ;
VAL_ 267 RH_GFA5_Prsnc 0 "no object" 1 "object present" ;
VAL_ 268 LH_GFA6_Prsnc 0 "no object" 1 "object present" ;
VAL_ 269 RH_GFA6_Prsnc 0 "no object" 1 "object present" ;
VAL_ 270 LH_GFA7_Prsnc 0 "no object" 1 "object present" ;
VAL_ 271 RH_GFA7_Prsnc 0 "no object" 1 "object present" ;
VAL_ 272 LH_GFA8_Prsnc 0 "no object" 1 "object present" ;
VAL_ 273 RH_GFA8_Prsnc 0 "no object" 1 "object present" ;
VAL_ 513 HLS_LftHdlmpLvllngStat 0 "Normal Operation" 1 "Failsafe Position 1" 2 "Failsafe Position 2" 3 "Reserved" ;
VAL_ 513 HLS_RghtHdlmpLvllngStat 0 "Normal Operation" 1 "Failsafe Position 1" 2 "Failsafe Position 2" 3 "Reserved" ;
VAL_ 525 RfrncRun 0 "No Reference Run" 1 "Perform Reference Run" ;
VAL_ 525 TrffcMd 0 "Right Hand Traffic" 1 "Left Hand Traffic" ;
VAL_ 525 TourstMd 0 "Deactive" 1 "Active" ;
VAL_ 515 SlpRdy 0 "active mode" 1 "sleep ready" ;
VAL_ 515 LghtDstrbtnSelt 0 "no value" 1 "Town light" 2 "country light" 3 "motorway light" 4 "ECO mode" 5 "Reversing mode" 6 "Left corner mode" 7 "Right corner mode" 8 "Reserved 8" 9 "Reserved 9" 10 "Reserved A" 11 "Reserved B" 12 "Reserved C" 13 "Reserved D" 14 "Reserved E" 15 "Reserved F" ;
VAL_ 515 HbMdSelt 0 "deactive" 1 "manual highbeam active" 2 "flash to pass active" 3 "glare free high beam active" 4 "Reserved 4" 5 "Reserved 5" 6 "Reserved 6" 7 "Reserved 7" ;
VAL_ 1026 SystmStat_ShrtCirctFail_HLS_LH 0 "FALSE" 1 "TRUE" ;
VAL_ 1026 SystmStat_OpnLoadFail_HLS_LH 0 "FALSE" 1 "TRUE" ;
VAL_ 1026 SystmStat_IntrnlSysFail_HLS_LH 0 "FALSE" 1 "TRUE" ;
VAL_ 1026 SystmStat_OvrVltgFail_HLS_LH 0 "FALSE" 1 "TRUE" ;
VAL_ 1026 SystmStat_UndVltgFail_HLS_LH 0 "FALSE" 1 "TRUE" ;
VAL_ 1026 SystmStat_ActutorFail_HLS_LH 0 "FALSE" 1 "TRUE" ;
VAL_ 1026 SystmStat_IntnlTempFail_HLS_LH 0 "FALSE" 1 "TRUE" ;
VAL_ 1026 SystmStat_ExtTempFail_HLS_LH 0 "FALSE" 1 "TRUE" ;
VAL_ 1026 SystmStat_CurntCdngFail_HLS_LH 0 "FALSE" 1 "TRUE" ;
VAL_ 1026 SystmStat_FanFail_HLS_LH 0 "FALSE" 1 "TRUE" ;
VAL_ 1026 SystmStat_MstrMsgFail_HLS_LH 0 "FALSE" 1 "TRUE" ;
VAL_ 1026 SystmStat_OverTempFail_HLS_LH 0 "FALSE" 1 "TRUE" ;
VAL_ 1026 SystmStat_IncCompFail_HLS_LH 0 "FALSE" 1 "TRUE" ;
VAL_ 1026 SystmStat_CSorMCFail_HLS_LH 0 "FALSE" 1 "TRUE" ;
VAL_ 1026 SystmStat_R_L_DtctnFail_HLS_LH 0 "FALSE" 1 "TRUE" ;
VAL_ 1026 SystmStat_FnctnStat_HLS_LH 0 "FALSE" 1 "TRUE" ;
VAL_ 1026 SystmStat_RefrncRunStat_HLS_LH 0 "Not Performed" 1 "Still Ongoing" 2 "Is Performed" 3 "Not Supported" ;
VAL_ 1026 SystmStat_DertngStat_HLS_LH 0 "Deactive" 1 "Active" 2 "Reserved" 3 "Not Supported" ;
VAL_ 1026 SystmStat_SysCalibStat_HLS_LH 0 "Not Calibrated" 1 "Calibrated" 2 "Reserved" 3 "Not Supported" ;
VAL_ 1026 SystmStat_VINStat_HLS_LH 0 "Not Available" 1 "Available" ;
VAL_ 1027 SystmStat_ShrtCirctFail_HLS_RH 0 "FALSE" 1 "TRUE" ;
VAL_ 1027 SystmStat_OpnLoadFail_HLS_RH 0 "FALSE" 1 "TRUE" ;
VAL_ 1027 SystmStat_IntrnlSysFail_HLS_RH 0 "FALSE" 1 "TRUE" ;
VAL_ 1027 SystmStat_OvrVltgFail_HLS_RH 0 "FALSE" 1 "TRUE" ;
VAL_ 1027 SystmStat_UndVltgFail_HLS_RH 0 "FALSE" 1 "TRUE" ;
VAL_ 1027 SystmStat_ActutorFail_HLS_RH 0 "FALSE" 1 "TRUE" ;
VAL_ 1027 SystmStat_IntnlTempFail_HLS_RH 0 "FALSE" 1 "TRUE" ;
VAL_ 1027 SystmStat_ExtTempFail_HLS_RH 0 "FALSE" 1 "TRUE" ;
VAL_ 1027 SystmStat_CurntCdngFail_HLS_RH 0 "FALSE" 1 "TRUE" ;
VAL_ 1027 SystmStat_FanFail_HLS_RH 0 "FALSE" 1 "TRUE" ;
VAL_ 1027 SystmStat_MstrMsgFail_HLS_RH 0 "FALSE" 1 "TRUE" ;
VAL_ 1027 SystmStat_OverTempFail_HLS_RH 0 "FALSE" 1 "TRUE" ;
VAL_ 1027 SystmStat_IncCompFail_HLS_RH 0 "FALSE" 1 "TRUE" ;
VAL_ 1027 SystmStat_CSorMCFail_HLS_RH 0 "FALSE" 1 "TRUE" ;
VAL_ 1027 SystmStat_R_L_DtctnFail_HLS_RH 0 "FALSE" 1 "TRUE" ;
VAL_ 1027 SystmStat_FnctnStat_HLS_RH 0 "FALSE" 1 "TRUE" ;
VAL_ 1027 SystmStat_RefrncRunStat_HLS_RH 0 "Not Performed" 1 "Still Ongoing" 2 "Is Performed" 3 "Not Supported" ;
VAL_ 1027 SystmStat_DertngStat_HLS_RH 0 "Deactive" 1 "Active" 2 "Reserved" 3 "Not Supported" ;
VAL_ 1027 SystmStat_SysCalibStat_HLS_RH 0 "Not Calibrated" 1 "Calibrated" 2 "Reserved" 3 "Not Supported" ;
VAL_ 1027 SystmStat_VINStat_HLS_RH 0 "Not Available" 1 "Available" ;
VAL_ 1552 LftHdlmpLgtShowWrkSts 0 "NoShow" 1 "Mode1" 2 "Mode2" 3 "Mode3" 4 "Mode4" 5 "Mode5" 6 "Mode6" 7 "Mode7" 8 "Mode8" 9 "Mode9" 10 "Mode10" 11 "Mode11" 12 "Mode12" 13 "Mode13" 14 "Mode14" 15 "Mode15" 16 "Mode16" 17 "Mode17" 18 "Mode18" 19 "Mode19" 20 "Mode20" 21 "Mode21" 22 "Mode22" 23 "Mode23" 24 "Mode24" 25 "Mode25" 26 "Mode26" 27 "Mode27" 28 "Mode28" 29 "Mode29" 30 "Mode30" 31 "Mode31" ;
VAL_ 1552 LftLwBmCtrlSts 0 "off" 1 "on" 2 "fail off" 3 "light show" 4 "ECO mode" 5 "IO control mode1" 6 "IO control mode2" 7 "IO control mode3" ;
VAL_ 1552 LftHgBmCtrlSts 0 "off" 1 "on" 2 "fail off" 3 "light show" 4 "GFHB mode" 5 "IO control mode1" 6 "IO control mode2" 7 "IO control mode3" ;
VAL_ 1552 LftBndCtrlSts 0 "Off" 1 "On" ;
VAL_ 1552 LftFrtTrnCtrlSts 0 "off" 1 "Hazed turn process" 2 "fail off" 3 "Light show" 4 "Swipe turn Process" 5 "IO control mode1" 6 "IO control mode2" 7 "IO control mode3" ;
VAL_ 1552 LftDrlPlCtrlSts 0 "off" 1 "DRL  on" 2 "fail off" 3 "Light show" 4 "PL On" 5 "IO control mode1" 6 "IO control mode2" 7 "IO control mode3" ;
VAL_ 1552 LftAuxLbCtrlSts 0 "off" 1 "on" 2 "fail off" 3 "light show" 4 "ECO mode" 5 "IO control mode1" 6 "IO control mode2" 7 "IO control mode3" ;
VAL_ 1552 LftAuxDrlPlCtrlSts 0 "off" 1 "DRL  on" 2 "fail off" 3 "Light show" 4 "PL On" 5 "IO control mode1" 6 "IO control mode2" 7 "IO control mode3" ;
VAL_ 1552 LftLdmConf 0 "Unknown" 1 "high version headlamp" 2 "medium version headlamp" 3 "base version headlamp" ;
VAL_ 1553 RtHdlmpLgtShowWrkSts 0 "NoShow" 1 "Mode1" 2 "Mode2" 3 "Mode3" 4 "Mode4" 5 "Mode5" 6 "Mode6" 7 "Mode7" 8 "Mode8" 9 "Mode9" 10 "Mode10" 11 "Mode11" 12 "Mode12" 13 "Mode13" 14 "Mode14" 15 "Mode15" 16 "Mode16" 17 "Mode17" 18 "Mode18" 19 "Mode19" 20 "Mode20" 21 "Mode21" 22 "Mode22" 23 "Mode23" 24 "Mode24" 25 "Mode25" 26 "Mode26" 27 "Mode27" 28 "Mode28" 29 "Mode29" 30 "Mode30" 31 "Mode31" ;
VAL_ 1553 RtLwBmCtrlSts 0 "off" 1 "on" 2 "fail off" 3 "light show" 4 "ECO mode" 5 "IO control mode1" 6 "IO control mode2" 7 "IO control mode3" ;
VAL_ 1553 RtHgBmCtrlSts 0 "off" 1 "on" 2 "fail off" 3 "light show" 4 "GFHB mode" 5 "IO control mode1" 6 "IO control mode2" 7 "IO control mode3" ;
VAL_ 1553 RtBndCtrlSts 0 "Off" 1 "On" ;
VAL_ 1553 RtFrtTrnCtrlSts 0 "off" 1 "Hazed turn process" 2 "fail off" 3 "Light show" 4 "Swipe turn Process" 5 "IO control mode1" 6 "IO control mode2" 7 "IO control mode3" ;
VAL_ 1553 RtDrlPlCtrlSts 0 "off" 1 "DRL  on" 2 "fail off" 3 "Light show" 4 "PL On" 5 "IO control mode1" 6 "IO control mode2" 7 "IO control mode3" ;
VAL_ 1553 RtAuxLbCtrlSts 0 "off" 1 "on" 2 "fail off" 3 "light show" 4 "ECO mode" 5 "IO control mode1" 6 "IO control mode2" 7 "IO control mode3" ;
VAL_ 1553 RtAuxDrlPlCtrlSts 0 "off" 1 "DRL  on" 2 "fail off" 3 "Light show" 4 "PL On" 5 "IO control mode1" 6 "IO control mode2" 7 "IO control mode3" ;
VAL_ 1553 RtLdmConf 0 "Unknown" 1 "high version headlamp" 2 "medium version headlamp" 3 "base version headlamp" ;
VAL_ 1556 SysOvErrLH 0 "normal/not support" 1 "fail" ;
VAL_ 1556 SysUvErrLH 0 "normal/not support" 1 "fail" ;
VAL_ 1556 BstErrLH 0 "normal/not support" 1 "fail" ;
VAL_ 1556 UartCan2ErrLH 0 "normal/not support" 1 "Tx fail" 2 "RxFail" ;
VAL_ 1556 UartCan1ErrLH 0 "normal/not support" 1 "Tx fail" 2 "RxFail" ;
VAL_ 1556 PwrCh9ErrLH 0 "normal/not support" 1 "fail" ;
VAL_ 1556 Bin8ErrLH 0 "normal/not support" 1 "fail" ;
VAL_ 1556 Bin7ErrLH 0 "normal/not support" 1 "fail" ;
VAL_ 1556 Bin6ErrLH 0 "normal/not support" 1 "fail" ;
VAL_ 1556 Bin5ErrLH 0 "normal/not support" 1 "fail" ;
VAL_ 1556 Bin4ErrLH 0 "normal/not support" 1 "fail" ;
VAL_ 1556 Bin3ErrLH 0 "normal/not support" 1 "fail" ;
VAL_ 1556 Bin2ErrLH 0 "normal/not support" 1 "fail" ;
VAL_ 1556 Bin1ErrLH 0 "normal/not support" 1 "fail" ;
VAL_ 1556 Ntc8ErrLH 0 "normal/not support" 1 "fail" ;
VAL_ 1556 Ntc7ErrLH 0 "normal/not support" 1 "fail" ;
VAL_ 1556 Ntc6ErrLH 0 "normal/not support" 1 "fail" ;
VAL_ 1556 Ntc5ErrLH 0 "normal/not support" 1 "fail" ;
VAL_ 1556 Ntc4ErrLH 0 "normal/not support" 1 "fail" ;
VAL_ 1556 Ntc3ErrLH 0 "normal/not support" 1 "fail" ;
VAL_ 1556 Ntc2ErrLH 0 "normal/not support" 1 "fail" ;
VAL_ 1556 Ntc1ErrLH 0 "normal/not support" 1 "fail" ;
VAL_ 1556 PwrCh1ErrLH 0 "normal/not support" 1 "fail" ;
VAL_ 1556 PwrCh2ErrLH 0 "normal/not support" 1 "fail" ;
VAL_ 1556 PwrCh3ErrLH 0 "normal/not support" 1 "fail" ;
VAL_ 1556 PwrCh4ErrLH 0 "normal/not support" 1 "fail" ;
VAL_ 1556 PwrCh5ErrLH 0 "normal/not support" 1 "fail" ;
VAL_ 1556 PwrCh6ErrLH 0 "normal/not support" 1 "fail" ;
VAL_ 1556 PwrCh7ErrLH 0 "normal/not support" 1 "fail" ;
VAL_ 1556 PwrCh8ErrLH 0 "normal/not support" 1 "fail" ;
VAL_ 1556 Can1BusOffLH 0 "normal/not support" 1 "fail" ;
VAL_ 1556 Can1N1LstLH 0 "normal/not support" 1 "fail" ;
VAL_ 1556 Can1N2LstLH 0 "normal/not support" 1 "fail" ;
VAL_ 1556 Can1N3LstLH 0 "normal/not support" 1 "fail" ;
VAL_ 1556 Can1N1SigErrLH 0 "normal/not support" 1 "fail" ;
VAL_ 1556 Can1N2SigErrLH 0 "normal/not support" 1 "fail" ;
VAL_ 1556 Can1N3SigErrLH 0 "normal/not support" 1 "fail" ;
VAL_ 1556 Can2N7LstErrLH 0 "normal/not support" 1 "fail" ;
VAL_ 1556 Can2N6LstErrLH 0 "normal/not support" 1 "fail" ;
VAL_ 1556 Can2N5LstErrLH 0 "normal/not support" 1 "fail" ;
VAL_ 1556 Can2N4LstErrLH 0 "normal/not support" 1 "fail" ;
VAL_ 1556 Can2N3LstErrLH 0 "normal/not support" 1 "fail" ;
VAL_ 1556 Can2N2LstErrLH 0 "normal/not support" 1 "fail" ;
VAL_ 1556 Can2N1LstErrLH 0 "normal/not support" 1 "fail" ;
VAL_ 1556 Can2N0LstErrLH 0 "normal/not support" 1 "fail" ;
VAL_ 1556 Can2N7LedErrLH 0 "normal/not support" 1 "fail" ;
VAL_ 1556 Can2N6LedErrLH 0 "normal/not support" 1 "fail" ;
VAL_ 1556 Can2N5LedErrLH 0 "normal/not support" 1 "fail" ;
VAL_ 1556 Can2N4LedErrLH 0 "normal/not support" 1 "fail" ;
VAL_ 1556 Can2N3LedErrLH 0 "normal/not support" 1 "fail" ;
VAL_ 1556 Can2N2LedErrLH 0 "normal/not support" 1 "fail" ;
VAL_ 1556 Can2N1LedErrLH 0 "normal/not support" 1 "fail" ;
VAL_ 1556 Can2N0LedErrLH 0 "normal/not support" 1 "fail" ;
VAL_ 1557 SysOvErrRH 0 "normal/not support" 1 "fail" ;
VAL_ 1557 SysUvErrRH 0 "normal/not support" 1 "fail" ;
VAL_ 1557 BstErrRH 0 "normal/not support" 1 "fail" ;
VAL_ 1557 UartCan2ErrRH 0 "normal/not support" 1 "Tx fail" 2 "RxFail" ;
VAL_ 1557 UartCan1ErrRH 0 "normal/not support" 1 "Tx fail" 2 "RxFail" ;
VAL_ 1557 PwrCh9ErrRH 0 "normal/not support" 1 "fail" ;
VAL_ 1557 Bin8ErrRH 0 "normal/not support" 1 "fail" ;
VAL_ 1557 Bin7ErrRH 0 "normal/not support" 1 "fail" ;
VAL_ 1557 Bin6ErrRH 0 "normal/not support" 1 "fail" ;
VAL_ 1557 Bin5ErrRH 0 "normal/not support" 1 "fail" ;
VAL_ 1557 Bin4ErrRH 0 "normal/not support" 1 "fail" ;
VAL_ 1557 Bin3ErrRH 0 "normal/not support" 1 "fail" ;
VAL_ 1557 Bin2ErrRH 0 "normal/not support" 1 "fail" ;
VAL_ 1557 Bin1ErrRH 0 "normal/not support" 1 "fail" ;
VAL_ 1557 Ntc8ErrRH 0 "normal/not support" 1 "fail" ;
VAL_ 1557 Ntc7ErrRH 0 "normal/not support" 1 "fail" ;
VAL_ 1557 Ntc6ErrRH 0 "normal/not support" 1 "fail" ;
VAL_ 1557 Ntc5ErrRH 0 "normal/not support" 1 "fail" ;
VAL_ 1557 Ntc4ErrRH 0 "normal/not support" 1 "fail" ;
VAL_ 1557 Ntc3ErrRH 0 "normal/not support" 1 "fail" ;
VAL_ 1557 Ntc2ErrRH 0 "normal/not support" 1 "fail" ;
VAL_ 1557 Ntc1ErrRH 0 "normal/not support" 1 "fail" ;
VAL_ 1557 PwrCh1ErrRH 0 "normal/not support" 1 "fail" ;
VAL_ 1557 PwrCh2ErrRH 0 "normal/not support" 1 "fail" ;
VAL_ 1557 PwrCh3ErrRH 0 "normal/not support" 1 "fail" ;
VAL_ 1557 PwrCh4ErrRH 0 "normal/not support" 1 "fail" ;
VAL_ 1557 PwrCh5ErrRH 0 "normal/not support" 1 "fail" ;
VAL_ 1557 PwrCh6ErrRH 0 "normal/not support" 1 "fail" ;
VAL_ 1557 PwrCh7ErrRH 0 "normal/not support" 1 "fail" ;
VAL_ 1557 PwrCh8ErrRH 0 "normal/not support" 1 "fail" ;
VAL_ 1557 Can1BusOffRH 0 "normal/not support" 1 "fail" ;
VAL_ 1557 Can1N1LstRH 0 "normal/not support" 1 "fail" ;
VAL_ 1557 Can1N2LstRH 0 "normal/not support" 1 "fail" ;
VAL_ 1557 Can1N3LstRH 0 "normal/not support" 1 "fail" ;
VAL_ 1557 Can1N1SigErrRH 0 "normal/not support" 1 "fail" ;
VAL_ 1557 Can1N2SigErrRH 0 "normal/not support" 1 "fail" ;
VAL_ 1557 Can1N3SigErrRH 0 "normal/not support" 1 "fail" ;
VAL_ 1557 Can2N7LstErrRH 0 "normal/not support" 1 "fail" ;
VAL_ 1557 Can2N6LstErrRH 0 "normal/not support" 1 "fail" ;
VAL_ 1557 Can2N5LstErrRH 0 "normal/not support" 1 "fail" ;
VAL_ 1557 Can2N4LstErrRH 0 "normal/not support" 1 "fail" ;
VAL_ 1557 Can2N3LstErrRH 0 "normal/not support" 1 "fail" ;
VAL_ 1557 Can2N2LstErrRH 0 "normal/not support" 1 "fail" ;
VAL_ 1557 Can2N1LstErrRH 0 "normal/not support" 1 "fail" ;
VAL_ 1557 Can2N0LstErrRH 0 "normal/not support" 1 "fail" ;
VAL_ 1557 Can2N7LedErrRH 0 "normal/not support" 1 "fail" ;
VAL_ 1557 Can2N6LedErrRH 0 "normal/not support" 1 "fail" ;
VAL_ 1557 Can2N5LedErrRH 0 "normal/not support" 1 "fail" ;
VAL_ 1557 Can2N4LedErrRH 0 "normal/not support" 1 "fail" ;
VAL_ 1557 Can2N3LedErrRH 0 "normal/not support" 1 "fail" ;
VAL_ 1557 Can2N2LedErrRH 0 "normal/not support" 1 "fail" ;
VAL_ 1557 Can2N1LedErrRH 0 "normal/not support" 1 "fail" ;
VAL_ 1557 Can2N0LedErrRH 0 "normal/not support" 1 "fail" ;
VAL_ 393 FrtLtShwMode 0 "NoActive" 1 "Mode1-Breath off" 2 "Mode2-Abort" 3 "Mode3-unlock day" 4 "Mode4-unlock night" 5 "Mode5-Lock day" 6 "Mode6-Lock night" 7 "Mode7" 8 "Mode8-Follow Me Home" 9 "Mode9" 10 "Mode10" 11 "Mode11" 12 "Mode12" 13 "Mode13" 14 "Mode14" 15 "Mode15" 16 "Mode16" 17 "Mode17" 18 "Mode18" 19 "Mode19" 20 "Mode20" 21 "Mode21" 22 "Mode22" 23 "Mode23" 24 "Mode24" 25 "Mode25" 26 "Mode26" 27 "Mode27" 28 "Mode28" 29 "Mode29" 30 "Mode30" 31 "Mode31" ;
VAL_ 393 FrtLtShwType 0 "Not active" 1 "Type1-OFF" 2 "Type2-Simple" 3 "Type3-Complex" 4 "Type4" 5 "Type5" 6 "Type6" 7 "Type7" ;
VAL_ 390 LftDRLCmd 0 "No Action" 1 "Normal On" 2 "Normal Off" 3 "Ramp On" 4 "Ramp Off" 5 "Swipe On" 6 "Swipe Off" 7 "Reversed" ;
VAL_ 390 RtDRLCmd 0 "No Action" 1 "Normal On" 2 "Normal Off" 3 "Ramp On" 4 "Ramp Off" 5 "Swipe On" 6 "Swipe Off" 7 "Reversed" ;
VAL_ 390 LftPrkLmpCmd 0 "No Action" 1 "Normal On" 2 "Normal Off" 3 "Ramp On" 4 "Ramp Off" 5 "Swipe On" 6 "Swipe Off" 7 "Reversed" ;
VAL_ 390 RtPrkLmpCmd 0 "No Action" 1 "Normal On" 2 "Normal Off" 3 "Ramp On" 4 "Ramp Off" 5 "Swipe On" 6 "Swipe Off" 7 "Reversed" ;
VAL_ 390 LftFrtTrnLmpCmd 0 "Not active" 1 "swipe turn" 2 "Normal flash" 3 "hold on light" 4 "reserved" 5 "reserved" ;
VAL_ 390 RtFrtTrnLmpCmd 0 "Not active" 1 "swipe turn" 2 "Normal flash" 3 "hold on light" 4 "reserved" 5 "reserved" ;
VAL_ 391 LftLowBmCmd 0 "No Action" 1 "Normal On" 2 "Normal Off" 3 "Ramp On" 4 "Ramp Off" 5 "Swipe On" 6 "Swipe Off" 7 "Reversed" ;
VAL_ 391 RtLowBmCmd 0 "No Action" 1 "Normal On" 2 "Normal Off" 3 "Ramp On" 4 "Ramp Off" 5 "Swipe On" 6 "Swipe Off" 7 "Reversed" ;
VAL_ 391 LftHiBmCmd 0 "No Action" 1 "Normal On" 2 "Normal Off" 3 "Ramp On" 4 "Ramp Off" 5 "Swipe On" 6 "Swipe Off" 7 "Reversed" ;
VAL_ 391 RtHiBmCmd 0 "No Action" 1 "Normal On" 2 "Normal Off" 3 "Ramp On" 4 "Ramp Off" 5 "Swipe On" 6 "Swipe Off" 7 "Reversed" ;
